VERSION ""

NS_ :

BS_:

BU_: SOBDMB_AWDC BCMC_CPDB BECMB_EPM PACM GWM _delete BCM ACCM DCDC_HEV GENERIC TSTR

BO_ 753 Vehicle_Stat_Data: 8 GWM
 SG_ EdmSailMde_B_RqDrv_UB : 34|1@0+ (1,0) [0|1] "SED" Vector__XXX
 SG_ TurnLampRrOut_B_Stat_UB : 36|1@0+ (1,0) [0|1] "SED"  BCM
 SG_ TurnLampRrOut_B_Stat : 37|1@0+ (1,0) [0|1] "SED"  BCM
 SG_ TurnLampRlOut_B_Stat_UB : 38|1@0+ (1,0) [0|1] "SED"  BCM
 SG_ TurnLampRlOut_B_Stat : 39|1@0+ (1,0) [0|1] "SED"  BCM
 SG_ CnvtTopPos_Up_Stat_UB : 24|1@0+ (1,0) [0|1] "SED"  BCM
 SG_ GlvBoxRleas_No_Actl : 31|3@0+ (1,0) [0|7] "unitless"  BCM
 SG_ GlvBoxRleas_No_Actl_UB : 28|1@0+ (1,0) [0|1] "SED"  BCM
 SG_ ValetMode_D_Stat_UB : 20|1@0+ (1,0) [0|1] "SED"  BCM
 SG_ RollCodeValet_UB : 21|1@0+ (1,0) [0|1] "SED"  BCM
 SG_ ApaMdeStat_D_RqDrv_UB : 16|1@0+ (1,0) [0|1] "SED" Vector__XXX
 SG_ EdmSailMde_B_RqDrv : 35|1@0+ (1,0) [0|1] "SED" Vector__XXX
 SG_ LpdbPtc3_B_Rq : 42|1@0+ (1,0) [0|1] "SED"  BCM
 SG_ LpdbPtc2_B_Rq : 43|1@0+ (1,0) [0|1] "SED"  BCM
 SG_ LpdbPtc1_B_Rq : 44|1@0+ (1,0) [0|1] "SED"  BCM
 SG_ Em_D_Stat_UB : 54|1@0+ (1,0) [0|1] "SED"  BCM
 SG_ LpdbHeatWiprPrk_B_Rq : 45|1@0+ (1,0) [0|1] "SED"  BCM
 SG_ LpdbDfrstRearOn_B_Rq_UB : 41|1@0+ (1,0) [0|1] "SED"  BCM
 SG_ LpdbDfrstRearOn_B_Rq : 46|1@0+ (1,0) [0|1] "SED"  BCM
 SG_ LpdbDfrstFrOn_B_Rq : 47|1@0+ (1,0) [0|1] "SED"  BCM
 SG_ LpdbDfrstFlOn_B_Rq : 32|1@0+ (1,0) [0|1] "SED"  BCM
 SG_ LpdbAuxBlwr_B_Rq : 33|1@0+ (1,0) [0|1] "SED"  BCM
 SG_ ApaMdeStat_D_RqDrv : 19|3@0+ (1,0) [0|7] "SED" Vector__XXX
 SG_ Em_D_Stat : 40|2@0+ (1,0) [0|3] "SED"  BCM
 SG_ PrkAidSwtch_No_Cnt : 52|4@0+ (1,0) [0|15] "Unitless" Vector__XXX
 SG_ PrkAidSwtch_D_RqDrv : 53|1@0+ (1,0) [0|1] "SED" Vector__XXX
 SG_ PrkAidSwtch_D_RqDrv_UB : 48|1@0+ (1,0) [0|1] "SED" Vector__XXX
 SG_ ValetMode_D_Stat : 23|2@0+ (1,0) [0|3] "SED"  BCM
 SG_ RollCodeValet : 7|16@0+ (1,0) [0|65535] "Unitless"  BCM
 SG_ CnvtTopPos_Up_Stat : 25|1@0+ (1,0) [0|1] "SED"  BCM
 SG_ CnvtTopPos_Dn_Stat_UB : 26|1@0+ (1,0) [0|1] "SED"  BCM
 SG_ CnvtTopPos_Dn_Stat : 27|1@0+ (1,0) [0|1] "SED"  BCM

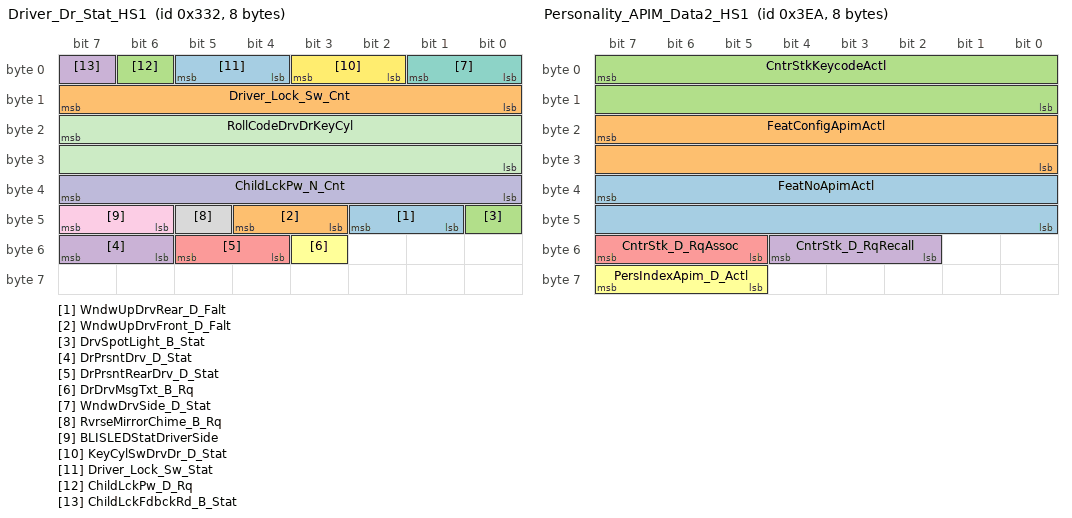
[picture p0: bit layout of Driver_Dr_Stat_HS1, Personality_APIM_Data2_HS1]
BO_ 818 Driver_Dr_Stat_HS1: 8 GWM
 SG_ WndwUpDrvRear_D_Falt : 42|2@0+ (1,0) [0|3] "SED"  GENERIC
 SG_ WndwUpDrvFront_D_Falt : 44|2@0+ (1,0) [0|3] "SED"  GENERIC
 SG_ DrvSpotLight_B_Stat : 40|1@0+ (1,0) [0|1] "SED"  GENERIC
 SG_ DrPrsntDrv_D_Stat : 55|2@0+ (1,0) [0|3] "SED" Vector__XXX
 SG_ DrPrsntRearDrv_D_Stat : 53|2@0+ (1,0) [0|3] "SED" Vector__XXX
 SG_ DrDrvMsgTxt_B_Rq : 51|1@0+ (1,0) [0|1] "SED"  GENERIC
 SG_ WndwDrvSide_D_Stat : 1|2@0+ (1,0) [0|3] "SED"  GENERIC
 SG_ RvrseMirrorChime_B_Rq : 45|1@0+ (1,0) [0|1] "SED"  GENERIC
 SG_ BLISLEDStatDriverSide : 47|2@0+ (1,0) [0|3] "SED"  GENERIC
 SG_ ChildLckPw_N_Cnt : 39|8@0+ (1,0) [0|255] "unitless"  BCM
 SG_ RollCodeDrvDrKeyCyl : 23|16@0+ (1,0) [0|65535] "Unitless"  BCM
 SG_ KeyCylSwDrvDr_D_Stat : 3|2@0+ (1,0) [0|3] "SED"  BCM
 SG_ Driver_Lock_Sw_Stat : 5|2@0+ (1,0) [0|3] "SED"  BCM
 SG_ Driver_Lock_Sw_Cnt : 15|8@0+ (1,0) [0|255] "Cnt"  BCM
 SG_ ChildLckPw_D_Rq : 6|1@0+ (1,0) [0|1] "SED"  BCM
 SG_ ChildLckFdbckRd_B_Stat : 7|1@0+ (1,0) [0|1] "SED"  BCM

BO_ 817 Locking_Systems_2: 8 BCM
 SG_ ChildLckMde_B_Stat : 56|1@0+ (1,0) [0|1] "SED"  GWM
 SG_ VehLckInd_D_Rq : 58|2@0+ (1,0) [0|3] "SED"  GWM
 SG_ DrTgateOpen_B_Rq : 59|1@0+ (1,0) [0|1] "SED"  GWM
 SG_ DrTgateExtSwMde_B_Stat : 32|1@0+ (1,0) [0|1] "SED"  GWM
 SG_ Remote_Device_Feedback : 50|3@0+ (1,0) [0|7] "SED"  GWM
 SG_ Veh_Lock_Requestor : 55|5@0+ (1,0) [0|31] "SED"  GWM
 SG_ R_Pwr_Sliding_Dr_Rqst : 36|1@0+ (1,0) [0|1] "SED"  GWM
 SG_ Power_Liftgate_Rqst : 0|1@0+ (1,0) [0|1] "SED"  GWM
 SG_ Veh_Lock_EvNum : 47|8@0+ (1,0) [0|255] "unitless"  GWM
 SG_ Power_Decklid_Rqst : 1|1@0+ (1,0) [0|1] "SED"  GWM
 SG_ L_Pwr_Sliding_Dr_Rqst : 3|1@0+ (1,0) [0|1] "SED"  GWM
 SG_ Keyfob_Pad_Msg_Count : 15|8@0+ (1,0) [0|255] "Counts"  GWM
 SG_ Veh_Lock_Sub_Id : 63|4@0+ (1,0) [0|15] "SED"  GWM
 SG_ Veh_Lock_Status : 34|2@0+ (1,0) [0|3] "SED"  GWM
 SG_ ChildLck_D_Dsply : 7|2@0+ (1,0) [0|3] "SED"  GWM
 SG_ WindowLockout_B_Stat : 35|1@0+ (1,0) [0|1] "SED"  GWM
 SG_ RollCodeUnlock : 23|16@0+ (1,0) [0|65535] "Unitless"  GWM
 SG_ Lockmsgtxt_D_Rq : 39|3@0+ (1,0) [0|7] "SED"  GWM
 SG_ FobComm_D_Stat : 5|2@0+ (1,0) [0|3] "SED"  GWM
 SG_ LockInhibit : 2|1@0+ (1,0) [0|1] "SED"  GWM

BO_ 1002 Personality_APIM_Data2_HS1: 8 GWM
 SG_ FeatNoApimActl : 39|16@0+ (1,0) [0|65535] "Number"  GENERIC
 SG_ FeatConfigApimActl : 23|16@0+ (1,0) [0|65535] "Number"  GENERIC
 SG_ CntrStkKeycodeActl : 7|16@0+ (1,0) [0|65535] "Undefined"  BCM
 SG_ CntrStk_D_RqRecall : 52|3@0+ (1,0) [0|7] "SED"  BCM
 SG_ CntrStk_D_RqAssoc : 55|3@0+ (1,0) [0|7] "SED"  BCM
 SG_ PersIndexApim_D_Actl : 63|3@0+ (1,0) [0|7] "SED"  GENERIC

BO_ 1046 BrakeSysFeatures_2_HS1: 8 GWM
 SG_ BpedDiffLckTq_No_Cs : 23|8@0+ (1,0) [0|255] "Unitless" Vector__XXX
 SG_ PrkBrkDynmc_D_Allw : 39|2@0+ (1,0) [0|3] "SED"  GENERIC
 SG_ BrkPrkBrkDynmc_B_Actl : 24|1@0+ (1,0) [0|1] "SED"  GENERIC
 SG_ TRLR_SWAY_EVNT_IN_PROG : 25|1@0+ (1,0) [0|1] "SED"  GENERIC
 SG_ TRLR_SWAY_CONFIG_STAT : 26|1@0+ (1,0) [0|1] "SED"  GENERIC
 SG_ ReserveTracCtlPtActv : 28|1@0+ (1,0) [0|1] "SED"  GENERIC
 SG_ HsaMde_D_Mem : 33|2@0+ (1,0) [0|3] "SED"  GENERIC
 SG_ BrkBstrVac_B_Rq : 27|1@0+ (1,0) [0|1] "Discrete" Vector__XXX
 SG_ DrvSlipCtlMde_D_Ind : 44|2@0+ (1,0) [0|3] "SED" Vector__XXX
 SG_ DrvAntiLckLamp_D_Rq : 55|2@0+ (1,0) [0|3] "SED" Vector__XXX
 SG_ StabCtlBrk_B_Avail : 4|1@0+ (1,0) [0|1] "SED" Vector__XXX
 SG_ DrvHdcWarnInfo_D_Rq : 35|2@0+ (1,0) [0|3] "SED" Vector__XXX
 SG_ DrvHdcMsg_D_Rq : 10|3@0+ (1,0) [0|7] "SED" Vector__XXX
 SG_ DrvHdcLampInfo_D_Rq : 12|2@0+ (1,0) [0|3] "SED" Vector__XXX
 SG_ ChimeBrk_B_Rq : 14|1@0+ (1,0) [0|1] "SED" Vector__XXX
 SG_ BrkLamp_B_Rq : 13|1@0+ (1,0) [0|1] "SED" Vector__XXX
 SG_ HILL_DESC_MC : 47|3@0+ (1,0) [0|7] "SED" Vector__XXX
 SG_ RearDiffLck_Tq2_RqMx : 51|12@0+ (4,0) [0|16376] "Nm" Vector__XXX
 SG_ HdcMde_D_Actl : 31|3@0+ (1,0) [0|7] "SED" Vector__XXX
 SG_ TCMode : 15|1@0+ (1,0) [0|1] "SED" Vector__XXX
 SG_ DrvSlipCtlLamp_D_Rq : 42|2@0+ (1,0) [0|3] "SED" Vector__XXX
 SG_ Abs_B_Falt : 5|1@0+ (1,0) [0|1] "SED" Vector__XXX
 SG_ RearDiffElckrOpen_B_Rq : 40|1@0+ (1,0) [0|1] "SED"  GENERIC
 SG_ BpedMove_No_Cnt : 3|4@0+ (1,0) [0|15] "Unitless" Vector__XXX
 SG_ BpedMove_D_Actl : 7|2@0+ (1,0) [0|3] "SED" Vector__XXX

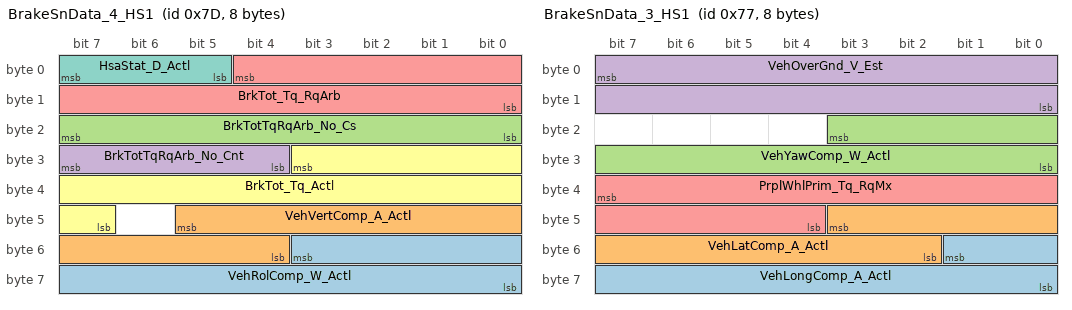
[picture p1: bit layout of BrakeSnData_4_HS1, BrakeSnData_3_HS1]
BO_ 125 BrakeSnData_4_HS1: 8 GWM
 SG_ VehRolComp_W_Actl : 51|12@0+ (0.03663,-75) [-75|74.92659] "degrees/sec" Vector__XXX
 SG_ VehVertComp_A_Actl : 45|10@0+ (0.035,-17.9) [-17.9|17.835] "m/s^2" Vector__XXX
 SG_ BrkTotTqRqArb_No_Cs : 23|8@0+ (1,0) [0|255] "Unitless" Vector__XXX
 SG_ BrkTotTqRqArb_No_Cnt : 31|4@0+ (1,0) [0|15] "Unitless" Vector__XXX
 SG_ BrkTot_Tq_RqArb : 4|13@0+ (4,0) [0|32756] "Nm" Vector__XXX
 SG_ BrkTot_Tq_Actl : 27|13@0+ (4,0) [0|32756] "Nm"  GENERIC
 SG_ HsaStat_D_Actl : 7|3@0+ (1,0) [0|7] "SED"  GENERIC

BO_ 119 BrakeSnData_3_HS1: 8 GWM
 SG_ VehLongComp_A_Actl : 49|10@0+ (0.035,-17.9) [-17.9|17.835] "m/s^2" Vector__XXX
 SG_ VehLatComp_A_Actl : 43|10@0+ (0.035,-17.9) [-17.9|17.835] "m/s^2" Vector__XXX
 SG_ VehYawComp_W_Actl : 19|12@0+ (0.03663,-75) [-75|74.92659] "deg/s" Vector__XXX
 SG_ VehOverGnd_V_Est : 7|16@0+ (0.01,0) [0|655.33] "kph" Vector__XXX
 SG_ PrplWhlPrim_Tq_RqMx : 39|12@0+ (8,0) [0|32760] "Nm"  GENERIC

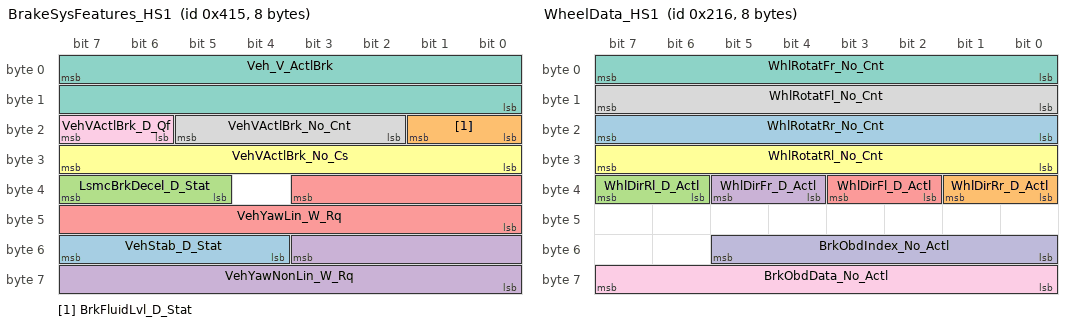
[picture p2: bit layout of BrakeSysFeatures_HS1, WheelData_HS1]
BO_ 1045 BrakeSysFeatures_HS1: 8 GWM
 SG_ VehStab_D_Stat : 55|4@0+ (1,0) [0|15] "SED" Vector__XXX
 SG_ BrkFluidLvl_D_Stat : 17|2@0+ (1,0) [0|3] "SED"  BCM
 SG_ LsmcBrkDecel_D_Stat : 39|3@0+ (1,0) [0|7] "SED"  GENERIC
 SG_ VehYawNonLin_W_Rq : 51|12@0+ (0.03663,-75) [-75|74.92659] "deg/s" Vector__XXX
 SG_ VehYawLin_W_Rq : 35|12@0+ (0.03663,-75) [-75|74.92659] "deg/s" Vector__XXX
 SG_ VehVActlBrk_No_Cs : 31|8@0+ (1,0) [0|255] "Unitless"  SOBDMB_AWDC,BCM
 SG_ Veh_V_ActlBrk : 7|16@0+ (0.01,0) [0|655.35] "kph"  SOBDMB_AWDC,BCM
 SG_ VehVActlBrk_No_Cnt : 21|4@0+ (1,0) [0|15] "Unitless"  SOBDMB_AWDC,BCM
 SG_ VehVActlBrk_D_Qf : 23|2@0+ (1,0) [0|3] "SED"  SOBDMB_AWDC,BCM

BO_ 534 WheelData_HS1: 8 GWM
 SG_ WhlRotatRr_No_Cnt : 23|8@0+ (1,0) [0|255] "Unitless"  BCM
 SG_ WhlDirRr_D_Actl : 33|2@0+ (1,0) [0|3] "SED" Vector__XXX
 SG_ WhlDirRl_D_Actl : 39|2@0+ (1,0) [0|3] "SED" Vector__XXX
 SG_ WhlDirFr_D_Actl : 37|2@0+ (1,0) [0|3] "SED" Vector__XXX
 SG_ WhlDirFl_D_Actl : 35|2@0+ (1,0) [0|3] "SED" Vector__XXX
 SG_ WhlRotatRl_No_Cnt : 31|8@0+ (1,0) [0|255] "Unitless"  BCM
 SG_ WhlRotatFr_No_Cnt : 7|8@0+ (1,0) [0|255] "Unitless"  BCM
 SG_ WhlRotatFl_No_Cnt : 15|8@0+ (1,0) [0|255] "Unitless"  BCM
 SG_ BrkObdData_No_Actl : 63|8@0+ (1,0) [0|255] "unitless" Vector__XXX
 SG_ BrkObdIndex_No_Actl : 53|6@0+ (1,0) [0|63] "unitless" Vector__XXX

BO_ 531 DesiredTorqBrk_HS1: 8 GWM
 SG_ VehStop_D_Stat : 28|2@0+ (1,0) [0|3] "SED"  GENERIC
 SG_ TracCtlPtActv_B_Actl : 31|1@0+ (1,0) [0|1] "SED"  GENERIC
 SG_ LscmbbMntr_B_Err : 17|1@0+ (1,0) [0|1] "SED"  GENERIC
 SG_ LscmbbBrkDis_B_Actl : 19|1@0+ (1,0) [0|1] "SED"  GENERIC
 SG_ StabCtlBrkActv_B_Actl : 23|1@0+ (1,0) [0|1] "SED"  GENERIC
 SG_ CmbbBrkPrchg_B_Actl : 59|1@0+ (1,0) [0|1] "SED"  GENERIC
 SG_ CmbbBrkDecel_B_Actl : 58|1@0+ (1,0) [0|1] "SED"  GENERIC
 SG_ CmbbBaSensInc_B_Actl : 57|1@0+ (1,0) [0|1] "SED"  GENERIC
 SG_ AccBrkWarm_B_Actl : 63|1@0+ (1,0) [0|1] "SED"  GENERIC
 SG_ AccBrkTotTqMn_B_Actl : 62|1@0+ (1,0) [0|1] "SED"  GENERIC
 SG_ AccBrkPrchgActv_B_Actl : 61|1@0+ (1,0) [0|1] "SED"  GENERIC
 SG_ AccBrkDis_B_Actl : 44|1@0+ (1,0) [0|1] "SED"  GENERIC
 SG_ AccBrkDeny_B_Actl : 42|1@0+ (1,0) [0|1] "SED"  GENERIC
 SG_ AccBrkActv_B_Actl : 43|1@0+ (1,0) [0|1] "SED"  GENERIC
 SG_ PrplDrgCtlActv_B_Actl : 46|1@0+ (1,0) [0|1] "SED"  GENERIC
 SG_ PrplWhlTot_Tq_RqMx : 7|16@0+ (4,-131072) [-131072|131068] "Nm"  GENERIC
 SG_ AbsActv_B_Actl : 45|1@0+ (1,0) [0|1] "SED"  SOBDMB_AWDC,GENERIC
 SG_ CmbbBrkDis_B_Actl : 56|1@0+ (1,0) [0|1] "SED"  GENERIC
 SG_ CmbbDeny_B_ActlBrk : 60|1@0+ (1,0) [0|1] "SED"  GENERIC
 SG_ CcDis_B_Cmd : 47|1@0+ (1,0) [0|1] "SED"  GENERIC
 SG_ VehLongOvrGnd_A_Est : 41|10@0+ (0.035,-17.9) [-17.9|17.835] "m/s^2"  GENERIC
 SG_ AccStopActv_B_ActlBrk : 22|1@0+ (1,0) [0|1] "SED"  GENERIC
 SG_ AccDis_B_ActlEpb : 32|1@0+ (1,0) [0|1] "SED"  GENERIC
 SG_ PrkBrkYwLamp_D_Rq : 38|2@0+ (1,0) [0|3] "SED"  GENERIC
 SG_ PrkBrkRedLamp_D_Rq : 30|2@0+ (1,0) [0|3] "SED"  GENERIC
 SG_ PrkBrkMsgTxt_D_Rq : 36|4@0+ (1,0) [0|15] "SED"  GENERIC
 SG_ PrkBrkStatus : 26|3@0+ (1,0) [0|7] "SED"  GENERIC,BCM
 SG_ VehicleStationary : 39|1@0+ (1,0) [0|1] "SED"  GENERIC
 SG_ LscmbbDeny_B_ActlBrk : 18|1@0+ (1,0) [0|1] "SED"  GENERIC
 SG_ LscmbbBrkDecel_B_Actl : 20|1@0+ (1,0) [0|1] "SED"  GENERIC
 SG_ LscmbbBaSensInc_B_Actl : 21|1@0+ (1,0) [0|1] "SED"  GENERIC
 SG_ LscmbBrkPrchg_B_Actl : 16|1@0+ (1,0) [0|1] "SED"  GENERIC

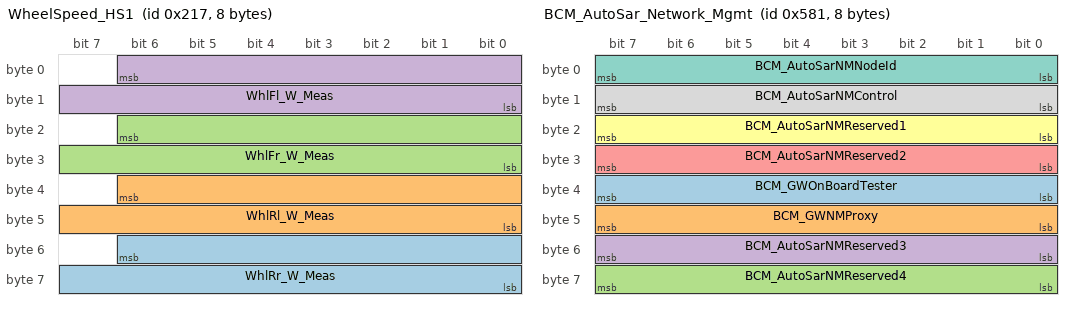
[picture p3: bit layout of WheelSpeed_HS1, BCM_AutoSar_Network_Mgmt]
BO_ 535 WheelSpeed_HS1: 8 GWM
 SG_ WhlRr_W_Meas : 54|15@0+ (0.01,0) [0|327.65] "rad/s"  SOBDMB_AWDC
 SG_ WhlRl_W_Meas : 38|15@0+ (0.01,0) [0|327.65] "rad/s"  SOBDMB_AWDC
 SG_ WhlFr_W_Meas : 22|15@0+ (0.01,0) [0|327.65] "rad/s"  SOBDMB_AWDC
 SG_ WhlFl_W_Meas : 6|15@0+ (0.01,0) [0|327.65] "rad/s"  SOBDMB_AWDC

BO_ 611 Driveline_Data_1_HS1: 8 GWM
 SG_ AwdTerrMdeChng_D_Rdy : 58|3@0+ (1,0) [0|7] "SED"  GENERIC
 SG_ AwdTerrMde_D_Actl : 50|3@0+ (1,0) [0|7] "SED"  GENERIC
 SG_ AwdSys_D_Stat : 27|2@0+ (1,0) [0|3] "SED"  GENERIC
 SG_ SelDrvMdeAwd_D_Stat : 33|2@0+ (1,0) [0|3] "SED"  GENERIC
 SG_ AwdStat_D_RqDsply : 63|5@0+ (1,0) [0|31] "SED"  GENERIC
 SG_ AwdLck_D_Stat : 31|4@0+ (1,0) [0|15] "SED"  GENERIC
 SG_ AwdSrvcRqd_B_Rq : 0|1@0+ (1,0) [0|1] "SED"  GENERIC
 SG_ AwdDrvMde_D_Stat : 38|3@0+ (1,0) [0|7] "SED"  GENERIC
 SG_ NtrlTowAvail_B_Stat : 4|1@0+ (1,0) [0|1] "SED"  GENERIC
 SG_ AwdLck_Tq_Rq : 15|12@0+ (1,0) [0|4093] "Nm" Vector__XXX
 SG_ TrnAout_Tq_RqMx : 47|13@0+ (1,-1250) [-1250|6941] "Nm"  GENERIC
 SG_ AwdOffRoadMode_D_Stats : 25|2@0+ (1,0) [0|3] "SED"  GENERIC
 SG_ AwdLoLamp_D_RqDsply : 35|2@0+ (1,0) [0|3] "SED"  GENERIC
 SG_ AwdHiLamp_D_RqDsply : 19|2@0+ (1,0) [0|3] "SED"  GENERIC
 SG_ AwdAutoLamp_D_RqDsply : 17|2@0+ (1,0) [0|3] "SED"  GENERIC
 SG_ Awd2wdLamp_D_RqDsply : 2|2@0+ (1,0) [0|3] "SED"  GENERIC
 SG_ AwdRnge_D_Actl : 7|3@0+ (1,0) [0|7] "SED" Vector__XXX

BO_ 1409 BCM_AutoSar_Network_Mgmt: 8 BCM
 SG_ BCM_GWOnBoardTester : 39|8@0+ (1,0) [0|255] "unitless"  BECMB_EPM,GWM
 SG_ BCM_GWNMProxy : 47|8@0+ (1,0) [0|255] "unitless"  BECMB_EPM,GWM
 SG_ BCM_AutoSarNMReserved4 : 63|8@0+ (1,0) [0|255] "unitless"  BECMB_EPM,GWM
 SG_ BCM_AutoSarNMReserved3 : 55|8@0+ (1,0) [0|255] "unitless"  BECMB_EPM,GWM
 SG_ BCM_AutoSarNMReserved2 : 31|8@0+ (1,0) [0|255] "unitless"  BECMB_EPM,GWM
 SG_ BCM_AutoSarNMReserved1 : 23|8@0+ (1,0) [0|255] "unitless"  BECMB_EPM,GWM
 SG_ BCM_AutoSarNMNodeId : 7|8@0+ (1,0) [0|255] "unitless"  BECMB_EPM,GWM
 SG_ BCM_AutoSarNMControl : 15|8@0+ (1,0) [0|255] "unitless"  BECMB_EPM,GWM

BO_ 90 Gear_Shift_by_Wire_HS1: 8 GWM
 SG_ TrnGsmNtmState_D_Actl : 55|2@0+ (1,0) [0|3] "SED"  GENERIC
 SG_ DrQltyDrv_D_StatGsm : 42|3@0+ (1,0) [0|7] "SED"  GENERIC
 SG_ TrnBtsiOvrrd_B_Stat : 43|1@0+ (1,0) [0|1] "SED"  GENERIC
 SG_ GsmGearMsgTxt_D_Rq : 63|2@0+ (1,0) [0|3] "SED"  GENERIC
 SG_ TrnRng_D_RqGsm : 51|4@0+ (1,0) [0|15] "SED"  GENERIC
 SG_ PrkBrkActv_D_RqGsmGear : 53|2@0+ (1,0) [0|3] "SED"  GENERIC
 SG_ TrnValidGearRq_D_Stat : 25|2@0+ (1,0) [0|3] "SED"  GENERIC
 SG_ TrnGearRqCnt_B_Actl : 26|1@0+ (1,0) [0|1] "unitless"  GENERIC
 SG_ TrnGearButtn_U_Actl : 23|8@0+ (0.05,0) [0|12.7] "VOLT"  GENERIC
 SG_ TrnGearButtn_B_ActlR2 : 8|1@0+ (1,0) [0|1] "SED"  GENERIC
 SG_ TrnGearButtn_B_ActlR1 : 9|1@0+ (1,0) [0|1] "SED"  GENERIC
 SG_ TrnGearButtn_B_ActlR0 : 10|1@0+ (1,0) [0|1] "SED"  GENERIC
 SG_ TrnGearButtn_B_ActlP2 : 11|1@0+ (1,0) [0|1] "SED"  GENERIC
 SG_ TrnGearButtn_B_ActlP1 : 12|1@0+ (1,0) [0|1] "SED"  GENERIC
 SG_ TrnGearButtn_B_ActlP0 : 13|1@0+ (1,0) [0|1] "SED"  GENERIC
 SG_ TrnGearButtn_B_ActlN2 : 14|1@0+ (1,0) [0|1] "SED"  GENERIC
 SG_ TrnGearButtn_B_ActlN1 : 15|1@0+ (1,0) [0|1] "SED"  GENERIC
 SG_ TrnGearButtn_B_ActlN0 : 0|1@0+ (1,0) [0|1] "SED"  GENERIC
 SG_ TrnGearButtn_B_ActlM2 : 1|1@0+ (1,0) [0|1] "SED"  GENERIC
 SG_ TrnGearButtn_B_ActlM1 : 2|1@0+ (1,0) [0|1] "SED"  GENERIC
 SG_ TrnGearButtn_B_ActlM0 : 3|1@0+ (1,0) [0|1] "SED"  GENERIC
 SG_ TrnGearButtn_B_ActlD2 : 4|1@0+ (1,0) [0|1] "SED"  GENERIC
 SG_ TrnGearButtn_B_ActlD1 : 5|1@0+ (1,0) [0|1] "SED"  GENERIC
 SG_ TrnGearButtn_B_ActlD0 : 6|1@0+ (1,0) [0|1] "SED"  GENERIC
 SG_ TrnGear_No_Cs : 39|8@0+ (1,0) [0|255] "Unitless"  GENERIC
 SG_ TrnGear_No_Cnt : 47|4@0+ (1,0) [0|15] "Unitless"  GENERIC
 SG_ TrnGear_D_RqDrv : 31|5@0+ (1,0) [0|31] "SED"  GENERIC,BCM
 SG_ BrkSwtchPos_B_ActlGsm : 7|1@0+ (1,0) [0|1] "SED"  GENERIC

BO_ 1109 eCall_Info_HS1: 8 GWM
 SG_ eCallConfirmation : 7|3@0+ (1,0) [0|7] "SED"  BCM

BO_ 92 Gear_Shift_by_Wire_3_HS1: 8 GWM
 SG_ TrnGearMsgTxt2_D_Rq : 53|5@0+ (1,0) [0|31] "SED"  GENERIC
 SG_ RaceTrakMde_D_Stat : 55|2@0+ (1,0) [0|3] "SED"  SOBDMB_AWDC
 SG_ TrnLvrV_D_Rq : 43|2@0+ (1,0) [0|3] "SED"  GENERIC
 SG_ TrnSbwSysHlth_D_Actl : 1|2@0+ (1,0) [0|3] "SED"  GENERIC
 SG_ TrnGearNtmAllow_B_Stat : 47|1@0+ (1,0) [0|1] "SED"  GENERIC
 SG_ TrnDtpCmd_D_Actl : 46|3@0+ (1,0) [0|7] "SED"  GENERIC
 SG_ GearSelLck_D_Rq : 41|2@0+ (1,0) [0|3] "SED"  GENERIC
 SG_ TrnGearCmd_No_Cs : 31|8@0+ (1,0) [0|255] "Unitless"  GENERIC
 SG_ TrnValidGear_D_Cnfm : 11|2@0+ (1,0) [0|3] "SED"  GENERIC
 SG_ TrnNtrlTowCmd_D_Actl : 6|2@0+ (1,0) [0|3] "SED"  GENERIC
 SG_ TrnGearCmd_Pc_ActlPt : 9|10@0+ (0.1,0) [0|102.2] "percent duty cycle"  GENERIC
 SG_ TrnGear_D_RqPt : 4|3@0+ (1,0) [0|7] "SED"  SOBDMB_AWDC
 SG_ TrnCmdState_B_Actl : 39|1@0+ (1,0) [0|1] "SED"  GENERIC
 SG_ TrnCmdCnt_B_Actl : 7|1@0+ (1,0) [0|1] "unitless"  GENERIC
 SG_ PrkBrkActv_D_RqTrnGear : 38|2@0+ (1,0) [0|3] "SED"  GENERIC
 SG_ TrnGearMsgTxt_D_Rq : 36|5@0+ (1,0) [0|31] "SED"  GENERIC
 SG_ TrnGearCmd_No_Cnt : 15|4@0+ (1,0) [0|15] "Unitless"  GENERIC

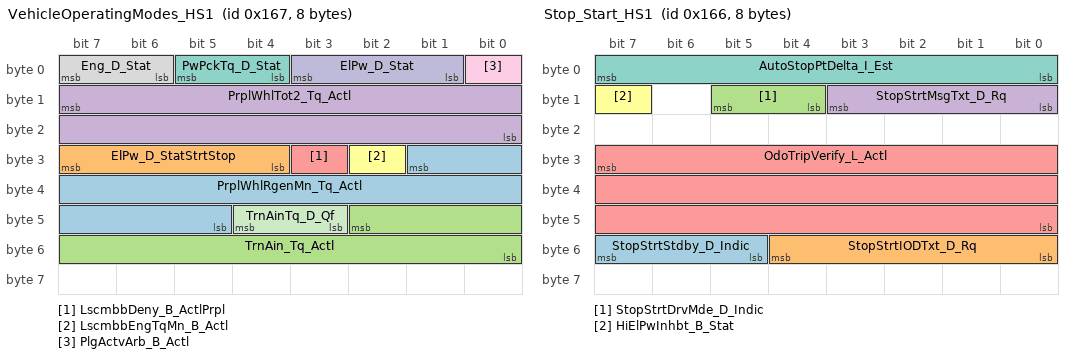
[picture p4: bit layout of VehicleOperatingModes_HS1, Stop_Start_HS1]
BO_ 359 VehicleOperatingModes_HS1: 8 GWM
 SG_ PrplWhlRgenMn_Tq_Actl : 25|13@0+ (4,-16380) [-16380|16380] "Nm" Vector__XXX
 SG_ ElPw_D_StatStrtStop : 31|4@0+ (1,0) [0|15] "SED" Vector__XXX
 SG_ TrnAin_Tq_Actl : 42|11@0+ (1,-500) [-500|1547] "Nm" Vector__XXX
 SG_ PrplWhlTot2_Tq_Actl : 15|16@0+ (4,-131072) [-131072|131060] "Nm" Vector__XXX
 SG_ LscmbbDeny_B_ActlPrpl : 27|1@0+ (1,0) [0|1] "SED" Vector__XXX
 SG_ LscmbbEngTqMn_B_Actl : 26|1@0+ (1,0) [0|1] "SED" Vector__XXX
 SG_ PwPckTq_D_Stat : 5|2@0+ (1,0) [0|3] "SED"  SOBDMB_AWDC,BCMC_CPDB,PACM,ACCM,DCDC_HEV,BCM
 SG_ Eng_D_Stat : 7|2@0+ (1,0) [0|3] "SED"  BCM
 SG_ PlgActvArb_B_Actl : 0|1@0+ (1,0) [0|1] "SED"  BCM
 SG_ ElPw_D_Stat : 3|3@0+ (1,0) [0|7] "SED"  BCMC_CPDB,BCM
 SG_ TrnAinTq_D_Qf : 44|2@0+ (1,0) [0|3] "SED" Vector__XXX

BO_ 358 Stop_Start_HS1: 8 GWM
 SG_ StopStrtStdby_D_Indic : 55|3@0+ (1,0) [0|7] "SED"  GENERIC
 SG_ StopStrtIODTxt_D_Rq : 52|5@0+ (1,0) [0|31] "SED"  GENERIC
 SG_ StopStrtDrvMde_D_Indic : 13|2@0+ (1,0) [0|3] "SED"  BCM
 SG_ StopStrtMsgTxt_D_Rq : 11|4@0+ (1,0) [0|15] "SED"  GENERIC
 SG_ OdoTripVerify_L_Actl : 31|24@0+ (0.1,0) [0|1677721.4] "km"  GENERIC
 SG_ HiElPwInhbt_B_Stat : 15|1@0+ (1,0) [0|1] "SED"  GENERIC
 SG_ AutoStopPtDelta_I_Est : 7|8@0+ (1,-127) [-127|127] "Amps"  BCM

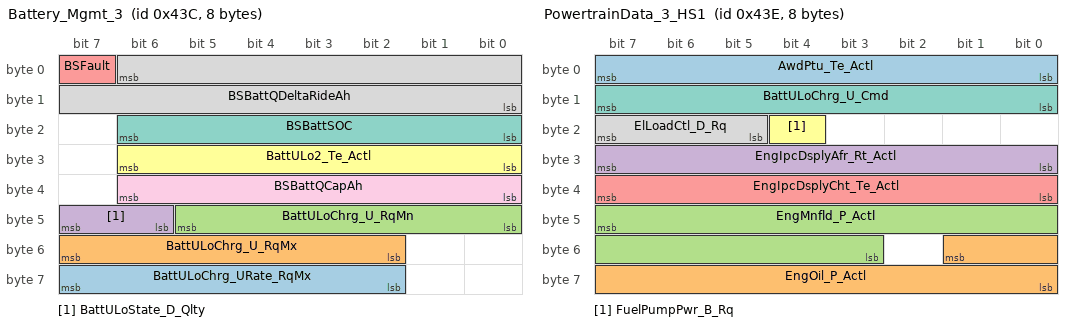
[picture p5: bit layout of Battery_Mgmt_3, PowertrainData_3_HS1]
BO_ 1084 Battery_Mgmt_3: 8 BCM
 SG_ BattULoChrg_URate_RqMx : 63|6@0+ (0.1,0) [0|6.3] "volts/second"  GWM
 SG_ BattULoChrg_U_RqMx : 55|6@0+ (0.1,10.6) [10.6|16.9] "volt"  GWM
 SG_ BattULoChrg_U_RqMn : 45|6@0+ (0.1,10.6) [10.6|16.9] "volt"  GWM
 SG_ BattULoState_D_Qlty : 47|2@0+ (1,0) [0|3] "SED"  GWM
 SG_ BSFault : 7|1@0+ (1,0) [0|1] "SED"  GWM
 SG_ BattULo2_Te_Actl : 30|7@0+ (1,-40) [-40|86] "degC"  GWM
 SG_ BSBattSOC : 22|7@0+ (1,0) [0|127] "%"  GWM
 SG_ BSBattQDeltaRideAh : 6|15@0+ (0.0078125,-100) [-100|155.9921875] "ampere*hour"  GWM
 SG_ BSBattQCapAh : 38|7@0+ (1,0) [0|127] "ampere*hour"  GWM

BO_ 1086 PowertrainData_3_HS1: 8 GWM
 SG_ AwdPtu_Te_Actl : 7|8@0+ (1,-50) [-50|204] "degC"  GENERIC
 SG_ EngOil_P_Actl : 49|10@0+ (1,0) [0|1023] "kilopascal" Vector__XXX
 SG_ EngMnfld_P_Actl : 47|13@0+ (0.1,-206.8) [-206.8|612.3] "kilopascal"  GENERIC
 SG_ EngIpcDsplyAfr_Rt_Actl : 31|8@0+ (0.1,0) [0|25.5] "unitless"  GENERIC
 SG_ EngIpcDsplyCht_Te_Actl : 39|8@0+ (1,-60) [-60|195] "degC"  GENERIC
 SG_ FuelPumpPwr_B_Rq : 20|1@0+ (1,0) [0|1] "SED"  BCM
 SG_ BattULoChrg_U_Cmd : 15|8@0+ (0.025,10.6) [10.6|16.975] "volt"  BCM,DCDC_HEV
 SG_ ElLoadCtl_D_Rq : 23|3@0+ (1,0) [0|7] "SED"  BCM

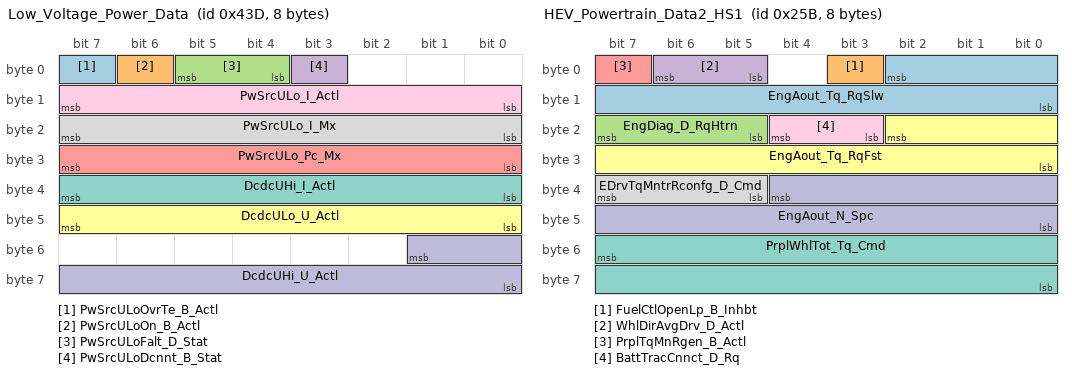
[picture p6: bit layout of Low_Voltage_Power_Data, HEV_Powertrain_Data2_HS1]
BO_ 1085 Low_Voltage_Power_Data: 8 DCDC_HEV
 SG_ PwSrcULoOvrTe_B_Actl : 7|1@0+ (1,0) [0|1] "SED"  GWM,BCM
 SG_ PwSrcULoOn_B_Actl : 6|1@0+ (1,0) [0|1] "SED"  GWM
 SG_ PwSrcULoFalt_D_Stat : 5|2@0+ (1,0) [0|3] "SED"  GWM,BCM
 SG_ PwSrcULoDcnnt_B_Stat : 3|1@0+ (1,0) [0|1] "SED"  GWM,BCM
 SG_ PwSrcULo_Pc_Mx : 31|8@0+ (0.4,0) [0|101.6] "%"  GWM,BCM
 SG_ DcdcULo_U_Actl : 47|8@0+ (0.1,0) [0|25.4] "Volts"  GWM
 SG_ DcdcUHi_I_Actl : 39|8@0+ (0.1,0) [0|25.4] "Amps"  BCM,GWM
 SG_ PwSrcULo_I_Mx : 23|8@0+ (1,0) [0|254] "ampere"  GWM,BCM
 SG_ PwSrcULo_I_Actl : 15|8@0+ (1,0) [0|254] "ampere"  GWM,BCM
 SG_ DcdcUHi_U_Actl : 49|10@0+ (0.5,0) [0|510.5] "V"  BCM,GWM

BO_ 891 Chassis_Data: 8 GWM
 SG_ CabnSndAmb2_Db_Actl_UB : 10|1@0+ (1,0) [0|1] "SED" Vector__XXX
 SG_ CabnSndAmb2_Db_Actl : 7|8@0+ (1,10) [10|264] "decibel" Vector__XXX

BO_ 603 HEV_Powertrain_Data2_HS1: 8 GWM
 SG_ EngAout_Tq_RqSlw : 2|11@0+ (1,-500) [-500|1547] "Nm"  GENERIC
 SG_ FuelCtlOpenLp_B_Inhbt : 3|1@0+ (1,0) [0|1] "SED"  GENERIC
 SG_ EngDiag_D_RqHtrn : 23|3@0+ (1,0) [0|7] "SED" Vector__XXX
 SG_ WhlDirAvgDrv_D_Actl : 6|2@0+ (1,0) [0|3] "SED" Vector__XXX
 SG_ PrplTqMnRgen_B_Actl : 7|1@0+ (1,0) [0|1] "SED" Vector__XXX
 SG_ EngAout_Tq_RqFst : 18|11@0+ (1,-500) [-500|1547] "Nm"  GENERIC
 SG_ PrplWhlTot_Tq_Cmd : 55|16@0+ (4,-131072) [-131072|131068] "Nm"  SOBDMB_AWDC,GENERIC
 SG_ EDrvTqMntrRconfg_D_Cmd : 39|3@0+ (1,0) [0|7] "SED"  GENERIC
 SG_ BattTracCnnct_D_Rq : 20|2@0+ (1,0) [0|3] "SED"  SOBDMB_AWDC
 SG_ EngAout_N_Spc : 36|13@0+ (2,0) [0|16382] "rpm"  GENERIC

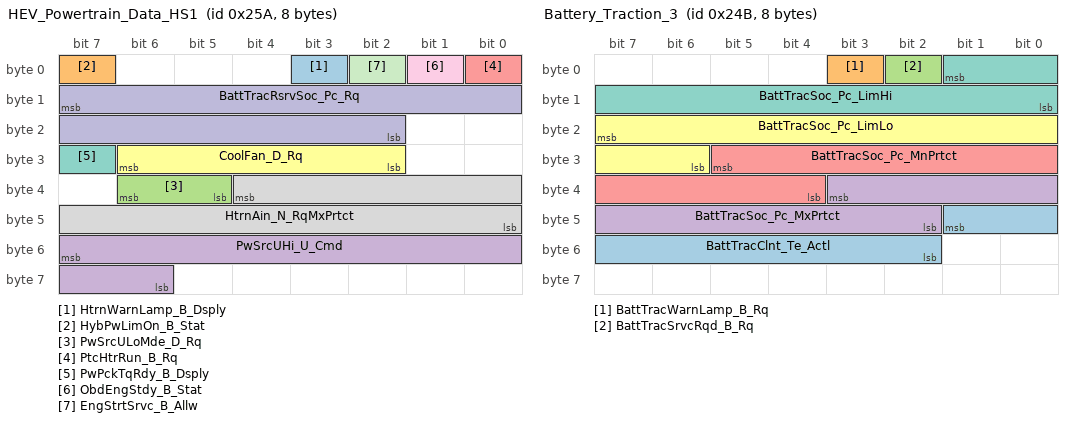
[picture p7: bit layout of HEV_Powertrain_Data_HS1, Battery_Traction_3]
BO_ 602 HEV_Powertrain_Data_HS1: 8 GWM
 SG_ HtrnWarnLamp_B_Dsply : 3|1@0+ (1,0) [0|1] "SED" Vector__XXX
 SG_ HybPwLimOn_B_Stat : 7|1@0+ (1,0) [0|1] "SED" Vector__XXX
 SG_ PwSrcULoMde_D_Rq : 38|2@0+ (1,0) [0|3] "SED" Vector__XXX
 SG_ PwSrcUHi_U_Cmd : 55|10@0+ (0.5,0) [0|511.5] "volt" Vector__XXX
 SG_ PtcHtrRun_B_Rq : 0|1@0+ (1,0) [0|1] "SED"  GENERIC
 SG_ CoolFan_D_Rq : 30|5@0+ (1,0) [0|31] "unitless"  GENERIC
 SG_ PwPckTqRdy_B_Dsply : 31|1@0+ (1,0) [0|1] "SED" Vector__XXX
 SG_ HtrnAin_N_RqMxPrtct : 36|13@0+ (2,0) [0|16382] "RPM"  GENERIC
 SG_ ObdEngStdy_B_Stat : 1|1@0+ (1,0) [0|1] "SED"  GENERIC
 SG_ BattTracRsrvSoc_Pc_Rq : 15|14@0+ (0.01,0) [0|163.81] "percent" Vector__XXX
 SG_ EngStrtSrvc_B_Allw : 2|1@0+ (1,0) [0|1] "SED"  GENERIC

BO_ 587 Battery_Traction_3: 8 GWM
 SG_ BattTracClnt_Te_Actl : 41|8@0+ (0.5,-60) [-60|66.5] "degC" Vector__XXX
 SG_ BattTracWarnLamp_B_Rq : 3|1@0+ (1,0) [0|1] "SED" Vector__XXX
 SG_ BattTracSrvcRqd_B_Rq : 2|1@0+ (1,0) [0|1] "SED" Vector__XXX
 SG_ BattTracSoc_Pc_MxPrtct : 35|10@0+ (0.1,0) [0|100] "%" Vector__XXX
 SG_ BattTracSoc_Pc_MnPrtct : 29|10@0+ (0.1,0) [0|100] "%" Vector__XXX
 SG_ BattTracSoc_Pc_LimLo : 23|10@0+ (0.1,0) [0|100] "%" Vector__XXX
 SG_ BattTracSoc_Pc_LimHi : 1|10@0+ (0.1,0) [0|100] "%" Vector__XXX

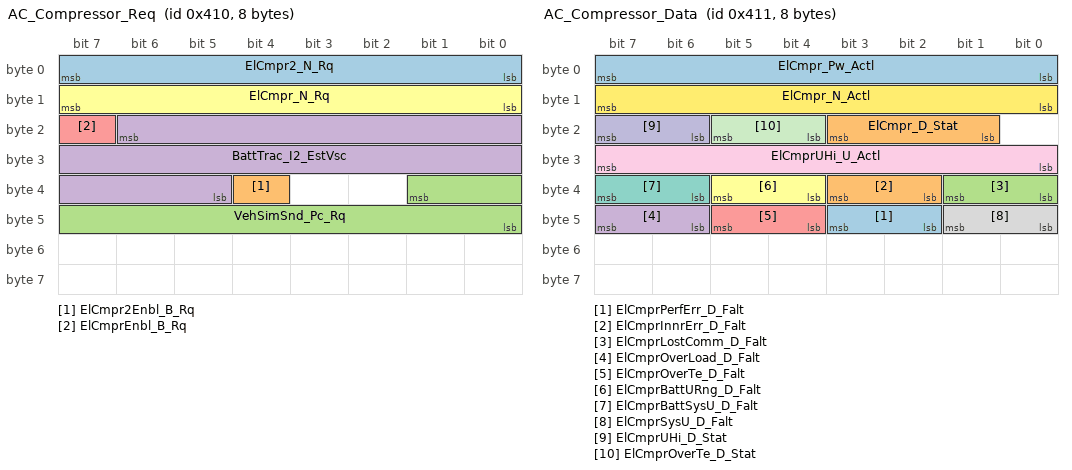
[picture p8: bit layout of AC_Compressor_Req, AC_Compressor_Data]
BO_ 1040 AC_Compressor_Req: 8 GWM
 SG_ ElCmpr2_N_Rq : 7|8@0+ (50,0) [0|12750] "RPM" Vector__XXX
 SG_ ElCmpr2Enbl_B_Rq : 36|1@0+ (1,0) [0|1] "SED" Vector__XXX
 SG_ VehSimSnd_Pc_Rq : 33|10@0+ (0.2,-102.2) [-102.2|102.4] "percent"  GENERIC
 SG_ BattTrac_I2_EstVsc : 22|18@0+ (0.05,-6553.52) [-6553.52|6553.53] "ampere" Vector__XXX
 SG_ ElCmprEnbl_B_Rq : 23|1@0+ (1,0) [0|1] "SED"  ACCM
 SG_ ElCmpr_N_Rq : 15|8@0+ (50,0) [0|12750] "RPM"  ACCM

BO_ 1041 AC_Compressor_Data: 8 ACCM
 SG_ ElCmprPerfErr_D_Falt : 43|2@0+ (1,0) [0|3] "SED"  GWM
 SG_ ElCmprInnrErr_D_Falt : 35|2@0+ (1,0) [0|3] "SED"  GWM
 SG_ ElCmprLostComm_D_Falt : 33|2@0+ (1,0) [0|3] "SED"  GWM
 SG_ ElCmprOverLoad_D_Falt : 47|2@0+ (1,0) [0|3] "SED"  GWM
 SG_ ElCmprOverTe_D_Falt : 45|2@0+ (1,0) [0|3] "SED"  GWM
 SG_ ElCmprBattURng_D_Falt : 37|2@0+ (1,0) [0|3] "SED"  GWM
 SG_ ElCmprBattSysU_D_Falt : 39|2@0+ (1,0) [0|3] "SED"  GWM
 SG_ ElCmprSysU_D_Falt : 41|2@0+ (1,0) [0|3] "SED"  GWM
 SG_ ElCmprUHi_U_Actl : 31|8@0+ (2,0) [0|510] "volt"  GWM
 SG_ ElCmprUHi_D_Stat : 23|2@0+ (1,0) [0|3] "SED"  GWM
 SG_ ElCmprOverTe_D_Stat : 21|2@0+ (1,0) [0|3] "SED"  GWM
 SG_ ElCmpr_N_Actl : 15|8@0+ (50,0) [0|12700] "RPM"  GWM
 SG_ ElCmpr_Pw_Actl : 7|8@0+ (40,0) [0|10160] "watts"  GWM
 SG_ ElCmpr_D_Stat : 19|3@0+ (1,0) [0|7] "SED"  GWM

BO_ 1999 TesterPhysicalResACCM: 8 ACCM
 SG_ TesterPhysicalResACCM : 7|64@0+ (1,0) [0|1.84467E+019] "unitless"  TSTR

BO_ 1991 TesterPhysicalReqACCM: 8 TSTR
 SG_ TesterPhysicalReqACCM : 7|64@0+ (1,0) [0|1.84467E+019] "unitless"  ACCM

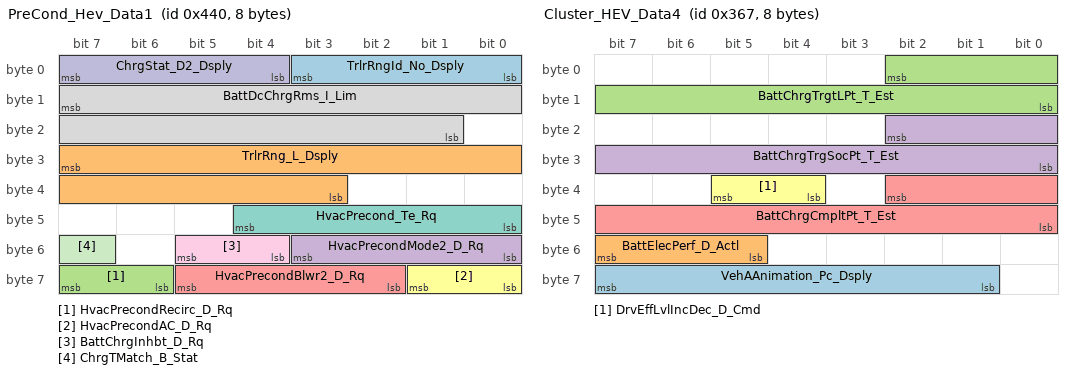
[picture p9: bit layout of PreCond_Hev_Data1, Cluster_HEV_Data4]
BO_ 1088 PreCond_Hev_Data1: 8 GWM
 SG_ TrlrRngId_No_Dsply : 3|4@0+ (1,0) [0|15] "unitless"  GENERIC
 SG_ TrlrRng_L_Dsply : 31|13@0+ (0.1,0) [0|818.9] "kilometer"  GENERIC
 SG_ HvacPrecondRecirc_D_Rq : 63|2@0+ (1,0) [0|3] "SED" Vector__XXX
 SG_ HvacPrecondMode2_D_Rq : 51|4@0+ (1,0) [0|15] "SED" Vector__XXX
 SG_ HvacPrecondBlwr2_D_Rq : 61|4@0+ (1,0) [0|15] "SED" Vector__XXX
 SG_ HvacPrecondAC_D_Rq : 57|2@0+ (1,0) [0|3] "SED" Vector__XXX
 SG_ HvacPrecond_Te_Rq : 44|5@0+ (0.5,14.5) [14.5|30] "deg C" Vector__XXX
 SG_ BattDcChrgRms_I_Lim : 15|15@0+ (0.05,0) [0|1638.25] "ampere" Vector__XXX
 SG_ BattChrgInhbt_D_Rq : 53|2@0+ (1,0) [0|3] "SED" Vector__XXX
 SG_ ChrgStat_D2_Dsply : 7|4@0+ (1,0) [0|15] "SED" Vector__XXX
 SG_ ChrgTMatch_B_Stat : 55|1@0+ (1,0) [0|1] "SED" Vector__XXX

BO_ 871 Cluster_HEV_Data4: 8 GWM
 SG_ VehAAnimation_Pc_Dsply : 63|7@0+ (1,0) [0|127] "percent"  GENERIC
 SG_ BattElecPerf_D_Actl : 55|3@0+ (1,0) [0|7] "SED"  GENERIC
 SG_ BattChrgTrgtLPt_T_Est : 2|11@0+ (1,0) [0|2045] "minute"  GENERIC
 SG_ BattChrgTrgSocPt_T_Est : 18|11@0+ (1,0) [0|2045] "minute"  GENERIC
 SG_ BattChrgCmpltPt_T_Est : 34|11@0+ (1,0) [0|2045] "minute" Vector__XXX
 SG_ DrvEffLvlIncDec_D_Cmd : 37|2@0+ (1,0) [0|3] "SED"  GENERIC

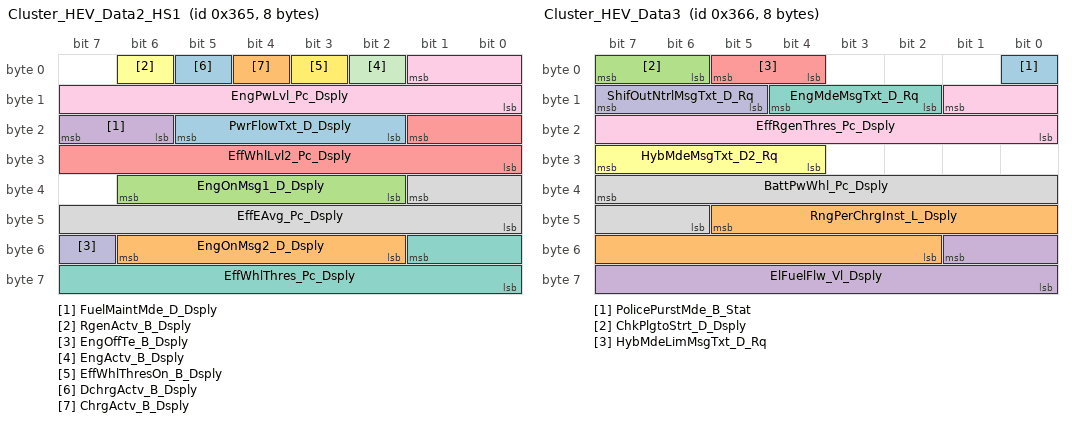
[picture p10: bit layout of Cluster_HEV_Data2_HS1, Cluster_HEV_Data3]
BO_ 869 Cluster_HEV_Data2_HS1: 8 GWM
 SG_ PwrFlowTxt_D_Dsply : 21|4@0+ (1,0) [0|15] "SED"  GENERIC
 SG_ EngOnMsg2_D_Dsply : 54|5@0+ (1,0) [0|31] "SED"  GENERIC
 SG_ EngOnMsg1_D_Dsply : 38|5@0+ (1,0) [0|31] "SED"  GENERIC
 SG_ FuelMaintMde_D_Dsply : 23|2@0+ (1,0) [0|3] "SED"  GENERIC
 SG_ EffWhlLvl2_Pc_Dsply : 17|10@0+ (0.2,-102.2) [-102.2|102.4] "percent"  GENERIC
 SG_ RgenActv_B_Dsply : 6|1@0+ (1,0) [0|1] "SED" Vector__XXX
 SG_ EffWhlThres_Pc_Dsply : 49|10@0+ (0.1,0) [0|102.3] "percent"  GENERIC
 SG_ EffEAvg_Pc_Dsply : 33|10@0+ (0.1,0) [0|102.3] "percent"  GENERIC
 SG_ EngPwLvl_Pc_Dsply : 1|10@0+ (0.1,0) [0|102.3] "percent"  GENERIC
 SG_ EngOffTe_B_Dsply : 55|1@0+ (1,0) [0|1] "SED"  GENERIC
 SG_ EngActv_B_Dsply : 2|1@0+ (1,0) [0|1] "SED"  GENERIC
 SG_ EffWhlThresOn_B_Dsply : 3|1@0+ (1,0) [0|1] "SED"  GENERIC
 SG_ DchrgActv_B_Dsply : 5|1@0+ (1,0) [0|1] "SED"  GENERIC
 SG_ ChrgActv_B_Dsply : 4|1@0+ (1,0) [0|1] "SED"  GENERIC

BO_ 870 Cluster_HEV_Data3: 8 GWM
 SG_ PolicePurstMde_B_Stat : 0|1@0+ (1,0) [0|1] "SED"  GENERIC
 SG_ RngPerChrgInst_L_Dsply : 45|12@0+ (0.1,0) [0|409.3] "km"  GENERIC
 SG_ ChkPlgtoStrt_D_Dsply : 7|2@0+ (1,0) [0|3] "SED"  GENERIC
 SG_ ElFuelFlw_Vl_Dsply : 49|10@0+ (25,0) [0|25575] "micro-litre" Vector__XXX
 SG_ HybMdeLimMsgTxt_D_Rq : 5|2@0+ (1,0) [0|3] "SED"  GENERIC
 SG_ HybMdeMsgTxt_D2_Rq : 31|4@0+ (1,0) [0|15] "SED"  GENERIC
 SG_ EngMdeMsgTxt_D_Rq : 12|3@0+ (1,0) [0|7] "SED"  GENERIC
 SG_ BattPwWhl_Pc_Dsply : 39|10@0+ (0.1,0) [0|102.3] "percent"  GENERIC
 SG_ EffRgenThres_Pc_Dsply : 9|10@0+ (0.1,-102.3) [-102.3|0] "percent"  GENERIC
 SG_ ShifOutNtrlMsgTxt_D_Rq : 15|3@0+ (1,0) [0|7] "SED"  GENERIC

BO_ 130 EPAS_INFO_HS1: 8 GWM
 SG_ TrlrHitchLamp_D_Rqst : 24|1@0+ (1,0) [0|1] "SED"  BCM
 SG_ SteEffort_D_Stat : 52|3@0+ (1,0) [0|7] "SED"  GENERIC
 SG_ SteMdule_D_Stat : 55|3@0+ (1,0) [0|7] "SED"  GENERIC
 SG_ Veh_V_RqMxTrlrAid : 63|8@0+ (0.1,0) [0|25.5] "km/h"  GENERIC
 SG_ DrvSteActv_B_Stat : 10|1@0+ (1,0) [0|1] "SED"  GENERIC
 SG_ DrvSte_Tq_Actl : 47|8@0+ (0.0625,-8) [-8|7.8125] "Nm"  GENERIC
 SG_ VehVTrlrAid_B_Rq : 25|1@0+ (1,0) [0|1] "SED"  GENERIC
 SG_ SteMdule_U_Meas : 39|8@0+ (0.05,6) [6|18.7] "Volts"  GENERIC,BCM
 SG_ SteMdule_I_Est : 21|12@0+ (0.05,-64) [-64|140.7] "Amps"  BCM
 SG_ EPAS_Failure : 9|2@0+ (1,0) [0|3] "SED"  GENERIC
 SG_ SteeringColumnTorque : 7|8@0+ (0.0625,-8) [-8|7.8125] "Nm"  GENERIC
 SG_ SAPPAngleControlStat6 : 15|1@0+ (1,0) [0|1] "SED"  GENERIC
 SG_ SAPPAngleControlStat5 : 14|1@0+ (1,0) [0|1] "SED"  GENERIC
 SG_ SAPPAngleControlStat4 : 13|1@0+ (1,0) [0|1] "SED"  GENERIC
 SG_ SAPPAngleControlStat3 : 12|1@0+ (1,0) [0|1] "SED"  GENERIC
 SG_ SAPPAngleControlStat2 : 11|1@0+ (1,0) [0|1] "SED"  GENERIC
 SG_ SAPPAngleControlStat1 : 23|2@0+ (1,0) [0|3] "SED"  GENERIC

BO_ 1076 Cluster_Info3_HS1: 8 GWM
 SG_ CenterStackRing_D_Actl : 60|2@0+ (1,0) [0|3] "SED" Vector__XXX
 SG_ CenterStackRing_D_Actl_UB : 58|1@0+ (1,0) [0|1] "SED" Vector__XXX
 SG_ EngIdlShutDown_B_RqDrv_UB : 61|1@0+ (1,0) [0|1] "SED"  GENERIC
 SG_ EngIdlShutDown_B_RqDrv : 62|1@0+ (1,0) [0|1] "SED" Vector__XXX
 SG_ OdoTripRx_B_Actl : 63|1@0+ (1,0) [0|1] "SED" Vector__XXX
 SG_ LscmbbEngTqMn_B_Rq_UB : 38|1@0+ (1,0) [0|1] "SED" Vector__XXX
 SG_ LscmbbEngTqMn_B_Rq : 39|1@0+ (1,0) [0|1] "SED" Vector__XXX
 SG_ TirePReset_B_Rq_UB : 18|1@0+ (1,0) [0|1] "SED"  BCM
 SG_ DrTGate_D_Rq : 51|2@0+ (1,0) [0|3] "SED"  BCM
 SG_ DrTGate_D_Rq_UB : 36|1@0+ (1,0) [0|1] "SED"  BCM
 SG_ Veh_V_CompLimMx : 35|12@0+ (0.1,0) [0|409.5] "km/h" Vector__XXX
 SG_ FuelLvlPssvSide_No_Raw : 17|10@0+ (1,0) [0|1023] "Unitless" Vector__XXX
 SG_ FUEL_SENSOR_NUM : 2|1@0+ (1,0) [0|1] "SED" Vector__XXX
 SG_ FuelLvlActvSide_No_Raw : 1|10@0+ (1,0) [0|1023] "Unitless" Vector__XXX
 SG_ DISPLAY_SPEED_SCALING : 23|4@0+ (0.5,100) [100|107.5] "%" Vector__XXX
 SG_ DISPLAY_SPEED_OFFSET : 6|3@0+ (0.5,0) [0|3.5] "kph" Vector__XXX
 SG_ TirePReset_B_Rq : 19|1@0+ (1,0) [0|1] "SED"  BCM

BO_ 1072 Cluster_Info1_HS1: 8 GWM
 SG_ ePRNDL_MODE_UB : 63|1@0+ (1,0) [0|1] "SED"  BCM
 SG_ NtrlTowMdeEnbl_B_RqDrv : 6|1@0+ (1,0) [0|1] "SED" Vector__XXX
 SG_ NtrlTowMdeEnbl_B_RqDrv_UB : 48|1@0+ (1,0) [0|1] "SED"  GENERIC
 SG_ Remote_Start_QuietMode_UB : 50|1@0+ (1,0) [0|1] "SED"  BCM
 SG_ Remote_Start_QuietMode : 51|1@0+ (1,0) [0|1] "SED"  BCM
 SG_ ParkDetect_Stat_UB : 52|1@0+ (1,0) [0|1] "SED"  BCM
 SG_ ParkDetect_Stat : 53|1@0+ (1,0) [0|1] "SED"  BCM
 SG_ TrlrLampCnnct_B_Actl_UB : 42|1@0+ (1,0) [0|1] "SED"  BCM
 SG_ StopLamp_B_RqTrlrBrk_UB : 46|1@0+ (1,0) [0|1] "SED"  BCM
 SG_ StopLamp_B_RqTrlrBrk : 47|1@0+ (1,0) [0|1] "SED"  BCM
 SG_ OdometerMasterValue_UB : 1|1@0+ (1,0) [0|1] "SED"  DCDC_HEV,ACCM,BCM
 SG_ OdometerMasterValue : 15|24@0+ (1,0) [0|16777214] "km"  DCDC_HEV,ACCM,BCM
 SG_ FrostWarn_D_Stat : 5|2@0+ (1,0) [0|3] "SED" Vector__XXX
 SG_ ReducedGuard_D_Rq_UB : 49|1@0+ (1,0) [0|1] "SED"  BCM
 SG_ ReducedGuard_D_Rq : 41|2@0+ (1,0) [0|3] "SED"  BCM
 SG_ ePRNDL_MODE : 0|1@0+ (1,0) [0|1] "SED"  BCM
 SG_ EngOilLife_B_RqReset : 43|1@0+ (1,0) [0|1] "SED" Vector__XXX
 SG_ Outside_Air_Temp_Stat_UB : 2|1@0+ (1,0) [0|1] "SED" Vector__XXX
 SG_ Outside_Air_Temp_Stat : 39|8@0+ (0.5,-40) [-40|86.5] "Degrees C" Vector__XXX
 SG_ KeyTypeChngMykey_D_Rq_UB : 60|1@0+ (1,0) [0|1] "SED"  BCM
 SG_ KeyTypeChngMykey_D_Rq : 62|2@0+ (1,0) [0|3] "SED"  BCM
 SG_ TrlrLampCnnct_B_Actl : 3|1@0+ (1,0) [0|1] "SED"  BCM

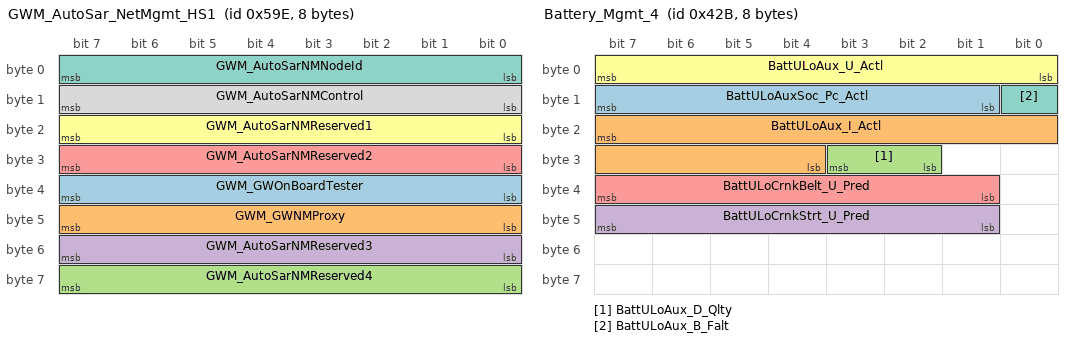
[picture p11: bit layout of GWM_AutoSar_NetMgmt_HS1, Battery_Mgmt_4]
BO_ 1438 GWM_AutoSar_NetMgmt_HS1: 8 GWM
 SG_ GWM_GWOnBoardTester : 39|8@0+ (1,0) [0|255] "unitless"  SOBDMB_AWDC,BCMC_CPDB,BECMB_EPM,BCM
 SG_ GWM_GWNMProxy : 47|8@0+ (1,0) [0|255] "unitless"  SOBDMB_AWDC,BCMC_CPDB,BECMB_EPM,BCM
 SG_ GWM_AutoSarNMReserved4 : 63|8@0+ (1,0) [0|255] "unitless"  SOBDMB_AWDC,BCMC_CPDB,BECMB_EPM,BCM
 SG_ GWM_AutoSarNMReserved3 : 55|8@0+ (1,0) [0|255] "unitless"  SOBDMB_AWDC,BCMC_CPDB,BECMB_EPM,BCM
 SG_ GWM_AutoSarNMReserved2 : 31|8@0+ (1,0) [0|255] "unitless"  SOBDMB_AWDC,BCMC_CPDB,BECMB_EPM,BCM
 SG_ GWM_AutoSarNMReserved1 : 23|8@0+ (1,0) [0|255] "unitless"  SOBDMB_AWDC,BCMC_CPDB,BECMB_EPM,BCM
 SG_ GWM_AutoSarNMNodeId : 7|8@0+ (1,0) [0|255] "unitless"  SOBDMB_AWDC,BCMC_CPDB,BECMB_EPM,BCM
 SG_ GWM_AutoSarNMControl : 15|8@0+ (1,0) [0|255] "unitless"  SOBDMB_AWDC,BCMC_CPDB,BECMB_EPM,BCM

BO_ 1067 Battery_Mgmt_4: 8 BCM
 SG_ BattULoAuxSoc_Pc_Actl : 15|7@0+ (1,0) [0|127] "percent"  GWM
 SG_ BattULoAux_I_Actl : 23|12@0+ (0.0625,-128) [-128|127.875] "ampere"  GWM
 SG_ BattULoAux_D_Qlty : 27|2@0+ (1,0) [0|3] "SED"  GWM
 SG_ BattULoCrnkStrt_U_Pred : 47|7@0+ (0.1,0) [0|12.7] "volt"  GWM
 SG_ BattULoCrnkBelt_U_Pred : 39|7@0+ (0.1,0) [0|12.7] "volt"  GWM
 SG_ BattULoAux_U_Actl : 7|8@0+ (0.0625,0) [0|15.875] "volt"  GWM
 SG_ BattULoAux_B_Falt : 8|1@0+ (1,0) [0|1] "SED"  GWM

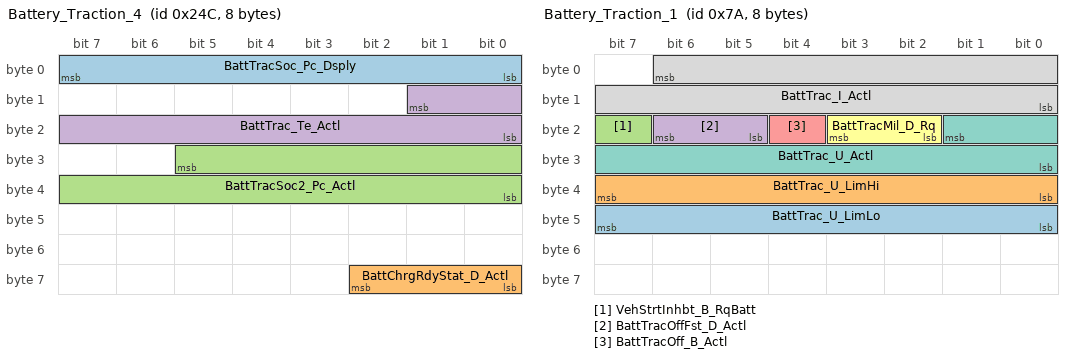
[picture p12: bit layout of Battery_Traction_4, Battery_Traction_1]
BO_ 588 Battery_Traction_4: 8 GWM
 SG_ BattTracSoc_Pc_Dsply : 7|8@0+ (0.5,0) [0|126.5] "Percent" Vector__XXX
 SG_ BattChrgRdyStat_D_Actl : 58|3@0+ (1,0) [0|7] "SED" Vector__XXX
 SG_ BattTracSoc2_Pc_Actl : 29|14@0+ (0.01,0) [0|163.81] "%" Vector__XXX
 SG_ BattTrac_Te_Actl : 9|10@0+ (0.5,-50) [-50|460.5] "degC" Vector__XXX

BO_ 122 Battery_Traction_1: 8 GWM
 SG_ BattTrac_U_LimLo : 47|8@0+ (2,0) [0|510] "volt"  SOBDMB_AWDC
 SG_ BattTrac_U_LimHi : 39|8@0+ (2,0) [0|510] "volt"  SOBDMB_AWDC
 SG_ VehStrtInhbt_B_RqBatt : 23|1@0+ (1,0) [0|1] "SED" Vector__XXX
 SG_ BattTracOffFst_D_Actl : 22|2@0+ (1,0) [0|3] "SED"  SOBDMB_AWDC,ACCM
 SG_ BattTracOff_B_Actl : 20|1@0+ (1,0) [0|1] "SED"  SOBDMB_AWDC
 SG_ BattTracMil_D_Rq : 19|2@0+ (1,0) [0|3] "SED" Vector__XXX
 SG_ BattTrac_U_Actl : 17|10@0+ (0.5,0) [0|510.5] "Volts"  DCDC_HEV
 SG_ BattTrac_I_Actl : 6|15@0+ (0.05,-750) [-750|888.25] "Amps" Vector__XXX

BO_ 1814 TesterPhysicalReqGWM_H1: 8 TSTR
 SG_ TesterPhysicalReqGWM_H1 : 7|64@0+ (1,0) [0|1.84467E+019] "unitless"  GWM

BO_ 1822 TesterPhysicalResGWM_HS1: 8 GWM
 SG_ TesterPhysicalResGWM_H1 : 7|64@0+ (1,0) [0|1.84467E+019] "unitless"  TSTR

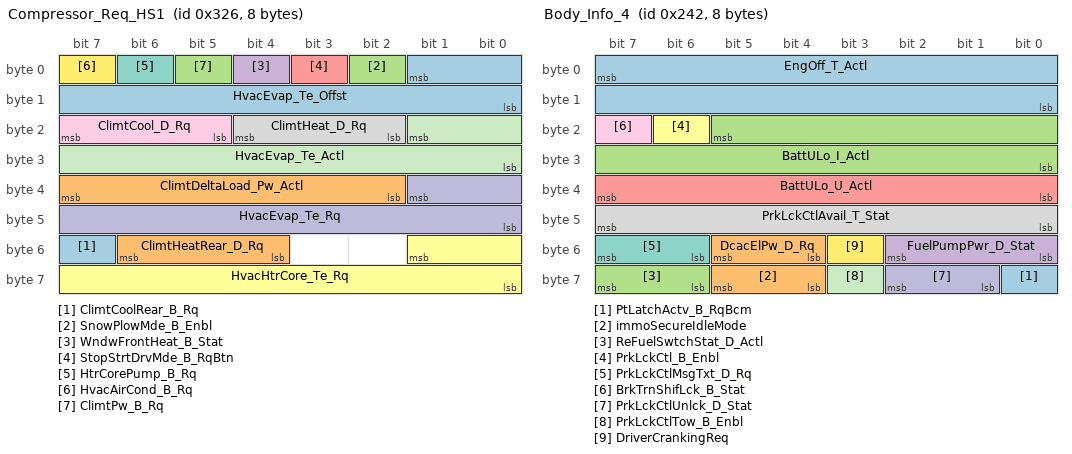
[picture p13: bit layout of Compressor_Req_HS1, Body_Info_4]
BO_ 806 Compressor_Req_HS1: 8 GWM
 SG_ ClimtCoolRear_B_Rq : 55|1@0+ (1,0) [0|1] "SED" Vector__XXX
 SG_ ClimtHeatRear_D_Rq : 54|3@0+ (1,0) [0|7] "SED" Vector__XXX
 SG_ SnowPlowMde_B_Enbl : 2|1@0+ (1,0) [0|1] "SED"  BCM
 SG_ WndwFrontHeat_B_Stat : 4|1@0+ (1,0) [0|1] "SED"  GENERIC
 SG_ StopStrtDrvMde_B_RqBtn : 3|1@0+ (1,0) [0|1] "SED" Vector__XXX
 SG_ HvacHtrCore_Te_Rq : 49|10@0+ (0.25,-50) [-50|205.75] "degC" Vector__XXX
 SG_ HtrCorePump_B_Rq : 6|1@0+ (1,0) [0|1] "SED" Vector__XXX
 SG_ ClimtHeat_D_Rq : 20|3@0+ (1,0) [0|7] "SED" Vector__XXX
 SG_ ClimtCool_D_Rq : 23|3@0+ (1,0) [0|7] "SED" Vector__XXX
 SG_ HvacEvap_Te_Rq : 33|10@0+ (0.125,-50) [-50|77.875] "Degrees C" Vector__XXX
 SG_ HvacEvap_Te_Actl : 17|10@0+ (0.125,-50) [-50|77.75] "Degrees C" Vector__XXX
 SG_ HvacAirCond_B_Rq : 7|1@0+ (1,0) [0|1] "SED" Vector__XXX
 SG_ HvacEvap_Te_Offst : 1|10@0+ (0.125,-50) [-50|77.875] "Degrees C" Vector__XXX
 SG_ ClimtDeltaLoad_Pw_Actl : 39|6@0+ (50,-1600) [-1600|1450] "watts" Vector__XXX
 SG_ ClimtPw_B_Rq : 5|1@0+ (1,0) [0|1] "SED" Vector__XXX

BO_ 578 Body_Info_4: 8 BCM
 SG_ PtLatchActv_B_RqBcm : 56|1@0+ (1,0) [0|1] "SED"  GWM
 SG_ immoSecureIdleMode : 61|2@0+ (1,0) [0|3] "SED"  SOBDMB_AWDC,GWM
 SG_ ReFuelSwtchStat_D_Actl : 63|2@0+ (1,0) [0|3] "SED"  GWM
 SG_ FuelPumpPwr_D_Stat : 50|3@0+ (1,0) [0|7] "SED"  GWM
 SG_ BattULo_U_Actl : 39|8@0+ (0.0625,0) [0|15.875] "volt"  ACCM,DCDC_HEV,GWM
 SG_ PrkLckCtl_B_Enbl : 22|1@0+ (1,0) [0|1] "SED"  GWM
 SG_ PrkLckCtlMsgTxt_D_Rq : 55|2@0+ (1,0) [0|3] "SED"  GWM
 SG_ PrkLckCtlAvail_T_Stat : 47|8@0+ (1,0) [0|255] "second"  GWM
 SG_ BrkTrnShifLck_B_Stat : 23|1@0+ (1,0) [0|1] "SED"  GWM
 SG_ PrkLckCtlUnlck_D_Stat : 58|2@0+ (1,0) [0|3] "SED"  GWM
 SG_ PrkLckCtlTow_B_Enbl : 59|1@0+ (1,0) [0|1] "SED"  GWM
 SG_ DriverCrankingReq : 51|1@0+ (1,0) [0|1] "SED"  GWM
 SG_ EngOff_T_Actl : 7|16@0+ (1,0) [0|65534] "second^0.5"  GWM
 SG_ DcacElPw_D_Rq : 53|2@0+ (1,0) [0|3] "SED"  GWM
 SG_ BattULo_I_Actl : 21|14@0+ (0.0625,-512) [-512|511.875] "ampere"  GWM

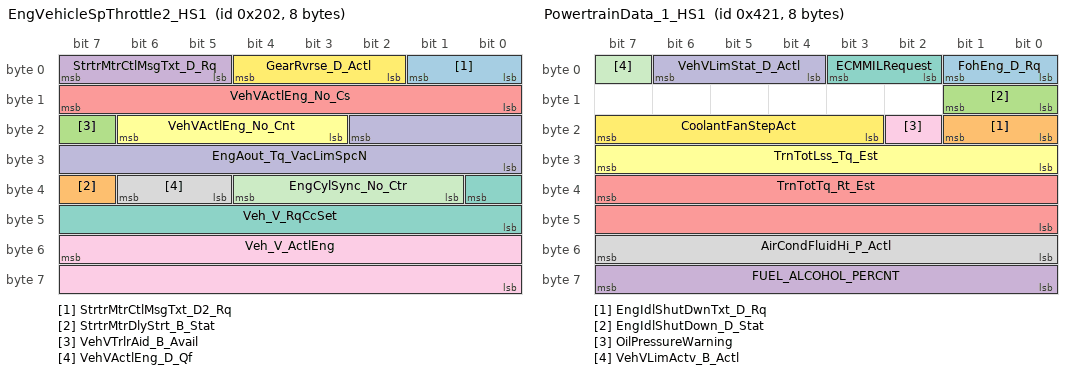
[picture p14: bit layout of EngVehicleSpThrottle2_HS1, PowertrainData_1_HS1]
BO_ 514 EngVehicleSpThrottle2_HS1: 8 GWM
 SG_ StrtrMtrCtlMsgTxt_D2_Rq : 1|2@0+ (1,0) [0|3] "SED"  BCM
 SG_ StrtrMtrDlyStrt_B_Stat : 39|1@0+ (1,0) [0|1] "SED"  BCM
 SG_ VehVTrlrAid_B_Avail : 23|1@0+ (1,0) [0|1] "SED"  GENERIC
 SG_ StrtrMtrCtlMsgTxt_D_Rq : 7|3@0+ (1,0) [0|7] "SED"  GENERIC
 SG_ VehVActlEng_No_Cs : 15|8@0+ (1,0) [0|255] "Unitless"  GENERIC
 SG_ VehVActlEng_No_Cnt : 22|4@0+ (1,0) [0|15] "Unitless"  GENERIC
 SG_ Veh_V_RqCcSet : 32|9@0+ (0.5,0) [0|255.5] "kph"  GENERIC
 SG_ VehVActlEng_D_Qf : 38|2@0+ (1,0) [0|3] "SED"  PACM,BCMC_CPDB,BCM
 SG_ Veh_V_ActlEng : 55|16@0+ (0.01,0) [0|655.35] "kph"  BCMC_CPDB,BECMB_EPM,PACM,BCM
 SG_ EngAout_Tq_VacLimSpcN : 18|11@0+ (1,-500) [-500|1547] "Nm"  GENERIC
 SG_ EngCylSync_No_Ctr : 36|4@0+ (1,0) [0|15] "unitless"  GENERIC
 SG_ GearRvrse_D_Actl : 4|3@0+ (1,0) [0|7] "SED"  PACM,BCM

BO_ 1057 PowertrainData_1_HS1: 8 GWM
 SG_ FohEng_D_Rq : 1|2@0+ (1,0) [0|3] "SED" Vector__XXX
 SG_ EngIdlShutDwnTxt_D_Rq : 17|2@0+ (1,0) [0|3] "SED" Vector__XXX
 SG_ EngIdlShutDown_D_Stat : 9|2@0+ (1,0) [0|3] "SED"  BCM
 SG_ FUEL_ALCOHOL_PERCNT : 63|8@0+ (0.393700787,0) [0|99.999899898] "Percent" Vector__XXX
 SG_ TrnTotTq_Rt_Est : 39|16@0+ (0.001,0) [0|65.533] "Unitless" Vector__XXX
 SG_ TrnTotLss_Tq_Est : 31|8@0+ (0.5,0) [0|126.5] "Nm" Vector__XXX
 SG_ ECMMILRequest : 3|2@0+ (1,0) [0|3] "SED" Vector__XXX
 SG_ AirCondFluidHi_P_Actl : 55|8@0+ (0.125,0) [0|31.625] "bar" Vector__XXX
 SG_ OilPressureWarning : 18|1@0+ (1,0) [0|1] "SED" Vector__XXX
 SG_ VehVLimStat_D_Actl : 6|3@0+ (1,0) [0|7] "SED" Vector__XXX
 SG_ VehVLimActv_B_Actl : 7|1@0+ (1,0) [0|1] "SED" Vector__XXX
 SG_ CoolantFanStepAct : 23|5@0+ (1,0) [0|31] "Steps"  BCM

BO_TX_BU_ 1085 : GWM,DCDC_HEV;
CM_ SG_ 753 TurnLampRrOut_B_Stat "Signal not transmitted on vehicles without a BCMB module.";
CM_ SG_ 753 TurnLampRlOut_B_Stat "Signal not transmitted on vehicles without a BCMB module.";
CM_ SG_ 753 CnvtTopPos_Up_Stat "Signal not transmitted on vehicles without convertible tops.";
CM_ SG_ 753 CnvtTopPos_Dn_Stat "Signal not transmitted on vehicles without convertible tops.";
CM_ SG_ 1046 DrvAntiLckLamp_D_Rq "update value table v8.34, not align w/GSDB, need etracker.  ABS & IPC implemented as updated.";
CM_ SG_ 1046 TCMode "Signal data set to 0x0 for ABS only vehicle option content";
CM_ BO_ 534 "DCR 1833 to update Tx from GWM to EP100ms. Wheel Count signals are used by complex algorithm to determine Tire Pressure by Location & can't change from 20msec. (jweinfur)";
CM_ SG_ 534 WhlRotatRr_No_Cnt "DCR 1833 to update Tx from GWM to EP100ms. Wheel Count signals are used by complex algorithm to determine Tire Pressure by Location & can't change from 20msec. (jweinfur)";
CM_ SG_ 534 WhlRotatRl_No_Cnt "DCR 1833 to update Tx from GWM to EP100ms. Wheel Count signals are used by complex algorithm to determine Tire Pressure by Location & can't change from 20msec. (jweinfur)";
CM_ SG_ 534 WhlRotatFr_No_Cnt "DCR 1833 to update Tx from GWM to EP100ms. Wheel Count signals are used by complex algorithm to determine Tire Pressure by Location & can't change from 20msec. (jweinfur)";
CM_ SG_ 534 WhlRotatFl_No_Cnt "DCR 1833 to update Tx from GWM to EP100ms. Wheel Count signals are used by complex algorithm to determine Tire Pressure by Location & can't change from 20msec. (jweinfur)";
CM_ SG_ 534 BrkObdData_No_Actl "Signal not transmitted on gas, diesel and HEV.  Only supported on PHEV.";
CM_ SG_ 534 BrkObdIndex_No_Actl "Signal not transmitted on gas, diesel and HEV.  Only supported on PHEV.";
CM_ BO_ 531 "IC is NOT to use data in this message for displays, Used data from 415 instead.";
CM_ BO_ 611 "Used on Applications with 4x4 supplied by Motorola.";
CM_ SG_ 611 AwdStat_D_RqDsply "Signal not transmitted on programs that do not have AWD.";
CM_ SG_ 611 AwdSrvcRqd_B_Rq "Signal not transmitted on programs that do not have AWD.";
CM_ SG_ 611 AwdLck_Tq_Rq "Signal not transmitted on programs that do not have AWD.";
CM_ SG_ 90 TrnGsmNtmState_D_Actl "Signal not transmitted on vehicles that do not have shift by wire.";
CM_ SG_ 90 DrQltyDrv_D_StatGsm "Signal not transmitted on vehicles that do not have shift by wire.";
CM_ SG_ 90 TrnBtsiOvrrd_B_Stat "Signal not transmitted on vehicles that do not have shift by wire.";
CM_ SG_ 90 TrnValidGearRq_D_Stat "Signal not transmitted on vehicles that do not have shift by wire.";
CM_ SG_ 90 TrnGearRqCnt_B_Actl "Signal not transmitted on vehicles that do not have shift by wire.";
CM_ SG_ 90 TrnGearButtn_U_Actl "Signal not transmitted on vehicles that do not have shift by wire.";
CM_ SG_ 90 TrnGearButtn_B_ActlR2 "Signal not transmitted on vehicles that do not have shift by wire.";
CM_ SG_ 90 TrnGearButtn_B_ActlR1 "Signal not transmitted on vehicles that do not have shift by wire.";
CM_ SG_ 90 TrnGearButtn_B_ActlR0 "Signal not transmitted on vehicles that do not have shift by wire.";
CM_ SG_ 90 TrnGearButtn_B_ActlP2 "Signal not transmitted on vehicles that do not have shift by wire.";
CM_ SG_ 90 TrnGearButtn_B_ActlP1 "Signal not transmitted on vehicles that do not have shift by wire.";
CM_ SG_ 90 TrnGearButtn_B_ActlP0 "Signal not transmitted on vehicles that do not have shift by wire.";
CM_ SG_ 90 TrnGearButtn_B_ActlN2 "Signal not transmitted on vehicles that do not have shift by wire.";
CM_ SG_ 90 TrnGearButtn_B_ActlN1 "Signal not transmitted on vehicles that do not have shift by wire.";
CM_ SG_ 90 TrnGearButtn_B_ActlN0 "Signal not transmitted on vehicles that do not have shift by wire.";
CM_ SG_ 90 TrnGearButtn_B_ActlM2 "Signal not transmitted on vehicles that do not have shift by wire.";
CM_ SG_ 90 TrnGearButtn_B_ActlM1 "Signal not transmitted on vehicles that do not have shift by wire.";
CM_ SG_ 90 TrnGearButtn_B_ActlM0 "Signal not transmitted on vehicles that do not have shift by wire.";
CM_ SG_ 90 TrnGearButtn_B_ActlD2 "Signal not transmitted on vehicles that do not have shift by wire.";
CM_ SG_ 90 TrnGearButtn_B_ActlD1 "Signal not transmitted on vehicles that do not have shift by wire.";
CM_ SG_ 90 TrnGearButtn_B_ActlD0 "Signal not transmitted on vehicles that do not have shift by wire.";
CM_ SG_ 90 TrnGear_No_Cs "Signal not transmitted on vehicles that do not have shift by wire.";
CM_ SG_ 90 TrnGear_No_Cnt "Signal not transmitted on vehicles that do not have shift by wire.";
CM_ SG_ 90 TrnGear_D_RqDrv "Signal not transmitted on vehicles that do not have shift by wire.";
CM_ SG_ 90 BrkSwtchPos_B_ActlGsm "Signal not transmitted on vehicles that do not have shift by wire.";
CM_ SG_ 92 TrnGearMsgTxt2_D_Rq "Signal not transmitted on vehicles that do not have shift by wire.";
CM_ SG_ 92 TrnSbwSysHlth_D_Actl "Signal not transmitted on vehicles that do not have shift by wire.";
CM_ SG_ 92 TrnGearNtmAllow_B_Stat "Signal not transmitted on vehicles that do not have shift by wire.";
CM_ SG_ 92 TrnDtpCmd_D_Actl "Signal not transmitted on vehicles that do not have shift by wire.";
CM_ SG_ 92 TrnGearCmd_No_Cs "Signal not transmitted on vehicles that do not have shift by wire.";
CM_ SG_ 92 TrnValidGear_D_Cnfm "Signal not transmitted on vehicles that do not have shift by wire.";
CM_ SG_ 92 TrnNtrlTowCmd_D_Actl "Signal not transmitted on vehicles that do not have shift by wire.";
CM_ SG_ 92 TrnGearCmd_Pc_ActlPt "Signal not transmitted on vehicles that do not have shift by wire.";
CM_ SG_ 92 TrnGear_D_RqPt "Signal not transmitted on vehicles that do not have shift by wire.";
CM_ SG_ 92 TrnCmdState_B_Actl "Signal not transmitted on vehicles that do not have shift by wire.";
CM_ SG_ 92 TrnCmdCnt_B_Actl "Signal not transmitted on vehicles that do not have shift by wire.";
CM_ SG_ 92 PrkBrkActv_D_RqTrnGear "Signal not transmitted on vehicles that do not have shift by wire.";
CM_ SG_ 92 TrnGearMsgTxt_D_Rq "Signal not transmitted on vehicles that do not have shift by wire.";
CM_ SG_ 92 TrnGearCmd_No_Cnt "Signal not transmitted on vehicles that do not have shift by wire.";
CM_ SG_ 359 TrnAin_Tq_Actl "Signal not transmitted on HEV variances.";
CM_ SG_ 359 PlgActvArb_B_Actl "Only supported on PHEV programs.  PlgActvArb_B_Actl HPCM will Tx on Powersplit PHEV’s,  On MHT PHEVs the PCM_HEV will Tx and HPCM will Rx. 
";
CM_ SG_ 359 TrnAinTq_D_Qf "Signal not transmitted on HEV variances.";
CM_ SG_ 358 HiElPwInhbt_B_Stat "Signal not transmitted on HEV programs";
CM_ SG_ 358 AutoStopPtDelta_I_Est "Signal not transmitted on vehicles that do not have autostop/stop-start feature.";
CM_ SG_ 1086 ElLoadCtl_D_Rq "Signal not transmitted on HEV variants.";
CM_ BO_ 1085 "HS1 0x43D Tx by HS1 BECM, DCDC_HEV, DCDC_LISB
Or FrameGateway from FD1
Set to FixedPeriodic 50ms at all nodes so the transmit method and rate export from mdc to dbc
Program specific msg lists update attributes as needed.";
CM_ SG_ 1085 DcdcULo_U_Actl "Signal not transmitted on gas and diesel variants.";
CM_ SG_ 1085 DcdcUHi_I_Actl "Signal not transmitted on gas and diesel variants.";
CM_ SG_ 1085 DcdcUHi_U_Actl "Signal not transmitted on gas and diesel variants.";
CM_ BO_ 603 "48V mHEV: ECM_HEVDSL is Tx
MHT HEV: PCM_HEV is Tx
Powersplit HEV: SOBDMC_HPCM is Tx
";
CM_ SG_ 603 WhlDirAvgDrv_D_Actl "48V mHEV: ECM_HEVDSL is Tx,  MHT HEV: PCM_HEV is Tx,  Powersplit HEV: SOBDMC_HPCM is Tx";
CM_ SG_ 603 PrplTqMnRgen_B_Actl "48V mHEV: ECM_HEVDSL is Tx,  MHT HEV: PCM_HEV is Tx,  Powersplit HEV: SOBDMC_HPCM is Tx";
CM_ SG_ 603 BattTracCnnct_D_Rq "48V mHEV: ECM_HEVDSL is Tx,  MHT HEV: PCM_HEV is Tx,  Powersplit HEV: SOBDMC_HPCM is Tx";
CM_ SG_ 1088 HvacPrecondMode2_D_Rq "Signal not transmitted on vehicles that do not have the Fuel operated heater feature.";
CM_ SG_ 1088 HvacPrecondBlwr2_D_Rq "Signal not transmitted on vehicles that do not have the Fuel operated heater feature.";
CM_ SG_ 870 PolicePurstMde_B_Stat "Normal SED EP 1000. Using 100FP can result  in100ms w/c latency.  Latency accepted for feature/function by SME since existing FGW msg.";
CM_ BO_ 130 "DCR 1745  to update Tx from GWM to EP100ms. SteMdule_I_Est & SteMdule_U_Meas are used by BMS system & filtered. The filter uses standard periodic rate & changing to EP would adversely affect the filter.(jweinfur)";
CM_ SG_ 130 VehVTrlrAid_B_Rq "VR session start- req. limit blower speed no more than X volts.  CC restriction on time msg. will be honored.Double Event msg1st event to request limit, 2nd event to release limit, No msg. CC Grammar v7.xls";
CM_ SG_ 130 SteMdule_U_Meas "DCR 1745  to update Tx from GWM to EP100ms. SteMdule_I_Est & SteMdule_U_Meas are used by BMS system & filtered. The filter uses standard periodic rate & changing to EP would adversely affect the filter.(jweinfur)";
CM_ SG_ 130 SteMdule_I_Est "DCR 1745  to update Tx from GWM to EP100ms. SteMdule_I_Est & SteMdule_U_Meas are used by BMS system & filtered. The filter uses standard periodic rate & changing to EP would adversely affect the filter.(jweinfur)";
CM_ SG_ 1076 CenterStackRing_D_Actl "The Center Stack sends the CPLR a signal to turn On or Off the light Ring, This is a customer selectable preference switch";
CM_ SG_ 1072 StopLamp_B_RqTrlrBrk "Signal not transmitted on all variants.";
CM_ SG_ 1072 Outside_Air_Temp_Stat "Filtered value, i.e. same as disply for customer";
CM_ SG_ 514 EngAout_Tq_VacLimSpcN "Signal not transmitted on gas and diesel variances.";
CM_ SG_ 514 EngCylSync_No_Ctr "Signal not transmitted on gas and diesel variances.";
CM_ SG_ 514 GearRvrse_D_Actl "Do not implement GearRvrse_D_Actl  until eTracker 8804151 is approved, 11/24/09";
CM_ SG_ 1057 FohEng_D_Rq "Signal not transmitted on vehicles that do not have the fuel operated heater feature.";
CM_ SG_ 1057 EngIdlShutDown_D_Stat "Signal not transmitted on diesel variants.";
CM_ SG_ 1057 FUEL_ALCOHOL_PERCNT "signal not transmitted on diesel and HEV variants.";
CM_ SG_ 1057 TrnTotTq_Rt_Est "Signal not transmitted on gas and HEV variants.";
CM_ SG_ 1057 TrnTotLss_Tq_Est "Signal not transmitted on gas and HEV variants.";
CM_ SG_ 1057 VehVLimStat_D_Actl "Signal not transmitted on gas and HEV variants.";
CM_ SG_ 1057 VehVLimActv_B_Actl "Signal not transmitted on gas and HEV variants.";
BA_DEF_ BO_  "FrameRouting" STRING ;
BA_DEF_ BO_  "FrameGatewayNetwork" STRING ;
BA_DEF_ BO_  "NetworkInitialization" ENUM  "No","Yes";
BA_DEF_ BO_  "FrameGatewayId" HEX 0 1407;
BA_DEF_ BO_  "EventRateOfChange" INT 10 10000;
BA_DEF_ BO_  "GenMsgStartDelayTime" INT 0 10000;
BA_DEF_ BO_  "GenMsgNrOfRepetition" INT 0 100;
BA_DEF_ BO_  "GenMsgDelayTime" INT 0 1000;
BA_DEF_ BO_  "GenMsgCycleTime" INT 0 100000;
BA_DEF_ BO_  "GenMsgSendType" ENUM  "FixedPeriodic","Event","EnabledPeriodic","NotUsed","NotUsed","EventPeriodic","NotUsed","NotUsed","NoMsgSendType";
BA_DEF_ SG_  "U_CD764_MY2022_Tx" ENUM  "No","Yes";
BA_DEF_ SG_  "U_U55X_MY2022_Tx" ENUM  "No","Yes";
BA_DEF_ SG_  "U_CD542_MY2021_Tx" ENUM  "No","Yes";
BA_DEF_ SG_  "ECGUsedTxSignal" ENUM  "No","Yes";
BA_DEF_ SG_  "U_T6_MCA_MY2020_Tx" ENUM  "No","Yes";
BA_DEF_ SG_  "U_P702_MY2021_Tx" ENUM  "No","Yes";
BA_DEF_ SG_  "U_CX727_MY2021_Tx" ENUM  "No","Yes";
BA_DEF_ SG_  "U_CD764_MY2022_Rx" ENUM  "No","Yes";
BA_DEF_ SG_  "U_U55X_MY2022_Rx" ENUM  "No","Yes";
BA_DEF_ SG_  "U_CD542_MY2021_Rx" ENUM  "No","Yes";
BA_DEF_ SG_  "ECGUsedRxSignal" ENUM  "No","Yes";
BA_DEF_ SG_  "U_T6_MCA_MY2020_Rx" ENUM  "No","Yes";
BA_DEF_ SG_  "U_P702_MY2021_Rx" ENUM  "No","Yes";
BA_DEF_ SG_  "U_CX727_MY2021_Rx" ENUM  "No","Yes";
BA_DEF_ SG_  "GenSigStartValue" HEX 0 268435455;
BA_DEF_ SG_  "MetaData" ENUM  "No","Yes";
BA_DEF_ SG_  "ContentDependant" ENUM  "No","Yes";
BA_DEF_ SG_  "GenSigStartValueInteger" INT 0 1000000000;
BA_DEF_ SG_  "UsedOnPgmDBC" ENUM  "No","Yes";
BA_DEF_ SG_  "WakeupSignal" ENUM  "No","Yes";
BA_DEF_ SG_  "GenSigInactiveValue" INT 0 100000;
BA_DEF_ SG_  "GenSigSendType" ENUM  "Cyclic","OnWrite","vector_leerstring","OnChange","vector_leerstring","IfActive","vector_leerstring","NoSigSendType";
BA_DEF_ BO_  "OvtpPushApplication" ENUM  "FALSE","TRUE";
BA_DEF_ BO_  "SCP_FreshnessValueLength" INT 0 512;
BA_DEF_ BO_  "SCP_FreshnessValueTxLength" INT 0 512;
BA_DEF_ BO_  "SCP_AuthInfoTxLength" INT 0 512;
BA_DEF_ BO_  "GenMsgRoutingTimeoutTime" INT 0 5000;
BA_DEF_ BO_  "MessageGateway" ENUM  "No","Yes";
BA_DEF_ BO_  "NmAsrMessage" ENUM  "No","Yes";
BA_DEF_ BO_  "TpApplType" STRING ;
BA_DEF_ BO_  "DiagState" ENUM  "No","Yes";
BA_DEF_ BO_  "TpTxIndex" INT 0 536870911;
BA_DEF_ BO_  "DiagRequest" ENUM  "No","Yes";
BA_DEF_ BO_  "DiagResponse" ENUM  "No","Yes";
BA_DEF_ BO_  "GenMsgILSupport" ENUM  "No","Yes";
BA_DEF_DEF_  "FrameRouting" "";
BA_DEF_DEF_  "FrameGatewayNetwork" "NONE";
BA_DEF_DEF_  "NetworkInitialization" "Yes";
BA_DEF_DEF_  "FrameGatewayId" 0;
BA_DEF_DEF_  "EventRateOfChange" 10000;
BA_DEF_DEF_  "GenMsgStartDelayTime" 0;
BA_DEF_DEF_  "GenMsgNrOfRepetition" 1;
BA_DEF_DEF_  "GenMsgDelayTime" 20;
BA_DEF_DEF_  "GenMsgCycleTime" 0;
BA_DEF_DEF_  "GenMsgSendType" "NoMsgSendType";
BA_DEF_DEF_  "U_CD764_MY2022_Tx" "No";
BA_DEF_DEF_  "U_U55X_MY2022_Tx" "No";
BA_DEF_DEF_  "U_CD542_MY2021_Tx" "No";
BA_DEF_DEF_  "ECGUsedTxSignal" "No";
BA_DEF_DEF_  "U_T6_MCA_MY2020_Tx" "No";
BA_DEF_DEF_  "U_P702_MY2021_Tx" "No";
BA_DEF_DEF_  "U_CX727_MY2021_Tx" "No";
BA_DEF_DEF_  "U_CD764_MY2022_Rx" "No";
BA_DEF_DEF_  "U_U55X_MY2022_Rx" "No";
BA_DEF_DEF_  "U_CD542_MY2021_Rx" "No";
BA_DEF_DEF_  "ECGUsedRxSignal" "No";
BA_DEF_DEF_  "U_T6_MCA_MY2020_Rx" "No";
BA_DEF_DEF_  "U_P702_MY2021_Rx" "No";
BA_DEF_DEF_  "U_CX727_MY2021_Rx" "No";
BA_DEF_DEF_  "GenSigStartValue" 0;
BA_DEF_DEF_  "MetaData" "No";
BA_DEF_DEF_  "ContentDependant" "No";
BA_DEF_DEF_  "GenSigStartValueInteger" 0;
BA_DEF_DEF_  "UsedOnPgmDBC" "Yes";
BA_DEF_DEF_  "WakeupSignal" "No";
BA_DEF_DEF_  "GenSigInactiveValue" 0;
BA_DEF_DEF_  "GenSigSendType" "NoSigSendType";
BA_DEF_DEF_  "OvtpPushApplication" "FALSE";
BA_DEF_DEF_  "SCP_FreshnessValueLength" 64;
BA_DEF_DEF_  "SCP_FreshnessValueTxLength" 11;
BA_DEF_DEF_  "SCP_AuthInfoTxLength" 53;
BA_DEF_DEF_  "GenMsgRoutingTimeoutTime" 0;
BA_DEF_DEF_  "MessageGateway" "No";
BA_DEF_DEF_  "NmAsrMessage" "No";
BA_DEF_DEF_  "TpApplType" "";
BA_DEF_DEF_  "DiagState" "No";
BA_DEF_DEF_  "TpTxIndex" 0;
BA_DEF_DEF_  "DiagRequest" "No";
BA_DEF_DEF_  "DiagResponse" "No";
BA_DEF_DEF_  "GenMsgILSupport" "Yes";
BA_ "GenMsgSendType" BO_ 753 5;
BA_ "GenMsgCycleTime" BO_ 753 1000;
BA_ "FrameGatewayId" BO_ 818 818;
BA_ "FrameGatewayNetwork" BO_ 818 "MS1_CAN";
BA_ "FrameRouting" BO_ 818 "MS1_CAN,0x332;";
BA_ "GenMsgSendType" BO_ 817 5;
BA_ "GenMsgCycleTime" BO_ 817 1000;
BA_ "GenMsgStartDelayTime" BO_ 817 250;
BA_ "FrameGatewayId" BO_ 1002 1002;
BA_ "FrameGatewayNetwork" BO_ 1002 "HS3_CAN";
BA_ "FrameRouting" BO_ 1002 "HS3_CAN,0x3EA;";
BA_ "FrameGatewayId" BO_ 1046 1046;
BA_ "FrameGatewayNetwork" BO_ 1046 "FD1_CAN";
BA_ "FrameRouting" BO_ 1046 "FD1_CAN,0x416;";
BA_ "GenMsgDelayTime" BO_ 125 10;
BA_ "FrameGatewayId" BO_ 125 125;
BA_ "FrameGatewayNetwork" BO_ 125 "FD1_CAN";
BA_ "FrameRouting" BO_ 125 "FD1_CAN,0x7D;";
BA_ "GenMsgDelayTime" BO_ 119 10;
BA_ "FrameGatewayId" BO_ 119 119;
BA_ "FrameGatewayNetwork" BO_ 119 "FD1_CAN";
BA_ "FrameRouting" BO_ 119 "FD1_CAN,0x77;";
BA_ "GenMsgDelayTime" BO_ 1045 10;
BA_ "FrameGatewayId" BO_ 1045 1045;
BA_ "FrameGatewayNetwork" BO_ 1045 "FD1_CAN";
BA_ "FrameRouting" BO_ 1045 "FD1_CAN,0x415;";
BA_ "GenMsgDelayTime" BO_ 534 10;
BA_ "FrameGatewayId" BO_ 534 534;
BA_ "FrameGatewayNetwork" BO_ 534 "FD1_CAN";
BA_ "FrameRouting" BO_ 534 "FD1_CAN,0x216";
BA_ "GenMsgDelayTime" BO_ 531 10;
BA_ "FrameGatewayId" BO_ 531 531;
BA_ "FrameGatewayNetwork" BO_ 531 "FD1_CAN";
BA_ "FrameRouting" BO_ 531 "FD1_CAN,0x213";
BA_ "GenMsgDelayTime" BO_ 535 0;
BA_ "FrameGatewayId" BO_ 535 535;
BA_ "FrameGatewayNetwork" BO_ 535 "FD1_CAN";
BA_ "FrameRouting" BO_ 535 "FD1_CAN,0x217";
BA_ "FrameGatewayId" BO_ 611 611;
BA_ "FrameGatewayNetwork" BO_ 611 "FD1_CAN";
BA_ "FrameRouting" BO_ 611 "FD1_CAN,0x263;";
BA_ "GenMsgILSupport" BO_ 1409 0;
BA_ "NmAsrMessage" BO_ 1409 1;
BA_ "GenMsgSendType" BO_ 1409 0;
BA_ "GenMsgCycleTime" BO_ 1409 1000;
BA_ "NetworkInitialization" BO_ 1409 0;
BA_ "FrameGatewayId" BO_ 90 90;
BA_ "FrameGatewayNetwork" BO_ 90 "HS2_CAN";
BA_ "FrameRouting" BO_ 90 "HS2_CAN,0x5A;";
BA_ "FrameGatewayId" BO_ 1109 1109;
BA_ "FrameGatewayNetwork" BO_ 1109 "HS3_CAN";
BA_ "FrameRouting" BO_ 1109 "HS3_CAN,0x455;";
BA_ "FrameGatewayId" BO_ 92 92;
BA_ "FrameGatewayNetwork" BO_ 92 "FD1_CAN";
BA_ "FrameRouting" BO_ 92 "FD1_CAN,0x5C;";
BA_ "FrameGatewayId" BO_ 359 359;
BA_ "FrameGatewayNetwork" BO_ 359 "FD1_CAN";
BA_ "FrameRouting" BO_ 359 "FD1_CAN,0x167;";
BA_ "FrameGatewayId" BO_ 358 358;
BA_ "FrameGatewayNetwork" BO_ 358 "FD1_CAN";
BA_ "FrameRouting" BO_ 358 "FD1_CAN,0x166;";
BA_ "GenMsgSendType" BO_ 1084 0;
BA_ "GenMsgCycleTime" BO_ 1084 1000;
BA_ "FrameGatewayId" BO_ 1086 1086;
BA_ "FrameGatewayNetwork" BO_ 1086 "FD1_CAN";
BA_ "FrameRouting" BO_ 1086 "FD1_CAN,0x43E;";
BA_ "FrameRouting" BO_ 1085 "FD1_CAN,0x43D";
BA_ "FrameGatewayNetwork" BO_ 1085 "FD1_CAN";
BA_ "FrameGatewayId" BO_ 1085 1085;
BA_ "GenMsgSendType" BO_ 1085 0;
BA_ "GenMsgCycleTime" BO_ 1085 50;
BA_ "GenMsgSendType" BO_ 891 0;
BA_ "GenMsgCycleTime" BO_ 891 100;
BA_ "FrameGatewayId" BO_ 603 603;
BA_ "FrameGatewayNetwork" BO_ 603 "FD1_CAN";
BA_ "FrameRouting" BO_ 603 "FD1_CAN,0x25B;";
BA_ "FrameGatewayId" BO_ 602 602;
BA_ "FrameGatewayNetwork" BO_ 602 "FD1_CAN";
BA_ "FrameRouting" BO_ 602 "FD1_CAN,0x25A;";
BA_ "FrameGatewayId" BO_ 587 587;
BA_ "FrameGatewayNetwork" BO_ 587 "HS5_CAN";
BA_ "FrameRouting" BO_ 587 "HS5_CAN,0x24B";
BA_ "FrameGatewayId" BO_ 1040 1040;
BA_ "FrameGatewayNetwork" BO_ 1040 "FD1_CAN";
BA_ "FrameRouting" BO_ 1040 "FD1_CAN,0x410;";
BA_ "GenMsgSendType" BO_ 1041 0;
BA_ "GenMsgCycleTime" BO_ 1041 100;
BA_ "GenMsgILSupport" BO_ 1999 0;
BA_ "DiagResponse" BO_ 1999 1;
BA_ "GenMsgSendType" BO_ 1999 1;
BA_ "GenMsgDelayTime" BO_ 1999 0;
BA_ "NetworkInitialization" BO_ 1999 0;
BA_ "GenMsgILSupport" BO_ 1991 0;
BA_ "DiagRequest" BO_ 1991 1;
BA_ "GenMsgSendType" BO_ 1991 1;
BA_ "GenMsgDelayTime" BO_ 1991 0;
BA_ "NetworkInitialization" BO_ 1991 0;
BA_ "FrameGatewayId" BO_ 1088 1088;
BA_ "FrameGatewayNetwork" BO_ 1088 "FD1_CAN";
BA_ "FrameRouting" BO_ 1088 "FD1_CAN,0x440;";
BA_ "FrameGatewayId" BO_ 871 871;
BA_ "FrameGatewayNetwork" BO_ 871 "FD1_CAN";
BA_ "FrameRouting" BO_ 871 "FD1_CAN,0x367;";
BA_ "FrameGatewayId" BO_ 869 869;
BA_ "FrameGatewayNetwork" BO_ 869 "FD1_CAN";
BA_ "FrameRouting" BO_ 869 "FD1_CAN,0x365;";
BA_ "FrameGatewayId" BO_ 870 870;
BA_ "FrameGatewayNetwork" BO_ 870 "FD1_CAN";
BA_ "FrameRouting" BO_ 870 "FD1_CAN,0x366;";
BA_ "GenMsgDelayTime" BO_ 130 10;
BA_ "FrameGatewayId" BO_ 130 130;
BA_ "FrameGatewayNetwork" BO_ 130 "FD1_CAN";
BA_ "FrameRouting" BO_ 130 "FD1_CAN,0x82;";
BA_ "GenMsgSendType" BO_ 1076 5;
BA_ "GenMsgCycleTime" BO_ 1076 100;
BA_ "GenMsgSendType" BO_ 1072 5;
BA_ "GenMsgCycleTime" BO_ 1072 100;
BA_ "GenMsgILSupport" BO_ 1438 0;
BA_ "NmAsrMessage" BO_ 1438 1;
BA_ "GenMsgSendType" BO_ 1438 0;
BA_ "GenMsgCycleTime" BO_ 1438 1000;
BA_ "NetworkInitialization" BO_ 1438 0;
BA_ "GenMsgSendType" BO_ 1067 0;
BA_ "GenMsgCycleTime" BO_ 1067 100;
BA_ "FrameGatewayId" BO_ 588 588;
BA_ "FrameRouting" BO_ 588 "HS5_CAN,0x24C";
BA_ "FrameGatewayNetwork" BO_ 588 "HS5_CAN";
BA_ "FrameGatewayId" BO_ 122 122;
BA_ "FrameGatewayNetwork" BO_ 122 "HS5_CAN";
BA_ "FrameRouting" BO_ 122 "HS5_CAN,0x7A";
BA_ "GenMsgILSupport" BO_ 1814 0;
BA_ "DiagRequest" BO_ 1814 1;
BA_ "GenMsgSendType" BO_ 1814 1;
BA_ "GenMsgDelayTime" BO_ 1814 0;
BA_ "NetworkInitialization" BO_ 1814 0;
BA_ "GenMsgILSupport" BO_ 1822 0;
BA_ "DiagResponse" BO_ 1822 1;
BA_ "GenMsgSendType" BO_ 1822 1;
BA_ "GenMsgDelayTime" BO_ 1822 0;
BA_ "NetworkInitialization" BO_ 1822 0;
BA_ "FrameGatewayId" BO_ 806 806;
BA_ "FrameGatewayNetwork" BO_ 806 "MS1_CAN";
BA_ "FrameRouting" BO_ 806 "MS1_CAN,0x326;";
BA_ "GenMsgSendType" BO_ 578 0;
BA_ "GenMsgCycleTime" BO_ 578 40;
BA_ "FrameGatewayId" BO_ 514 514;
BA_ "FrameGatewayNetwork" BO_ 514 "FD1_CAN";
BA_ "FrameRouting" BO_ 514 "FD1_CAN,0x202;";
BA_ "FrameGatewayId" BO_ 1057 1057;
BA_ "FrameGatewayNetwork" BO_ 1057 "FD1_CAN";
BA_ "FrameRouting" BO_ 1057 "FD1_CAN,0x421;";
BA_ "U_CX727_MY2021_Rx" SG_ 753 TurnLampRrOut_B_Stat_UB 1;
BA_ "U_P702_MY2021_Rx" SG_ 753 TurnLampRrOut_B_Stat_UB 1;
BA_ "U_T6_MCA_MY2020_Rx" SG_ 753 TurnLampRrOut_B_Stat_UB 1;
BA_ "U_CD542_MY2021_Rx" SG_ 753 TurnLampRrOut_B_Stat_UB 1;
BA_ "U_U55X_MY2022_Rx" SG_ 753 TurnLampRrOut_B_Stat_UB 1;
BA_ "U_CD764_MY2022_Rx" SG_ 753 TurnLampRrOut_B_Stat_UB 1;
BA_ "WakeupSignal" SG_ 753 TurnLampRrOut_B_Stat 1;
BA_ "ContentDependant" SG_ 753 TurnLampRrOut_B_Stat 1;
BA_ "GenSigSendType" SG_ 753 TurnLampRrOut_B_Stat 3;
BA_ "U_CX727_MY2021_Rx" SG_ 753 TurnLampRrOut_B_Stat 1;
BA_ "U_P702_MY2021_Rx" SG_ 753 TurnLampRrOut_B_Stat 1;
BA_ "U_T6_MCA_MY2020_Rx" SG_ 753 TurnLampRrOut_B_Stat 1;
BA_ "U_CD542_MY2021_Rx" SG_ 753 TurnLampRrOut_B_Stat 1;
BA_ "U_U55X_MY2022_Rx" SG_ 753 TurnLampRrOut_B_Stat 1;
BA_ "U_CD764_MY2022_Rx" SG_ 753 TurnLampRrOut_B_Stat 1;
BA_ "U_CX727_MY2021_Rx" SG_ 753 TurnLampRlOut_B_Stat_UB 1;
BA_ "U_P702_MY2021_Rx" SG_ 753 TurnLampRlOut_B_Stat_UB 1;
BA_ "U_T6_MCA_MY2020_Rx" SG_ 753 TurnLampRlOut_B_Stat_UB 1;
BA_ "U_CD542_MY2021_Rx" SG_ 753 TurnLampRlOut_B_Stat_UB 1;
BA_ "U_U55X_MY2022_Rx" SG_ 753 TurnLampRlOut_B_Stat_UB 1;
BA_ "U_CD764_MY2022_Rx" SG_ 753 TurnLampRlOut_B_Stat_UB 1;
BA_ "WakeupSignal" SG_ 753 TurnLampRlOut_B_Stat 1;
BA_ "ContentDependant" SG_ 753 TurnLampRlOut_B_Stat 1;
BA_ "GenSigSendType" SG_ 753 TurnLampRlOut_B_Stat 3;
BA_ "U_CX727_MY2021_Rx" SG_ 753 TurnLampRlOut_B_Stat 1;
BA_ "U_P702_MY2021_Rx" SG_ 753 TurnLampRlOut_B_Stat 1;
BA_ "U_T6_MCA_MY2020_Rx" SG_ 753 TurnLampRlOut_B_Stat 1;
BA_ "U_CD542_MY2021_Rx" SG_ 753 TurnLampRlOut_B_Stat 1;
BA_ "U_U55X_MY2022_Rx" SG_ 753 TurnLampRlOut_B_Stat 1;
BA_ "U_CD764_MY2022_Rx" SG_ 753 TurnLampRlOut_B_Stat 1;
BA_ "U_CX727_MY2021_Rx" SG_ 753 CnvtTopPos_Up_Stat_UB 1;
BA_ "U_P702_MY2021_Rx" SG_ 753 CnvtTopPos_Up_Stat_UB 1;
BA_ "U_T6_MCA_MY2020_Rx" SG_ 753 CnvtTopPos_Up_Stat_UB 1;
BA_ "U_CD542_MY2021_Rx" SG_ 753 CnvtTopPos_Up_Stat_UB 1;
BA_ "U_U55X_MY2022_Rx" SG_ 753 CnvtTopPos_Up_Stat_UB 1;
BA_ "U_CD764_MY2022_Rx" SG_ 753 CnvtTopPos_Up_Stat_UB 1;
BA_ "WakeupSignal" SG_ 753 GlvBoxRleas_No_Actl 1;
BA_ "GenSigSendType" SG_ 753 GlvBoxRleas_No_Actl 3;
BA_ "U_CX727_MY2021_Rx" SG_ 753 GlvBoxRleas_No_Actl 1;
BA_ "U_P702_MY2021_Rx" SG_ 753 GlvBoxRleas_No_Actl 1;
BA_ "U_T6_MCA_MY2020_Rx" SG_ 753 GlvBoxRleas_No_Actl 1;
BA_ "U_CD542_MY2021_Rx" SG_ 753 GlvBoxRleas_No_Actl 1;
BA_ "U_U55X_MY2022_Rx" SG_ 753 GlvBoxRleas_No_Actl 1;
BA_ "U_CD764_MY2022_Rx" SG_ 753 GlvBoxRleas_No_Actl 1;
BA_ "U_CX727_MY2021_Rx" SG_ 753 GlvBoxRleas_No_Actl_UB 1;
BA_ "U_P702_MY2021_Rx" SG_ 753 GlvBoxRleas_No_Actl_UB 1;
BA_ "U_T6_MCA_MY2020_Rx" SG_ 753 GlvBoxRleas_No_Actl_UB 1;
BA_ "U_CD542_MY2021_Rx" SG_ 753 GlvBoxRleas_No_Actl_UB 1;
BA_ "U_U55X_MY2022_Rx" SG_ 753 GlvBoxRleas_No_Actl_UB 1;
BA_ "U_CD764_MY2022_Rx" SG_ 753 GlvBoxRleas_No_Actl_UB 1;
BA_ "U_CX727_MY2021_Rx" SG_ 753 ValetMode_D_Stat_UB 1;
BA_ "U_P702_MY2021_Rx" SG_ 753 ValetMode_D_Stat_UB 1;
BA_ "U_T6_MCA_MY2020_Rx" SG_ 753 ValetMode_D_Stat_UB 1;
BA_ "U_CD542_MY2021_Rx" SG_ 753 ValetMode_D_Stat_UB 1;
BA_ "U_U55X_MY2022_Rx" SG_ 753 ValetMode_D_Stat_UB 1;
BA_ "U_CD764_MY2022_Rx" SG_ 753 ValetMode_D_Stat_UB 1;
BA_ "U_CX727_MY2021_Rx" SG_ 753 RollCodeValet_UB 1;
BA_ "U_P702_MY2021_Rx" SG_ 753 RollCodeValet_UB 1;
BA_ "U_T6_MCA_MY2020_Rx" SG_ 753 RollCodeValet_UB 1;
BA_ "U_CD542_MY2021_Rx" SG_ 753 RollCodeValet_UB 1;
BA_ "U_U55X_MY2022_Rx" SG_ 753 RollCodeValet_UB 1;
BA_ "U_CD764_MY2022_Rx" SG_ 753 RollCodeValet_UB 1;
BA_ "GenSigSendType" SG_ 753 EdmSailMde_B_RqDrv 3;
BA_ "GenSigSendType" SG_ 753 LpdbPtc3_B_Rq 3;
BA_ "U_CX727_MY2021_Rx" SG_ 753 LpdbPtc3_B_Rq 1;
BA_ "U_CD542_MY2021_Rx" SG_ 753 LpdbPtc3_B_Rq 1;
BA_ "U_CD764_MY2022_Rx" SG_ 753 LpdbPtc3_B_Rq 1;
BA_ "U_P702_MY2021_Rx" SG_ 753 LpdbPtc3_B_Rq 1;
BA_ "U_T6_MCA_MY2020_Rx" SG_ 753 LpdbPtc3_B_Rq 1;
BA_ "U_U55X_MY2022_Rx" SG_ 753 LpdbPtc3_B_Rq 1;
BA_ "GenSigSendType" SG_ 753 LpdbPtc2_B_Rq 3;
BA_ "U_CX727_MY2021_Rx" SG_ 753 LpdbPtc2_B_Rq 1;
BA_ "U_CD542_MY2021_Rx" SG_ 753 LpdbPtc2_B_Rq 1;
BA_ "U_CD764_MY2022_Rx" SG_ 753 LpdbPtc2_B_Rq 1;
BA_ "U_P702_MY2021_Rx" SG_ 753 LpdbPtc2_B_Rq 1;
BA_ "U_T6_MCA_MY2020_Rx" SG_ 753 LpdbPtc2_B_Rq 1;
BA_ "U_U55X_MY2022_Rx" SG_ 753 LpdbPtc2_B_Rq 1;
BA_ "GenSigSendType" SG_ 753 LpdbPtc1_B_Rq 3;
BA_ "U_CX727_MY2021_Rx" SG_ 753 LpdbPtc1_B_Rq 1;
BA_ "U_CD542_MY2021_Rx" SG_ 753 LpdbPtc1_B_Rq 1;
BA_ "U_CD764_MY2022_Rx" SG_ 753 LpdbPtc1_B_Rq 1;
BA_ "U_P702_MY2021_Rx" SG_ 753 LpdbPtc1_B_Rq 1;
BA_ "U_T6_MCA_MY2020_Rx" SG_ 753 LpdbPtc1_B_Rq 1;
BA_ "U_U55X_MY2022_Rx" SG_ 753 LpdbPtc1_B_Rq 1;
BA_ "U_CX727_MY2021_Rx" SG_ 753 Em_D_Stat_UB 1;
BA_ "U_P702_MY2021_Rx" SG_ 753 Em_D_Stat_UB 1;
BA_ "U_T6_MCA_MY2020_Rx" SG_ 753 Em_D_Stat_UB 1;
BA_ "U_CD542_MY2021_Rx" SG_ 753 Em_D_Stat_UB 1;
BA_ "U_U55X_MY2022_Rx" SG_ 753 Em_D_Stat_UB 1;
BA_ "U_CD764_MY2022_Rx" SG_ 753 Em_D_Stat_UB 1;
BA_ "GenSigSendType" SG_ 753 LpdbHeatWiprPrk_B_Rq 3;
BA_ "U_CX727_MY2021_Rx" SG_ 753 LpdbHeatWiprPrk_B_Rq 1;
BA_ "U_CD542_MY2021_Rx" SG_ 753 LpdbHeatWiprPrk_B_Rq 1;
BA_ "U_CD764_MY2022_Rx" SG_ 753 LpdbHeatWiprPrk_B_Rq 1;
BA_ "U_P702_MY2021_Rx" SG_ 753 LpdbHeatWiprPrk_B_Rq 1;
BA_ "U_U55X_MY2022_Rx" SG_ 753 LpdbHeatWiprPrk_B_Rq 1;
BA_ "U_CX727_MY2021_Rx" SG_ 753 LpdbDfrstRearOn_B_Rq_UB 1;
BA_ "U_CD542_MY2021_Rx" SG_ 753 LpdbDfrstRearOn_B_Rq_UB 1;
BA_ "U_CD764_MY2022_Rx" SG_ 753 LpdbDfrstRearOn_B_Rq_UB 1;
BA_ "U_P702_MY2021_Rx" SG_ 753 LpdbDfrstRearOn_B_Rq_UB 1;
BA_ "U_T6_MCA_MY2020_Rx" SG_ 753 LpdbDfrstRearOn_B_Rq_UB 1;
BA_ "U_U55X_MY2022_Rx" SG_ 753 LpdbDfrstRearOn_B_Rq_UB 1;
BA_ "GenSigSendType" SG_ 753 LpdbDfrstRearOn_B_Rq 3;
BA_ "U_CX727_MY2021_Rx" SG_ 753 LpdbDfrstRearOn_B_Rq 1;
BA_ "U_CD542_MY2021_Rx" SG_ 753 LpdbDfrstRearOn_B_Rq 1;
BA_ "U_CD764_MY2022_Rx" SG_ 753 LpdbDfrstRearOn_B_Rq 1;
BA_ "U_P702_MY2021_Rx" SG_ 753 LpdbDfrstRearOn_B_Rq 1;
BA_ "U_T6_MCA_MY2020_Rx" SG_ 753 LpdbDfrstRearOn_B_Rq 1;
BA_ "U_U55X_MY2022_Rx" SG_ 753 LpdbDfrstRearOn_B_Rq 1;
BA_ "GenSigSendType" SG_ 753 LpdbDfrstFrOn_B_Rq 3;
BA_ "U_CX727_MY2021_Rx" SG_ 753 LpdbDfrstFrOn_B_Rq 1;
BA_ "U_CD542_MY2021_Rx" SG_ 753 LpdbDfrstFrOn_B_Rq 1;
BA_ "U_CD764_MY2022_Rx" SG_ 753 LpdbDfrstFrOn_B_Rq 1;
BA_ "U_P702_MY2021_Rx" SG_ 753 LpdbDfrstFrOn_B_Rq 1;
BA_ "U_T6_MCA_MY2020_Rx" SG_ 753 LpdbDfrstFrOn_B_Rq 1;
BA_ "GenSigSendType" SG_ 753 LpdbDfrstFlOn_B_Rq 3;
BA_ "U_CX727_MY2021_Rx" SG_ 753 LpdbDfrstFlOn_B_Rq 1;
BA_ "U_CD542_MY2021_Rx" SG_ 753 LpdbDfrstFlOn_B_Rq 1;
BA_ "U_CD764_MY2022_Rx" SG_ 753 LpdbDfrstFlOn_B_Rq 1;
BA_ "U_P702_MY2021_Rx" SG_ 753 LpdbDfrstFlOn_B_Rq 1;
BA_ "U_T6_MCA_MY2020_Rx" SG_ 753 LpdbDfrstFlOn_B_Rq 1;
BA_ "GenSigSendType" SG_ 753 LpdbAuxBlwr_B_Rq 3;
BA_ "U_CX727_MY2021_Rx" SG_ 753 LpdbAuxBlwr_B_Rq 1;
BA_ "U_CD542_MY2021_Rx" SG_ 753 LpdbAuxBlwr_B_Rq 1;
BA_ "U_CD764_MY2022_Rx" SG_ 753 LpdbAuxBlwr_B_Rq 1;
BA_ "U_P702_MY2021_Rx" SG_ 753 LpdbAuxBlwr_B_Rq 1;
BA_ "U_T6_MCA_MY2020_Rx" SG_ 753 LpdbAuxBlwr_B_Rq 1;
BA_ "U_U55X_MY2022_Rx" SG_ 753 LpdbAuxBlwr_B_Rq 1;
BA_ "GenSigSendType" SG_ 753 ApaMdeStat_D_RqDrv 3;
BA_ "WakeupSignal" SG_ 753 Em_D_Stat 1;
BA_ "GenSigSendType" SG_ 753 Em_D_Stat 3;
BA_ "U_CX727_MY2021_Rx" SG_ 753 Em_D_Stat 1;
BA_ "U_P702_MY2021_Rx" SG_ 753 Em_D_Stat 1;
BA_ "U_T6_MCA_MY2020_Rx" SG_ 753 Em_D_Stat 1;
BA_ "U_CD542_MY2021_Rx" SG_ 753 Em_D_Stat 1;
BA_ "U_U55X_MY2022_Rx" SG_ 753 Em_D_Stat 1;
BA_ "U_CD764_MY2022_Rx" SG_ 753 Em_D_Stat 1;
BA_ "GenSigSendType" SG_ 753 PrkAidSwtch_No_Cnt 3;
BA_ "GenSigSendType" SG_ 753 PrkAidSwtch_D_RqDrv 3;
BA_ "GenSigSendType" SG_ 753 ValetMode_D_Stat 3;
BA_ "U_CX727_MY2021_Rx" SG_ 753 ValetMode_D_Stat 1;
BA_ "U_P702_MY2021_Rx" SG_ 753 ValetMode_D_Stat 1;
BA_ "U_T6_MCA_MY2020_Rx" SG_ 753 ValetMode_D_Stat 1;
BA_ "U_CD542_MY2021_Rx" SG_ 753 ValetMode_D_Stat 1;
BA_ "U_U55X_MY2022_Rx" SG_ 753 ValetMode_D_Stat 1;
BA_ "U_CD764_MY2022_Rx" SG_ 753 ValetMode_D_Stat 1;
BA_ "GenSigSendType" SG_ 753 RollCodeValet 3;
BA_ "U_CX727_MY2021_Rx" SG_ 753 RollCodeValet 1;
BA_ "U_P702_MY2021_Rx" SG_ 753 RollCodeValet 1;
BA_ "U_T6_MCA_MY2020_Rx" SG_ 753 RollCodeValet 1;
BA_ "U_CD542_MY2021_Rx" SG_ 753 RollCodeValet 1;
BA_ "U_U55X_MY2022_Rx" SG_ 753 RollCodeValet 1;
BA_ "U_CD764_MY2022_Rx" SG_ 753 RollCodeValet 1;
BA_ "WakeupSignal" SG_ 753 CnvtTopPos_Up_Stat 1;
BA_ "ContentDependant" SG_ 753 CnvtTopPos_Up_Stat 1;
BA_ "GenSigSendType" SG_ 753 CnvtTopPos_Up_Stat 3;
BA_ "U_CX727_MY2021_Rx" SG_ 753 CnvtTopPos_Up_Stat 1;
BA_ "U_P702_MY2021_Rx" SG_ 753 CnvtTopPos_Up_Stat 1;
BA_ "U_T6_MCA_MY2020_Rx" SG_ 753 CnvtTopPos_Up_Stat 1;
BA_ "U_CD542_MY2021_Rx" SG_ 753 CnvtTopPos_Up_Stat 1;
BA_ "U_U55X_MY2022_Rx" SG_ 753 CnvtTopPos_Up_Stat 1;
BA_ "U_CD764_MY2022_Rx" SG_ 753 CnvtTopPos_Up_Stat 1;
BA_ "U_CX727_MY2021_Rx" SG_ 753 CnvtTopPos_Dn_Stat_UB 1;
BA_ "U_P702_MY2021_Rx" SG_ 753 CnvtTopPos_Dn_Stat_UB 1;
BA_ "U_T6_MCA_MY2020_Rx" SG_ 753 CnvtTopPos_Dn_Stat_UB 1;
BA_ "U_CD542_MY2021_Rx" SG_ 753 CnvtTopPos_Dn_Stat_UB 1;
BA_ "U_U55X_MY2022_Rx" SG_ 753 CnvtTopPos_Dn_Stat_UB 1;
BA_ "U_CD764_MY2022_Rx" SG_ 753 CnvtTopPos_Dn_Stat_UB 1;
BA_ "WakeupSignal" SG_ 753 CnvtTopPos_Dn_Stat 1;
BA_ "ContentDependant" SG_ 753 CnvtTopPos_Dn_Stat 1;
BA_ "GenSigSendType" SG_ 753 CnvtTopPos_Dn_Stat 3;
BA_ "U_CX727_MY2021_Rx" SG_ 753 CnvtTopPos_Dn_Stat 1;
BA_ "U_P702_MY2021_Rx" SG_ 753 CnvtTopPos_Dn_Stat 1;
BA_ "U_T6_MCA_MY2020_Rx" SG_ 753 CnvtTopPos_Dn_Stat 1;
BA_ "U_CD542_MY2021_Rx" SG_ 753 CnvtTopPos_Dn_Stat 1;
BA_ "U_U55X_MY2022_Rx" SG_ 753 CnvtTopPos_Dn_Stat 1;
BA_ "U_CD764_MY2022_Rx" SG_ 753 CnvtTopPos_Dn_Stat 1;
BA_ "WakeupSignal" SG_ 818 DrPrsntDrv_D_Stat 1;
BA_ "U_T6_MCA_MY2020_Rx" SG_ 818 DrPrsntDrv_D_Stat 1;
BA_ "U_U55X_MY2022_Rx" SG_ 818 DrPrsntDrv_D_Stat 1;
BA_ "WakeupSignal" SG_ 818 DrPrsntRearDrv_D_Stat 1;
BA_ "U_T6_MCA_MY2020_Rx" SG_ 818 DrPrsntRearDrv_D_Stat 1;
BA_ "U_U55X_MY2022_Rx" SG_ 818 DrPrsntRearDrv_D_Stat 1;
BA_ "WakeupSignal" SG_ 818 ChildLckPw_N_Cnt 1;
BA_ "U_CX727_MY2021_Rx" SG_ 818 ChildLckPw_N_Cnt 1;
BA_ "U_P702_MY2021_Rx" SG_ 818 ChildLckPw_N_Cnt 1;
BA_ "U_T6_MCA_MY2020_Rx" SG_ 818 ChildLckPw_N_Cnt 1;
BA_ "U_CD542_MY2021_Rx" SG_ 818 ChildLckPw_N_Cnt 1;
BA_ "U_U55X_MY2022_Rx" SG_ 818 ChildLckPw_N_Cnt 1;
BA_ "U_CD764_MY2022_Rx" SG_ 818 ChildLckPw_N_Cnt 1;
BA_ "U_CX727_MY2021_Rx" SG_ 818 RollCodeDrvDrKeyCyl 1;
BA_ "U_P702_MY2021_Rx" SG_ 818 RollCodeDrvDrKeyCyl 1;
BA_ "U_T6_MCA_MY2020_Rx" SG_ 818 RollCodeDrvDrKeyCyl 1;
BA_ "U_CD542_MY2021_Rx" SG_ 818 RollCodeDrvDrKeyCyl 1;
BA_ "U_U55X_MY2022_Rx" SG_ 818 RollCodeDrvDrKeyCyl 1;
BA_ "U_CD764_MY2022_Rx" SG_ 818 RollCodeDrvDrKeyCyl 1;
BA_ "WakeupSignal" SG_ 818 KeyCylSwDrvDr_D_Stat 1;
BA_ "U_CX727_MY2021_Rx" SG_ 818 KeyCylSwDrvDr_D_Stat 1;
BA_ "U_P702_MY2021_Rx" SG_ 818 KeyCylSwDrvDr_D_Stat 1;
BA_ "U_T6_MCA_MY2020_Rx" SG_ 818 KeyCylSwDrvDr_D_Stat 1;
BA_ "U_CD542_MY2021_Rx" SG_ 818 KeyCylSwDrvDr_D_Stat 1;
BA_ "U_U55X_MY2022_Rx" SG_ 818 KeyCylSwDrvDr_D_Stat 1;
BA_ "U_CD764_MY2022_Rx" SG_ 818 KeyCylSwDrvDr_D_Stat 1;
BA_ "WakeupSignal" SG_ 818 Driver_Lock_Sw_Stat 1;
BA_ "U_CX727_MY2021_Rx" SG_ 818 Driver_Lock_Sw_Stat 1;
BA_ "U_P702_MY2021_Rx" SG_ 818 Driver_Lock_Sw_Stat 1;
BA_ "U_T6_MCA_MY2020_Rx" SG_ 818 Driver_Lock_Sw_Stat 1;
BA_ "U_CD542_MY2021_Rx" SG_ 818 Driver_Lock_Sw_Stat 1;
BA_ "U_U55X_MY2022_Rx" SG_ 818 Driver_Lock_Sw_Stat 1;
BA_ "U_CD764_MY2022_Rx" SG_ 818 Driver_Lock_Sw_Stat 1;
BA_ "WakeupSignal" SG_ 818 Driver_Lock_Sw_Cnt 1;
BA_ "MetaData" SG_ 818 Driver_Lock_Sw_Cnt 1;
BA_ "U_CX727_MY2021_Rx" SG_ 818 Driver_Lock_Sw_Cnt 1;
BA_ "U_P702_MY2021_Rx" SG_ 818 Driver_Lock_Sw_Cnt 1;
BA_ "U_T6_MCA_MY2020_Rx" SG_ 818 Driver_Lock_Sw_Cnt 1;
BA_ "U_CD542_MY2021_Rx" SG_ 818 Driver_Lock_Sw_Cnt 1;
BA_ "U_U55X_MY2022_Rx" SG_ 818 Driver_Lock_Sw_Cnt 1;
BA_ "U_CD764_MY2022_Rx" SG_ 818 Driver_Lock_Sw_Cnt 1;
BA_ "WakeupSignal" SG_ 818 ChildLckPw_D_Rq 1;
BA_ "U_CX727_MY2021_Rx" SG_ 818 ChildLckPw_D_Rq 1;
BA_ "U_P702_MY2021_Rx" SG_ 818 ChildLckPw_D_Rq 1;
BA_ "U_T6_MCA_MY2020_Rx" SG_ 818 ChildLckPw_D_Rq 1;
BA_ "U_CD542_MY2021_Rx" SG_ 818 ChildLckPw_D_Rq 1;
BA_ "U_U55X_MY2022_Rx" SG_ 818 ChildLckPw_D_Rq 1;
BA_ "U_CD764_MY2022_Rx" SG_ 818 ChildLckPw_D_Rq 1;
BA_ "WakeupSignal" SG_ 818 ChildLckFdbckRd_B_Stat 1;
BA_ "U_CX727_MY2021_Rx" SG_ 818 ChildLckFdbckRd_B_Stat 1;
BA_ "U_P702_MY2021_Rx" SG_ 818 ChildLckFdbckRd_B_Stat 1;
BA_ "U_T6_MCA_MY2020_Rx" SG_ 818 ChildLckFdbckRd_B_Stat 1;
BA_ "U_CD542_MY2021_Rx" SG_ 818 ChildLckFdbckRd_B_Stat 1;
BA_ "U_U55X_MY2022_Rx" SG_ 818 ChildLckFdbckRd_B_Stat 1;
BA_ "U_CD764_MY2022_Rx" SG_ 818 ChildLckFdbckRd_B_Stat 1;
BA_ "GenSigSendType" SG_ 817 ChildLckMde_B_Stat 3;
BA_ "U_CX727_MY2021_Tx" SG_ 817 ChildLckMde_B_Stat 1;
BA_ "U_P702_MY2021_Tx" SG_ 817 ChildLckMde_B_Stat 1;
BA_ "U_T6_MCA_MY2020_Tx" SG_ 817 ChildLckMde_B_Stat 1;
BA_ "U_CD542_MY2021_Tx" SG_ 817 ChildLckMde_B_Stat 1;
BA_ "U_U55X_MY2022_Tx" SG_ 817 ChildLckMde_B_Stat 1;
BA_ "U_CD764_MY2022_Tx" SG_ 817 ChildLckMde_B_Stat 1;
BA_ "GenSigSendType" SG_ 817 VehLckInd_D_Rq 3;
BA_ "U_CX727_MY2021_Tx" SG_ 817 VehLckInd_D_Rq 1;
BA_ "U_P702_MY2021_Tx" SG_ 817 VehLckInd_D_Rq 1;
BA_ "U_T6_MCA_MY2020_Tx" SG_ 817 VehLckInd_D_Rq 1;
BA_ "U_CD542_MY2021_Tx" SG_ 817 VehLckInd_D_Rq 1;
BA_ "U_U55X_MY2022_Tx" SG_ 817 VehLckInd_D_Rq 1;
BA_ "U_CD764_MY2022_Tx" SG_ 817 VehLckInd_D_Rq 1;
BA_ "WakeupSignal" SG_ 817 DrTgateOpen_B_Rq 1;
BA_ "GenSigSendType" SG_ 817 DrTgateOpen_B_Rq 3;
BA_ "U_CX727_MY2021_Tx" SG_ 817 DrTgateOpen_B_Rq 1;
BA_ "U_P702_MY2021_Tx" SG_ 817 DrTgateOpen_B_Rq 1;
BA_ "U_T6_MCA_MY2020_Tx" SG_ 817 DrTgateOpen_B_Rq 1;
BA_ "U_CD542_MY2021_Tx" SG_ 817 DrTgateOpen_B_Rq 1;
BA_ "U_U55X_MY2022_Tx" SG_ 817 DrTgateOpen_B_Rq 1;
BA_ "U_CD764_MY2022_Tx" SG_ 817 DrTgateOpen_B_Rq 1;
BA_ "WakeupSignal" SG_ 817 DrTgateExtSwMde_B_Stat 1;
BA_ "GenSigSendType" SG_ 817 DrTgateExtSwMde_B_Stat 3;
BA_ "U_CX727_MY2021_Tx" SG_ 817 DrTgateExtSwMde_B_Stat 1;
BA_ "U_P702_MY2021_Tx" SG_ 817 DrTgateExtSwMde_B_Stat 1;
BA_ "U_T6_MCA_MY2020_Tx" SG_ 817 DrTgateExtSwMde_B_Stat 1;
BA_ "U_CD542_MY2021_Tx" SG_ 817 DrTgateExtSwMde_B_Stat 1;
BA_ "U_U55X_MY2022_Tx" SG_ 817 DrTgateExtSwMde_B_Stat 1;
BA_ "U_CD764_MY2022_Tx" SG_ 817 DrTgateExtSwMde_B_Stat 1;
BA_ "WakeupSignal" SG_ 817 Remote_Device_Feedback 1;
BA_ "GenSigSendType" SG_ 817 Remote_Device_Feedback 3;
BA_ "U_T6_MCA_MY2020_Rx" SG_ 817 Remote_Device_Feedback 1;
BA_ "ECGUsedRxSignal" SG_ 817 Remote_Device_Feedback 1;
BA_ "U_CD542_MY2021_Rx" SG_ 817 Remote_Device_Feedback 1;
BA_ "U_U55X_MY2022_Rx" SG_ 817 Remote_Device_Feedback 1;
BA_ "U_CD764_MY2022_Rx" SG_ 817 Remote_Device_Feedback 1;
BA_ "U_CX727_MY2021_Tx" SG_ 817 Remote_Device_Feedback 1;
BA_ "U_P702_MY2021_Tx" SG_ 817 Remote_Device_Feedback 1;
BA_ "U_T6_MCA_MY2020_Tx" SG_ 817 Remote_Device_Feedback 1;
BA_ "U_CD542_MY2021_Tx" SG_ 817 Remote_Device_Feedback 1;
BA_ "U_U55X_MY2022_Tx" SG_ 817 Remote_Device_Feedback 1;
BA_ "U_CD764_MY2022_Tx" SG_ 817 Remote_Device_Feedback 1;
BA_ "WakeupSignal" SG_ 817 Veh_Lock_Requestor 1;
BA_ "GenSigSendType" SG_ 817 Veh_Lock_Requestor 3;
BA_ "U_CX727_MY2021_Tx" SG_ 817 Veh_Lock_Requestor 1;
BA_ "U_P702_MY2021_Tx" SG_ 817 Veh_Lock_Requestor 1;
BA_ "U_T6_MCA_MY2020_Tx" SG_ 817 Veh_Lock_Requestor 1;
BA_ "U_CD542_MY2021_Tx" SG_ 817 Veh_Lock_Requestor 1;
BA_ "U_U55X_MY2022_Tx" SG_ 817 Veh_Lock_Requestor 1;
BA_ "U_CD764_MY2022_Tx" SG_ 817 Veh_Lock_Requestor 1;
BA_ "WakeupSignal" SG_ 817 R_Pwr_Sliding_Dr_Rqst 1;
BA_ "GenSigSendType" SG_ 817 R_Pwr_Sliding_Dr_Rqst 3;
BA_ "U_CX727_MY2021_Tx" SG_ 817 R_Pwr_Sliding_Dr_Rqst 1;
BA_ "U_P702_MY2021_Tx" SG_ 817 R_Pwr_Sliding_Dr_Rqst 1;
BA_ "U_T6_MCA_MY2020_Tx" SG_ 817 R_Pwr_Sliding_Dr_Rqst 1;
BA_ "U_CD542_MY2021_Tx" SG_ 817 R_Pwr_Sliding_Dr_Rqst 1;
BA_ "U_U55X_MY2022_Tx" SG_ 817 R_Pwr_Sliding_Dr_Rqst 1;
BA_ "U_CD764_MY2022_Tx" SG_ 817 R_Pwr_Sliding_Dr_Rqst 1;
BA_ "WakeupSignal" SG_ 817 Power_Liftgate_Rqst 1;
BA_ "GenSigSendType" SG_ 817 Power_Liftgate_Rqst 3;
BA_ "U_CX727_MY2021_Tx" SG_ 817 Power_Liftgate_Rqst 1;
BA_ "U_P702_MY2021_Tx" SG_ 817 Power_Liftgate_Rqst 1;
BA_ "U_T6_MCA_MY2020_Tx" SG_ 817 Power_Liftgate_Rqst 1;
BA_ "U_CD542_MY2021_Tx" SG_ 817 Power_Liftgate_Rqst 1;
BA_ "U_U55X_MY2022_Tx" SG_ 817 Power_Liftgate_Rqst 1;
BA_ "U_CD764_MY2022_Tx" SG_ 817 Power_Liftgate_Rqst 1;
BA_ "WakeupSignal" SG_ 817 Veh_Lock_EvNum 1;
BA_ "GenSigSendType" SG_ 817 Veh_Lock_EvNum 3;
BA_ "U_CX727_MY2021_Tx" SG_ 817 Veh_Lock_EvNum 1;
BA_ "U_P702_MY2021_Tx" SG_ 817 Veh_Lock_EvNum 1;
BA_ "U_T6_MCA_MY2020_Tx" SG_ 817 Veh_Lock_EvNum 1;
BA_ "U_CD542_MY2021_Tx" SG_ 817 Veh_Lock_EvNum 1;
BA_ "U_U55X_MY2022_Tx" SG_ 817 Veh_Lock_EvNum 1;
BA_ "U_CD764_MY2022_Tx" SG_ 817 Veh_Lock_EvNum 1;
BA_ "WakeupSignal" SG_ 817 Power_Decklid_Rqst 1;
BA_ "GenSigSendType" SG_ 817 Power_Decklid_Rqst 3;
BA_ "U_CX727_MY2021_Tx" SG_ 817 Power_Decklid_Rqst 1;
BA_ "U_P702_MY2021_Tx" SG_ 817 Power_Decklid_Rqst 1;
BA_ "U_T6_MCA_MY2020_Tx" SG_ 817 Power_Decklid_Rqst 1;
BA_ "U_CD542_MY2021_Tx" SG_ 817 Power_Decklid_Rqst 1;
BA_ "U_U55X_MY2022_Tx" SG_ 817 Power_Decklid_Rqst 1;
BA_ "U_CD764_MY2022_Tx" SG_ 817 Power_Decklid_Rqst 1;
BA_ "WakeupSignal" SG_ 817 L_Pwr_Sliding_Dr_Rqst 1;
BA_ "GenSigSendType" SG_ 817 L_Pwr_Sliding_Dr_Rqst 3;
BA_ "U_CX727_MY2021_Tx" SG_ 817 L_Pwr_Sliding_Dr_Rqst 1;
BA_ "U_P702_MY2021_Tx" SG_ 817 L_Pwr_Sliding_Dr_Rqst 1;
BA_ "U_T6_MCA_MY2020_Tx" SG_ 817 L_Pwr_Sliding_Dr_Rqst 1;
BA_ "U_CD542_MY2021_Tx" SG_ 817 L_Pwr_Sliding_Dr_Rqst 1;
BA_ "U_U55X_MY2022_Tx" SG_ 817 L_Pwr_Sliding_Dr_Rqst 1;
BA_ "U_CD764_MY2022_Tx" SG_ 817 L_Pwr_Sliding_Dr_Rqst 1;
BA_ "WakeupSignal" SG_ 817 Keyfob_Pad_Msg_Count 1;
BA_ "GenSigSendType" SG_ 817 Keyfob_Pad_Msg_Count 3;
BA_ "U_CX727_MY2021_Tx" SG_ 817 Keyfob_Pad_Msg_Count 1;
BA_ "U_P702_MY2021_Tx" SG_ 817 Keyfob_Pad_Msg_Count 1;
BA_ "U_T6_MCA_MY2020_Tx" SG_ 817 Keyfob_Pad_Msg_Count 1;
BA_ "U_CD542_MY2021_Tx" SG_ 817 Keyfob_Pad_Msg_Count 1;
BA_ "U_U55X_MY2022_Tx" SG_ 817 Keyfob_Pad_Msg_Count 1;
BA_ "U_CD764_MY2022_Tx" SG_ 817 Keyfob_Pad_Msg_Count 1;
BA_ "GenSigSendType" SG_ 817 Veh_Lock_Sub_Id 3;
BA_ "U_CX727_MY2021_Tx" SG_ 817 Veh_Lock_Sub_Id 1;
BA_ "U_P702_MY2021_Tx" SG_ 817 Veh_Lock_Sub_Id 1;
BA_ "U_T6_MCA_MY2020_Tx" SG_ 817 Veh_Lock_Sub_Id 1;
BA_ "U_CD542_MY2021_Tx" SG_ 817 Veh_Lock_Sub_Id 1;
BA_ "U_U55X_MY2022_Tx" SG_ 817 Veh_Lock_Sub_Id 1;
BA_ "U_CD764_MY2022_Tx" SG_ 817 Veh_Lock_Sub_Id 1;
BA_ "WakeupSignal" SG_ 817 Veh_Lock_Status 1;
BA_ "GenSigStartValueInteger" SG_ 817 Veh_Lock_Status 1;
BA_ "GenSigStartValue" SG_ 817 Veh_Lock_Status 1;
BA_ "GenSigSendType" SG_ 817 Veh_Lock_Status 3;
BA_ "U_T6_MCA_MY2020_Rx" SG_ 817 Veh_Lock_Status 1;
BA_ "ECGUsedRxSignal" SG_ 817 Veh_Lock_Status 1;
BA_ "U_CD542_MY2021_Rx" SG_ 817 Veh_Lock_Status 1;
BA_ "U_U55X_MY2022_Rx" SG_ 817 Veh_Lock_Status 1;
BA_ "U_CD764_MY2022_Rx" SG_ 817 Veh_Lock_Status 1;
BA_ "U_CX727_MY2021_Tx" SG_ 817 Veh_Lock_Status 1;
BA_ "U_P702_MY2021_Tx" SG_ 817 Veh_Lock_Status 1;
BA_ "U_T6_MCA_MY2020_Tx" SG_ 817 Veh_Lock_Status 1;
BA_ "U_CD542_MY2021_Tx" SG_ 817 Veh_Lock_Status 1;
BA_ "U_U55X_MY2022_Tx" SG_ 817 Veh_Lock_Status 1;
BA_ "U_CD764_MY2022_Tx" SG_ 817 Veh_Lock_Status 1;
BA_ "WakeupSignal" SG_ 817 ChildLck_D_Dsply 1;
BA_ "GenSigStartValueInteger" SG_ 817 ChildLck_D_Dsply 1;
BA_ "GenSigStartValue" SG_ 817 ChildLck_D_Dsply 1;
BA_ "GenSigSendType" SG_ 817 ChildLck_D_Dsply 3;
BA_ "U_CX727_MY2021_Tx" SG_ 817 ChildLck_D_Dsply 1;
BA_ "U_P702_MY2021_Tx" SG_ 817 ChildLck_D_Dsply 1;
BA_ "U_T6_MCA_MY2020_Tx" SG_ 817 ChildLck_D_Dsply 1;
BA_ "U_CD542_MY2021_Tx" SG_ 817 ChildLck_D_Dsply 1;
BA_ "U_U55X_MY2022_Tx" SG_ 817 ChildLck_D_Dsply 1;
BA_ "U_CD764_MY2022_Tx" SG_ 817 ChildLck_D_Dsply 1;
BA_ "GenSigSendType" SG_ 817 WindowLockout_B_Stat 3;
BA_ "U_CX727_MY2021_Tx" SG_ 817 WindowLockout_B_Stat 1;
BA_ "U_P702_MY2021_Tx" SG_ 817 WindowLockout_B_Stat 1;
BA_ "U_T6_MCA_MY2020_Tx" SG_ 817 WindowLockout_B_Stat 1;
BA_ "U_CD542_MY2021_Tx" SG_ 817 WindowLockout_B_Stat 1;
BA_ "U_U55X_MY2022_Tx" SG_ 817 WindowLockout_B_Stat 1;
BA_ "U_CD764_MY2022_Tx" SG_ 817 WindowLockout_B_Stat 1;
BA_ "GenSigSendType" SG_ 817 RollCodeUnlock 3;
BA_ "U_T6_MCA_MY2020_Rx" SG_ 817 RollCodeUnlock 1;
BA_ "ECGUsedRxSignal" SG_ 817 RollCodeUnlock 1;
BA_ "U_CD542_MY2021_Rx" SG_ 817 RollCodeUnlock 1;
BA_ "U_U55X_MY2022_Rx" SG_ 817 RollCodeUnlock 1;
BA_ "U_CD764_MY2022_Rx" SG_ 817 RollCodeUnlock 1;
BA_ "U_CX727_MY2021_Tx" SG_ 817 RollCodeUnlock 1;
BA_ "U_P702_MY2021_Tx" SG_ 817 RollCodeUnlock 1;
BA_ "U_T6_MCA_MY2020_Tx" SG_ 817 RollCodeUnlock 1;
BA_ "U_CD542_MY2021_Tx" SG_ 817 RollCodeUnlock 1;
BA_ "U_U55X_MY2022_Tx" SG_ 817 RollCodeUnlock 1;
BA_ "U_CD764_MY2022_Tx" SG_ 817 RollCodeUnlock 1;
BA_ "WakeupSignal" SG_ 817 Lockmsgtxt_D_Rq 1;
BA_ "GenSigSendType" SG_ 817 Lockmsgtxt_D_Rq 3;
BA_ "U_CX727_MY2021_Tx" SG_ 817 Lockmsgtxt_D_Rq 1;
BA_ "U_P702_MY2021_Tx" SG_ 817 Lockmsgtxt_D_Rq 1;
BA_ "U_T6_MCA_MY2020_Tx" SG_ 817 Lockmsgtxt_D_Rq 1;
BA_ "U_CD542_MY2021_Tx" SG_ 817 Lockmsgtxt_D_Rq 1;
BA_ "U_U55X_MY2022_Tx" SG_ 817 Lockmsgtxt_D_Rq 1;
BA_ "U_CD764_MY2022_Tx" SG_ 817 Lockmsgtxt_D_Rq 1;
BA_ "GenSigSendType" SG_ 817 FobComm_D_Stat 3;
BA_ "U_CX727_MY2021_Tx" SG_ 817 FobComm_D_Stat 1;
BA_ "U_P702_MY2021_Tx" SG_ 817 FobComm_D_Stat 1;
BA_ "U_T6_MCA_MY2020_Tx" SG_ 817 FobComm_D_Stat 1;
BA_ "U_CD542_MY2021_Tx" SG_ 817 FobComm_D_Stat 1;
BA_ "U_U55X_MY2022_Tx" SG_ 817 FobComm_D_Stat 1;
BA_ "U_CD764_MY2022_Tx" SG_ 817 FobComm_D_Stat 1;
BA_ "WakeupSignal" SG_ 817 LockInhibit 1;
BA_ "GenSigSendType" SG_ 817 LockInhibit 3;
BA_ "U_CX727_MY2021_Tx" SG_ 817 LockInhibit 1;
BA_ "U_P702_MY2021_Tx" SG_ 817 LockInhibit 1;
BA_ "U_T6_MCA_MY2020_Tx" SG_ 817 LockInhibit 1;
BA_ "U_CD542_MY2021_Tx" SG_ 817 LockInhibit 1;
BA_ "U_U55X_MY2022_Tx" SG_ 817 LockInhibit 1;
BA_ "U_CD764_MY2022_Tx" SG_ 817 LockInhibit 1;
BA_ "GenSigSendType" SG_ 1002 FeatNoApimActl 3;
BA_ "GenSigSendType" SG_ 1002 FeatConfigApimActl 3;
BA_ "GenSigSendType" SG_ 1002 CntrStkKeycodeActl 3;
BA_ "U_CX727_MY2021_Rx" SG_ 1002 CntrStkKeycodeActl 1;
BA_ "U_P702_MY2021_Rx" SG_ 1002 CntrStkKeycodeActl 1;
BA_ "U_T6_MCA_MY2020_Rx" SG_ 1002 CntrStkKeycodeActl 1;
BA_ "U_CD542_MY2021_Rx" SG_ 1002 CntrStkKeycodeActl 1;
BA_ "U_U55X_MY2022_Rx" SG_ 1002 CntrStkKeycodeActl 1;
BA_ "U_CD764_MY2022_Rx" SG_ 1002 CntrStkKeycodeActl 1;
BA_ "WakeupSignal" SG_ 1002 CntrStk_D_RqRecall 1;
BA_ "GenSigSendType" SG_ 1002 CntrStk_D_RqRecall 3;
BA_ "U_CX727_MY2021_Rx" SG_ 1002 CntrStk_D_RqRecall 1;
BA_ "U_P702_MY2021_Rx" SG_ 1002 CntrStk_D_RqRecall 1;
BA_ "U_T6_MCA_MY2020_Rx" SG_ 1002 CntrStk_D_RqRecall 1;
BA_ "U_CD542_MY2021_Rx" SG_ 1002 CntrStk_D_RqRecall 1;
BA_ "U_U55X_MY2022_Rx" SG_ 1002 CntrStk_D_RqRecall 1;
BA_ "U_CD764_MY2022_Rx" SG_ 1002 CntrStk_D_RqRecall 1;
BA_ "GenSigStartValueInteger" SG_ 1002 CntrStk_D_RqAssoc 3;
BA_ "GenSigStartValue" SG_ 1002 CntrStk_D_RqAssoc 3;
BA_ "GenSigSendType" SG_ 1002 CntrStk_D_RqAssoc 3;
BA_ "U_CX727_MY2021_Rx" SG_ 1002 CntrStk_D_RqAssoc 1;
BA_ "U_P702_MY2021_Rx" SG_ 1002 CntrStk_D_RqAssoc 1;
BA_ "U_T6_MCA_MY2020_Rx" SG_ 1002 CntrStk_D_RqAssoc 1;
BA_ "U_CD542_MY2021_Rx" SG_ 1002 CntrStk_D_RqAssoc 1;
BA_ "U_U55X_MY2022_Rx" SG_ 1002 CntrStk_D_RqAssoc 1;
BA_ "U_CD764_MY2022_Rx" SG_ 1002 CntrStk_D_RqAssoc 1;
BA_ "GenSigStartValueInteger" SG_ 1002 PersIndexApim_D_Actl 4;
BA_ "GenSigStartValue" SG_ 1002 PersIndexApim_D_Actl 4;
BA_ "GenSigSendType" SG_ 1002 PersIndexApim_D_Actl 3;
BA_ "MetaData" SG_ 1046 BpedDiffLckTq_No_Cs 1;
BA_ "U_U55X_MY2022_Rx" SG_ 1046 BpedDiffLckTq_No_Cs 1;
BA_ "GenSigStartValueInteger" SG_ 1046 HsaMde_D_Mem 1;
BA_ "GenSigStartValue" SG_ 1046 HsaMde_D_Mem 1;
BA_ "GenSigStartValueInteger" SG_ 1046 StabCtlBrk_B_Avail 1;
BA_ "GenSigStartValue" SG_ 1046 StabCtlBrk_B_Avail 1;
BA_ "GenSigStartValueInteger" SG_ 1046 RearDiffLck_Tq2_RqMx 4094;
BA_ "GenSigStartValue" SG_ 1046 RearDiffLck_Tq2_RqMx 4094;
BA_ "U_U55X_MY2022_Rx" SG_ 1046 RearDiffLck_Tq2_RqMx 1;
BA_ "ContentDependant" SG_ 1046 TCMode 1;
BA_ "MetaData" SG_ 1046 BpedMove_No_Cnt 1;
BA_ "U_U55X_MY2022_Rx" SG_ 1046 BpedMove_No_Cnt 1;
BA_ "GenSigStartValueInteger" SG_ 1046 BpedMove_D_Actl 3;
BA_ "GenSigStartValue" SG_ 1046 BpedMove_D_Actl 3;
BA_ "U_U55X_MY2022_Rx" SG_ 1046 BpedMove_D_Actl 1;
BA_ "GenSigStartValueInteger" SG_ 125 VehRolComp_W_Actl 4094;
BA_ "GenSigStartValue" SG_ 125 VehRolComp_W_Actl 4094;
BA_ "GenSigStartValueInteger" SG_ 125 VehVertComp_A_Actl 1022;
BA_ "GenSigStartValue" SG_ 125 VehVertComp_A_Actl 1022;
BA_ "MetaData" SG_ 125 BrkTotTqRqArb_No_Cs 1;
BA_ "MetaData" SG_ 125 BrkTotTqRqArb_No_Cnt 1;
BA_ "GenSigStartValueInteger" SG_ 119 VehLongComp_A_Actl 1022;
BA_ "GenSigStartValue" SG_ 119 VehLongComp_A_Actl 1022;
BA_ "GenSigStartValueInteger" SG_ 119 VehLatComp_A_Actl 1022;
BA_ "GenSigStartValue" SG_ 119 VehLatComp_A_Actl 1022;
BA_ "GenSigStartValueInteger" SG_ 119 VehYawComp_W_Actl 4094;
BA_ "GenSigStartValue" SG_ 119 VehYawComp_W_Actl 4094;
BA_ "U_U55X_MY2022_Rx" SG_ 119 VehOverGnd_V_Est 1;
BA_ "GenSigStartValueInteger" SG_ 1045 VehStab_D_Stat 14;
BA_ "GenSigStartValue" SG_ 1045 VehStab_D_Stat 14;
BA_ "U_CX727_MY2021_Rx" SG_ 1045 BrkFluidLvl_D_Stat 1;
BA_ "U_P702_MY2021_Rx" SG_ 1045 BrkFluidLvl_D_Stat 1;
BA_ "U_T6_MCA_MY2020_Rx" SG_ 1045 BrkFluidLvl_D_Stat 1;
BA_ "U_CD542_MY2021_Rx" SG_ 1045 BrkFluidLvl_D_Stat 1;
BA_ "U_U55X_MY2022_Rx" SG_ 1045 BrkFluidLvl_D_Stat 1;
BA_ "U_CD764_MY2022_Rx" SG_ 1045 BrkFluidLvl_D_Stat 1;
BA_ "GenSigStartValueInteger" SG_ 1045 VehYawNonLin_W_Rq 4094;
BA_ "GenSigStartValue" SG_ 1045 VehYawNonLin_W_Rq 4094;
BA_ "GenSigStartValueInteger" SG_ 1045 VehYawLin_W_Rq 4094;
BA_ "GenSigStartValue" SG_ 1045 VehYawLin_W_Rq 4094;
BA_ "MetaData" SG_ 1045 VehVActlBrk_No_Cs 1;
BA_ "U_CX727_MY2021_Rx" SG_ 1045 VehVActlBrk_No_Cs 1;
BA_ "U_P702_MY2021_Rx" SG_ 1045 VehVActlBrk_No_Cs 1;
BA_ "U_T6_MCA_MY2020_Rx" SG_ 1045 VehVActlBrk_No_Cs 1;
BA_ "U_CD542_MY2021_Rx" SG_ 1045 VehVActlBrk_No_Cs 1;
BA_ "U_U55X_MY2022_Rx" SG_ 1045 VehVActlBrk_No_Cs 1;
BA_ "U_CD764_MY2022_Rx" SG_ 1045 VehVActlBrk_No_Cs 1;
BA_ "U_CX727_MY2021_Rx" SG_ 1045 Veh_V_ActlBrk 1;
BA_ "U_P702_MY2021_Rx" SG_ 1045 Veh_V_ActlBrk 1;
BA_ "U_T6_MCA_MY2020_Rx" SG_ 1045 Veh_V_ActlBrk 1;
BA_ "U_CD542_MY2021_Rx" SG_ 1045 Veh_V_ActlBrk 1;
BA_ "U_U55X_MY2022_Rx" SG_ 1045 Veh_V_ActlBrk 1;
BA_ "U_CD764_MY2022_Rx" SG_ 1045 Veh_V_ActlBrk 1;
BA_ "MetaData" SG_ 1045 VehVActlBrk_No_Cnt 1;
BA_ "U_CX727_MY2021_Rx" SG_ 1045 VehVActlBrk_No_Cnt 1;
BA_ "U_P702_MY2021_Rx" SG_ 1045 VehVActlBrk_No_Cnt 1;
BA_ "U_T6_MCA_MY2020_Rx" SG_ 1045 VehVActlBrk_No_Cnt 1;
BA_ "U_CD542_MY2021_Rx" SG_ 1045 VehVActlBrk_No_Cnt 1;
BA_ "U_U55X_MY2022_Rx" SG_ 1045 VehVActlBrk_No_Cnt 1;
BA_ "U_CD764_MY2022_Rx" SG_ 1045 VehVActlBrk_No_Cnt 1;
BA_ "MetaData" SG_ 1045 VehVActlBrk_D_Qf 1;
BA_ "U_CX727_MY2021_Rx" SG_ 1045 VehVActlBrk_D_Qf 1;
BA_ "U_P702_MY2021_Rx" SG_ 1045 VehVActlBrk_D_Qf 1;
BA_ "U_T6_MCA_MY2020_Rx" SG_ 1045 VehVActlBrk_D_Qf 1;
BA_ "U_CD542_MY2021_Rx" SG_ 1045 VehVActlBrk_D_Qf 1;
BA_ "U_U55X_MY2022_Rx" SG_ 1045 VehVActlBrk_D_Qf 1;
BA_ "U_CD764_MY2022_Rx" SG_ 1045 VehVActlBrk_D_Qf 1;
BA_ "U_CX727_MY2021_Rx" SG_ 534 WhlRotatRr_No_Cnt 1;
BA_ "U_P702_MY2021_Rx" SG_ 534 WhlRotatRr_No_Cnt 1;
BA_ "U_T6_MCA_MY2020_Rx" SG_ 534 WhlRotatRr_No_Cnt 1;
BA_ "U_CD542_MY2021_Rx" SG_ 534 WhlRotatRr_No_Cnt 1;
BA_ "U_U55X_MY2022_Rx" SG_ 534 WhlRotatRr_No_Cnt 1;
BA_ "U_CD764_MY2022_Rx" SG_ 534 WhlRotatRr_No_Cnt 1;
BA_ "U_CX727_MY2021_Rx" SG_ 534 WhlRotatRl_No_Cnt 1;
BA_ "U_P702_MY2021_Rx" SG_ 534 WhlRotatRl_No_Cnt 1;
BA_ "U_T6_MCA_MY2020_Rx" SG_ 534 WhlRotatRl_No_Cnt 1;
BA_ "U_CD542_MY2021_Rx" SG_ 534 WhlRotatRl_No_Cnt 1;
BA_ "U_U55X_MY2022_Rx" SG_ 534 WhlRotatRl_No_Cnt 1;
BA_ "U_CD764_MY2022_Rx" SG_ 534 WhlRotatRl_No_Cnt 1;
BA_ "U_CX727_MY2021_Rx" SG_ 534 WhlRotatFr_No_Cnt 1;
BA_ "U_P702_MY2021_Rx" SG_ 534 WhlRotatFr_No_Cnt 1;
BA_ "U_T6_MCA_MY2020_Rx" SG_ 534 WhlRotatFr_No_Cnt 1;
BA_ "U_CD542_MY2021_Rx" SG_ 534 WhlRotatFr_No_Cnt 1;
BA_ "U_U55X_MY2022_Rx" SG_ 534 WhlRotatFr_No_Cnt 1;
BA_ "U_CD764_MY2022_Rx" SG_ 534 WhlRotatFr_No_Cnt 1;
BA_ "U_CX727_MY2021_Rx" SG_ 534 WhlRotatFl_No_Cnt 1;
BA_ "U_P702_MY2021_Rx" SG_ 534 WhlRotatFl_No_Cnt 1;
BA_ "U_T6_MCA_MY2020_Rx" SG_ 534 WhlRotatFl_No_Cnt 1;
BA_ "U_CD542_MY2021_Rx" SG_ 534 WhlRotatFl_No_Cnt 1;
BA_ "U_U55X_MY2022_Rx" SG_ 534 WhlRotatFl_No_Cnt 1;
BA_ "U_CD764_MY2022_Rx" SG_ 534 WhlRotatFl_No_Cnt 1;
BA_ "ContentDependant" SG_ 534 BrkObdData_No_Actl 1;
BA_ "ContentDependant" SG_ 534 BrkObdIndex_No_Actl 1;
BA_ "GenSigStartValueInteger" SG_ 531 VehStop_D_Stat 2;
BA_ "GenSigStartValue" SG_ 531 VehStop_D_Stat 2;
BA_ "GenSigStartValueInteger" SG_ 531 VehLongOvrGnd_A_Est 511;
BA_ "WakeupSignal" SG_ 531 PrkBrkYwLamp_D_Rq 1;
BA_ "WakeupSignal" SG_ 531 PrkBrkRedLamp_D_Rq 1;
BA_ "WakeupSignal" SG_ 531 PrkBrkMsgTxt_D_Rq 1;
BA_ "GenSigStartValueInteger" SG_ 531 PrkBrkStatus 7;
BA_ "GenSigStartValue" SG_ 531 PrkBrkStatus 7;
BA_ "U_CX727_MY2021_Rx" SG_ 531 PrkBrkStatus 1;
BA_ "U_P702_MY2021_Rx" SG_ 531 PrkBrkStatus 1;
BA_ "U_T6_MCA_MY2020_Rx" SG_ 531 PrkBrkStatus 1;
BA_ "U_CD542_MY2021_Rx" SG_ 531 PrkBrkStatus 1;
BA_ "U_U55X_MY2022_Rx" SG_ 531 PrkBrkStatus 1;
BA_ "U_CD764_MY2022_Rx" SG_ 531 PrkBrkStatus 1;
BA_ "U_U55X_MY2022_Rx" SG_ 535 WhlRr_W_Meas 1;
BA_ "U_CX727_MY2021_Rx" SG_ 535 WhlRr_W_Meas 1;
BA_ "U_U55X_MY2022_Rx" SG_ 535 WhlRl_W_Meas 1;
BA_ "U_CX727_MY2021_Rx" SG_ 535 WhlRl_W_Meas 1;
BA_ "U_U55X_MY2022_Rx" SG_ 535 WhlFr_W_Meas 1;
BA_ "U_CX727_MY2021_Rx" SG_ 535 WhlFr_W_Meas 1;
BA_ "U_U55X_MY2022_Rx" SG_ 535 WhlFl_W_Meas 1;
BA_ "U_CX727_MY2021_Rx" SG_ 535 WhlFl_W_Meas 1;
BA_ "ContentDependant" SG_ 611 AwdStat_D_RqDsply 1;
BA_ "ContentDependant" SG_ 611 AwdSrvcRqd_B_Rq 1;
BA_ "ContentDependant" SG_ 611 AwdLck_Tq_Rq 1;
BA_ "U_U55X_MY2022_Rx" SG_ 611 AwdLck_Tq_Rq 1;
BA_ "GenSigStartValueInteger" SG_ 611 TrnAout_Tq_RqMx 8191;
BA_ "GenSigStartValue" SG_ 611 TrnAout_Tq_RqMx 8191;
BA_ "GenSigStartValueInteger" SG_ 611 AwdRnge_D_Actl 7;
BA_ "GenSigStartValue" SG_ 611 AwdRnge_D_Actl 7;
BA_ "U_U55X_MY2022_Rx" SG_ 611 AwdRnge_D_Actl 1;
BA_ "GenSigStartValueInteger" SG_ 1409 BCM_GWOnBoardTester 255;
BA_ "ContentDependant" SG_ 1409 BCM_GWOnBoardTester 1;
BA_ "GenSigStartValue" SG_ 1409 BCM_GWOnBoardTester 255;
BA_ "U_CX727_MY2021_Rx" SG_ 1409 BCM_GWOnBoardTester 1;
BA_ "U_CX727_MY2021_Tx" SG_ 1409 BCM_GWOnBoardTester 1;
BA_ "U_P702_MY2021_Tx" SG_ 1409 BCM_GWOnBoardTester 1;
BA_ "U_T6_MCA_MY2020_Tx" SG_ 1409 BCM_GWOnBoardTester 1;
BA_ "U_CD542_MY2021_Tx" SG_ 1409 BCM_GWOnBoardTester 1;
BA_ "U_U55X_MY2022_Tx" SG_ 1409 BCM_GWOnBoardTester 1;
BA_ "U_CD764_MY2022_Tx" SG_ 1409 BCM_GWOnBoardTester 1;
BA_ "GenSigStartValueInteger" SG_ 1409 BCM_GWNMProxy 255;
BA_ "ContentDependant" SG_ 1409 BCM_GWNMProxy 1;
BA_ "GenSigStartValue" SG_ 1409 BCM_GWNMProxy 255;
BA_ "U_CX727_MY2021_Rx" SG_ 1409 BCM_GWNMProxy 1;
BA_ "U_CX727_MY2021_Tx" SG_ 1409 BCM_GWNMProxy 1;
BA_ "U_P702_MY2021_Tx" SG_ 1409 BCM_GWNMProxy 1;
BA_ "U_T6_MCA_MY2020_Tx" SG_ 1409 BCM_GWNMProxy 1;
BA_ "U_CD542_MY2021_Tx" SG_ 1409 BCM_GWNMProxy 1;
BA_ "U_U55X_MY2022_Tx" SG_ 1409 BCM_GWNMProxy 1;
BA_ "U_CD764_MY2022_Tx" SG_ 1409 BCM_GWNMProxy 1;
BA_ "GenSigStartValueInteger" SG_ 1409 BCM_AutoSarNMReserved4 255;
BA_ "ContentDependant" SG_ 1409 BCM_AutoSarNMReserved4 1;
BA_ "GenSigStartValue" SG_ 1409 BCM_AutoSarNMReserved4 255;
BA_ "U_CX727_MY2021_Rx" SG_ 1409 BCM_AutoSarNMReserved4 1;
BA_ "U_CX727_MY2021_Tx" SG_ 1409 BCM_AutoSarNMReserved4 1;
BA_ "U_P702_MY2021_Tx" SG_ 1409 BCM_AutoSarNMReserved4 1;
BA_ "U_T6_MCA_MY2020_Tx" SG_ 1409 BCM_AutoSarNMReserved4 1;
BA_ "U_CD542_MY2021_Tx" SG_ 1409 BCM_AutoSarNMReserved4 1;
BA_ "U_U55X_MY2022_Tx" SG_ 1409 BCM_AutoSarNMReserved4 1;
BA_ "U_CD764_MY2022_Tx" SG_ 1409 BCM_AutoSarNMReserved4 1;
BA_ "GenSigStartValueInteger" SG_ 1409 BCM_AutoSarNMReserved3 255;
BA_ "ContentDependant" SG_ 1409 BCM_AutoSarNMReserved3 1;
BA_ "GenSigStartValue" SG_ 1409 BCM_AutoSarNMReserved3 255;
BA_ "U_CX727_MY2021_Rx" SG_ 1409 BCM_AutoSarNMReserved3 1;
BA_ "U_CX727_MY2021_Tx" SG_ 1409 BCM_AutoSarNMReserved3 1;
BA_ "U_P702_MY2021_Tx" SG_ 1409 BCM_AutoSarNMReserved3 1;
BA_ "U_T6_MCA_MY2020_Tx" SG_ 1409 BCM_AutoSarNMReserved3 1;
BA_ "U_CD542_MY2021_Tx" SG_ 1409 BCM_AutoSarNMReserved3 1;
BA_ "U_U55X_MY2022_Tx" SG_ 1409 BCM_AutoSarNMReserved3 1;
BA_ "U_CD764_MY2022_Tx" SG_ 1409 BCM_AutoSarNMReserved3 1;
BA_ "GenSigStartValueInteger" SG_ 1409 BCM_AutoSarNMReserved2 255;
BA_ "ContentDependant" SG_ 1409 BCM_AutoSarNMReserved2 1;
BA_ "GenSigStartValue" SG_ 1409 BCM_AutoSarNMReserved2 255;
BA_ "U_CX727_MY2021_Rx" SG_ 1409 BCM_AutoSarNMReserved2 1;
BA_ "U_CX727_MY2021_Tx" SG_ 1409 BCM_AutoSarNMReserved2 1;
BA_ "U_P702_MY2021_Tx" SG_ 1409 BCM_AutoSarNMReserved2 1;
BA_ "U_T6_MCA_MY2020_Tx" SG_ 1409 BCM_AutoSarNMReserved2 1;
BA_ "U_CD542_MY2021_Tx" SG_ 1409 BCM_AutoSarNMReserved2 1;
BA_ "U_U55X_MY2022_Tx" SG_ 1409 BCM_AutoSarNMReserved2 1;
BA_ "U_CD764_MY2022_Tx" SG_ 1409 BCM_AutoSarNMReserved2 1;
BA_ "GenSigStartValueInteger" SG_ 1409 BCM_AutoSarNMReserved1 255;
BA_ "ContentDependant" SG_ 1409 BCM_AutoSarNMReserved1 1;
BA_ "GenSigStartValue" SG_ 1409 BCM_AutoSarNMReserved1 255;
BA_ "U_CX727_MY2021_Rx" SG_ 1409 BCM_AutoSarNMReserved1 1;
BA_ "U_CX727_MY2021_Tx" SG_ 1409 BCM_AutoSarNMReserved1 1;
BA_ "U_P702_MY2021_Tx" SG_ 1409 BCM_AutoSarNMReserved1 1;
BA_ "U_T6_MCA_MY2020_Tx" SG_ 1409 BCM_AutoSarNMReserved1 1;
BA_ "U_CD542_MY2021_Tx" SG_ 1409 BCM_AutoSarNMReserved1 1;
BA_ "U_U55X_MY2022_Tx" SG_ 1409 BCM_AutoSarNMReserved1 1;
BA_ "U_CD764_MY2022_Tx" SG_ 1409 BCM_AutoSarNMReserved1 1;
BA_ "GenSigStartValueInteger" SG_ 1409 BCM_AutoSarNMNodeId 81;
BA_ "ContentDependant" SG_ 1409 BCM_AutoSarNMNodeId 1;
BA_ "GenSigStartValue" SG_ 1409 BCM_AutoSarNMNodeId 129;
BA_ "U_CX727_MY2021_Rx" SG_ 1409 BCM_AutoSarNMNodeId 1;
BA_ "U_CX727_MY2021_Tx" SG_ 1409 BCM_AutoSarNMNodeId 1;
BA_ "U_P702_MY2021_Tx" SG_ 1409 BCM_AutoSarNMNodeId 1;
BA_ "U_T6_MCA_MY2020_Tx" SG_ 1409 BCM_AutoSarNMNodeId 1;
BA_ "U_CD542_MY2021_Tx" SG_ 1409 BCM_AutoSarNMNodeId 1;
BA_ "U_U55X_MY2022_Tx" SG_ 1409 BCM_AutoSarNMNodeId 1;
BA_ "U_CD764_MY2022_Tx" SG_ 1409 BCM_AutoSarNMNodeId 1;
BA_ "ContentDependant" SG_ 1409 BCM_AutoSarNMControl 1;
BA_ "U_CX727_MY2021_Rx" SG_ 1409 BCM_AutoSarNMControl 1;
BA_ "U_CX727_MY2021_Tx" SG_ 1409 BCM_AutoSarNMControl 1;
BA_ "U_P702_MY2021_Tx" SG_ 1409 BCM_AutoSarNMControl 1;
BA_ "U_T6_MCA_MY2020_Tx" SG_ 1409 BCM_AutoSarNMControl 1;
BA_ "U_CD542_MY2021_Tx" SG_ 1409 BCM_AutoSarNMControl 1;
BA_ "U_U55X_MY2022_Tx" SG_ 1409 BCM_AutoSarNMControl 1;
BA_ "U_CD764_MY2022_Tx" SG_ 1409 BCM_AutoSarNMControl 1;
BA_ "ContentDependant" SG_ 90 TrnGsmNtmState_D_Actl 1;
BA_ "GenSigStartValueInteger" SG_ 90 DrQltyDrv_D_StatGsm 6;
BA_ "ContentDependant" SG_ 90 DrQltyDrv_D_StatGsm 1;
BA_ "GenSigStartValue" SG_ 90 DrQltyDrv_D_StatGsm 6;
BA_ "ContentDependant" SG_ 90 TrnBtsiOvrrd_B_Stat 1;
BA_ "GenSigStartValueInteger" SG_ 90 TrnRng_D_RqGsm 14;
BA_ "GenSigStartValue" SG_ 90 TrnRng_D_RqGsm 14;
BA_ "ContentDependant" SG_ 90 TrnValidGearRq_D_Stat 1;
BA_ "ContentDependant" SG_ 90 TrnGearRqCnt_B_Actl 1;
BA_ "WakeupSignal" SG_ 90 TrnGearButtn_U_Actl 1;
BA_ "ContentDependant" SG_ 90 TrnGearButtn_U_Actl 1;
BA_ "WakeupSignal" SG_ 90 TrnGearButtn_B_ActlR2 1;
BA_ "ContentDependant" SG_ 90 TrnGearButtn_B_ActlR2 1;
BA_ "WakeupSignal" SG_ 90 TrnGearButtn_B_ActlR1 1;
BA_ "ContentDependant" SG_ 90 TrnGearButtn_B_ActlR1 1;
BA_ "WakeupSignal" SG_ 90 TrnGearButtn_B_ActlR0 1;
BA_ "ContentDependant" SG_ 90 TrnGearButtn_B_ActlR0 1;
BA_ "WakeupSignal" SG_ 90 TrnGearButtn_B_ActlP2 1;
BA_ "ContentDependant" SG_ 90 TrnGearButtn_B_ActlP2 1;
BA_ "WakeupSignal" SG_ 90 TrnGearButtn_B_ActlP1 1;
BA_ "ContentDependant" SG_ 90 TrnGearButtn_B_ActlP1 1;
BA_ "WakeupSignal" SG_ 90 TrnGearButtn_B_ActlP0 1;
BA_ "ContentDependant" SG_ 90 TrnGearButtn_B_ActlP0 1;
BA_ "WakeupSignal" SG_ 90 TrnGearButtn_B_ActlN2 1;
BA_ "ContentDependant" SG_ 90 TrnGearButtn_B_ActlN2 1;
BA_ "WakeupSignal" SG_ 90 TrnGearButtn_B_ActlN1 1;
BA_ "ContentDependant" SG_ 90 TrnGearButtn_B_ActlN1 1;
BA_ "WakeupSignal" SG_ 90 TrnGearButtn_B_ActlN0 1;
BA_ "ContentDependant" SG_ 90 TrnGearButtn_B_ActlN0 1;
BA_ "WakeupSignal" SG_ 90 TrnGearButtn_B_ActlM2 1;
BA_ "ContentDependant" SG_ 90 TrnGearButtn_B_ActlM2 1;
BA_ "WakeupSignal" SG_ 90 TrnGearButtn_B_ActlM1 1;
BA_ "ContentDependant" SG_ 90 TrnGearButtn_B_ActlM1 1;
BA_ "WakeupSignal" SG_ 90 TrnGearButtn_B_ActlM0 1;
BA_ "ContentDependant" SG_ 90 TrnGearButtn_B_ActlM0 1;
BA_ "WakeupSignal" SG_ 90 TrnGearButtn_B_ActlD2 1;
BA_ "ContentDependant" SG_ 90 TrnGearButtn_B_ActlD2 1;
BA_ "WakeupSignal" SG_ 90 TrnGearButtn_B_ActlD1 1;
BA_ "ContentDependant" SG_ 90 TrnGearButtn_B_ActlD1 1;
BA_ "WakeupSignal" SG_ 90 TrnGearButtn_B_ActlD0 1;
BA_ "ContentDependant" SG_ 90 TrnGearButtn_B_ActlD0 1;
BA_ "ContentDependant" SG_ 90 TrnGear_No_Cs 1;
BA_ "MetaData" SG_ 90 TrnGear_No_Cs 1;
BA_ "ContentDependant" SG_ 90 TrnGear_No_Cnt 1;
BA_ "MetaData" SG_ 90 TrnGear_No_Cnt 1;
BA_ "WakeupSignal" SG_ 90 TrnGear_D_RqDrv 1;
BA_ "ContentDependant" SG_ 90 TrnGear_D_RqDrv 1;
BA_ "U_CX727_MY2021_Rx" SG_ 90 TrnGear_D_RqDrv 1;
BA_ "U_P702_MY2021_Rx" SG_ 90 TrnGear_D_RqDrv 1;
BA_ "U_T6_MCA_MY2020_Rx" SG_ 90 TrnGear_D_RqDrv 1;
BA_ "U_CD542_MY2021_Rx" SG_ 90 TrnGear_D_RqDrv 1;
BA_ "U_U55X_MY2022_Rx" SG_ 90 TrnGear_D_RqDrv 1;
BA_ "U_CD764_MY2022_Rx" SG_ 90 TrnGear_D_RqDrv 1;
BA_ "ContentDependant" SG_ 90 BrkSwtchPos_B_ActlGsm 1;
BA_ "U_CX727_MY2021_Rx" SG_ 1109 eCallConfirmation 1;
BA_ "U_P702_MY2021_Rx" SG_ 1109 eCallConfirmation 1;
BA_ "U_T6_MCA_MY2020_Rx" SG_ 1109 eCallConfirmation 1;
BA_ "U_CD542_MY2021_Rx" SG_ 1109 eCallConfirmation 1;
BA_ "U_U55X_MY2022_Rx" SG_ 1109 eCallConfirmation 1;
BA_ "U_CD764_MY2022_Rx" SG_ 1109 eCallConfirmation 1;
BA_ "ContentDependant" SG_ 92 TrnGearMsgTxt2_D_Rq 1;
BA_ "GenSigStartValueInteger" SG_ 92 TrnLvrV_D_Rq 1;
BA_ "GenSigStartValue" SG_ 92 TrnLvrV_D_Rq 1;
BA_ "GenSigSendType" SG_ 92 TrnLvrV_D_Rq 3;
BA_ "GenSigStartValueInteger" SG_ 92 TrnSbwSysHlth_D_Actl 1;
BA_ "ContentDependant" SG_ 92 TrnSbwSysHlth_D_Actl 1;
BA_ "GenSigStartValue" SG_ 92 TrnSbwSysHlth_D_Actl 1;
BA_ "GenSigSendType" SG_ 92 TrnSbwSysHlth_D_Actl 3;
BA_ "ContentDependant" SG_ 92 TrnGearNtmAllow_B_Stat 1;
BA_ "GenSigSendType" SG_ 92 TrnGearNtmAllow_B_Stat 3;
BA_ "WakeupSignal" SG_ 92 TrnDtpCmd_D_Actl 1;
BA_ "GenSigStartValueInteger" SG_ 92 TrnDtpCmd_D_Actl 1;
BA_ "ContentDependant" SG_ 92 TrnDtpCmd_D_Actl 1;
BA_ "GenSigStartValue" SG_ 92 TrnDtpCmd_D_Actl 1;
BA_ "GenSigSendType" SG_ 92 GearSelLck_D_Rq 3;
BA_ "ContentDependant" SG_ 92 TrnGearCmd_No_Cs 1;
BA_ "MetaData" SG_ 92 TrnGearCmd_No_Cs 1;
BA_ "ContentDependant" SG_ 92 TrnValidGear_D_Cnfm 1;
BA_ "GenSigSendType" SG_ 92 TrnValidGear_D_Cnfm 3;
BA_ "ContentDependant" SG_ 92 TrnNtrlTowCmd_D_Actl 1;
BA_ "GenSigSendType" SG_ 92 TrnNtrlTowCmd_D_Actl 3;
BA_ "ContentDependant" SG_ 92 TrnGearCmd_Pc_ActlPt 1;
BA_ "ContentDependant" SG_ 92 TrnGear_D_RqPt 1;
BA_ "GenSigSendType" SG_ 92 TrnGear_D_RqPt 3;
BA_ "U_CX727_MY2021_Rx" SG_ 92 TrnGear_D_RqPt 1;
BA_ "ContentDependant" SG_ 92 TrnCmdState_B_Actl 1;
BA_ "GenSigSendType" SG_ 92 TrnCmdState_B_Actl 3;
BA_ "ContentDependant" SG_ 92 TrnCmdCnt_B_Actl 1;
BA_ "GenSigSendType" SG_ 92 TrnCmdCnt_B_Actl 3;
BA_ "GenSigStartValueInteger" SG_ 92 PrkBrkActv_D_RqTrnGear 1;
BA_ "ContentDependant" SG_ 92 PrkBrkActv_D_RqTrnGear 1;
BA_ "GenSigStartValue" SG_ 92 PrkBrkActv_D_RqTrnGear 1;
BA_ "GenSigSendType" SG_ 92 PrkBrkActv_D_RqTrnGear 3;
BA_ "ContentDependant" SG_ 92 TrnGearMsgTxt_D_Rq 1;
BA_ "GenSigSendType" SG_ 92 TrnGearMsgTxt_D_Rq 3;
BA_ "ContentDependant" SG_ 92 TrnGearCmd_No_Cnt 1;
BA_ "MetaData" SG_ 92 TrnGearCmd_No_Cnt 1;
BA_ "GenSigStartValueInteger" SG_ 359 PrplWhlRgenMn_Tq_Actl 4095;
BA_ "ContentDependant" SG_ 359 TrnAin_Tq_Actl 1;
BA_ "U_U55X_MY2022_Rx" SG_ 359 PrplWhlTot2_Tq_Actl 1;
BA_ "U_CX727_MY2021_Rx" SG_ 359 PwPckTq_D_Stat 1;
BA_ "U_P702_MY2021_Rx" SG_ 359 PwPckTq_D_Stat 1;
BA_ "U_CD542_MY2021_Rx" SG_ 359 PwPckTq_D_Stat 1;
BA_ "U_T6_MCA_MY2020_Rx" SG_ 359 PwPckTq_D_Stat 1;
BA_ "U_U55X_MY2022_Rx" SG_ 359 PwPckTq_D_Stat 1;
BA_ "U_CD764_MY2022_Rx" SG_ 359 PwPckTq_D_Stat 1;
BA_ "U_CX727_MY2021_Rx" SG_ 359 Eng_D_Stat 1;
BA_ "U_P702_MY2021_Rx" SG_ 359 Eng_D_Stat 1;
BA_ "U_T6_MCA_MY2020_Rx" SG_ 359 Eng_D_Stat 1;
BA_ "U_CD542_MY2021_Rx" SG_ 359 Eng_D_Stat 1;
BA_ "U_U55X_MY2022_Rx" SG_ 359 Eng_D_Stat 1;
BA_ "U_CD764_MY2022_Rx" SG_ 359 Eng_D_Stat 1;
BA_ "GenSigStartValueInteger" SG_ 359 PlgActvArb_B_Actl 1;
BA_ "ContentDependant" SG_ 359 PlgActvArb_B_Actl 1;
BA_ "GenSigStartValue" SG_ 359 PlgActvArb_B_Actl 1;
BA_ "U_CX727_MY2021_Rx" SG_ 359 PlgActvArb_B_Actl 1;
BA_ "U_P702_MY2021_Rx" SG_ 359 PlgActvArb_B_Actl 1;
BA_ "U_T6_MCA_MY2020_Rx" SG_ 359 PlgActvArb_B_Actl 1;
BA_ "U_CD542_MY2021_Rx" SG_ 359 PlgActvArb_B_Actl 1;
BA_ "U_U55X_MY2022_Rx" SG_ 359 PlgActvArb_B_Actl 1;
BA_ "U_CD764_MY2022_Rx" SG_ 359 PlgActvArb_B_Actl 1;
BA_ "U_CX727_MY2021_Rx" SG_ 359 ElPw_D_Stat 1;
BA_ "U_P702_MY2021_Rx" SG_ 359 ElPw_D_Stat 1;
BA_ "U_T6_MCA_MY2020_Rx" SG_ 359 ElPw_D_Stat 1;
BA_ "U_CD542_MY2021_Rx" SG_ 359 ElPw_D_Stat 1;
BA_ "U_U55X_MY2022_Rx" SG_ 359 ElPw_D_Stat 1;
BA_ "U_CD764_MY2022_Rx" SG_ 359 ElPw_D_Stat 1;
BA_ "ContentDependant" SG_ 359 TrnAinTq_D_Qf 1;
BA_ "MetaData" SG_ 359 TrnAinTq_D_Qf 1;
BA_ "U_CX727_MY2021_Rx" SG_ 358 StopStrtDrvMde_D_Indic 1;
BA_ "U_P702_MY2021_Rx" SG_ 358 StopStrtDrvMde_D_Indic 1;
BA_ "U_T6_MCA_MY2020_Rx" SG_ 358 StopStrtDrvMde_D_Indic 1;
BA_ "U_CD542_MY2021_Rx" SG_ 358 StopStrtDrvMde_D_Indic 1;
BA_ "U_U55X_MY2022_Rx" SG_ 358 StopStrtDrvMde_D_Indic 1;
BA_ "U_CD764_MY2022_Rx" SG_ 358 StopStrtDrvMde_D_Indic 1;
BA_ "ContentDependant" SG_ 358 HiElPwInhbt_B_Stat 1;
BA_ "GenSigStartValueInteger" SG_ 358 AutoStopPtDelta_I_Est 127;
BA_ "ContentDependant" SG_ 358 AutoStopPtDelta_I_Est 1;
BA_ "U_CX727_MY2021_Rx" SG_ 358 AutoStopPtDelta_I_Est 1;
BA_ "U_P702_MY2021_Rx" SG_ 358 AutoStopPtDelta_I_Est 1;
BA_ "U_T6_MCA_MY2020_Rx" SG_ 358 AutoStopPtDelta_I_Est 1;
BA_ "U_CD542_MY2021_Rx" SG_ 358 AutoStopPtDelta_I_Est 1;
BA_ "U_U55X_MY2022_Rx" SG_ 358 AutoStopPtDelta_I_Est 1;
BA_ "U_CD764_MY2022_Rx" SG_ 358 AutoStopPtDelta_I_Est 1;
BA_ "GenSigStartValueInteger" SG_ 1084 BattULoChrg_URate_RqMx 5;
BA_ "GenSigStartValue" SG_ 1084 BattULoChrg_URate_RqMx 5;
BA_ "U_CX727_MY2021_Tx" SG_ 1084 BattULoChrg_URate_RqMx 1;
BA_ "U_P702_MY2021_Tx" SG_ 1084 BattULoChrg_URate_RqMx 1;
BA_ "U_T6_MCA_MY2020_Tx" SG_ 1084 BattULoChrg_URate_RqMx 1;
BA_ "U_CD542_MY2021_Tx" SG_ 1084 BattULoChrg_URate_RqMx 1;
BA_ "U_U55X_MY2022_Tx" SG_ 1084 BattULoChrg_URate_RqMx 1;
BA_ "U_CD764_MY2022_Tx" SG_ 1084 BattULoChrg_URate_RqMx 1;
BA_ "GenSigStartValueInteger" SG_ 1084 BattULoChrg_U_RqMx 34;
BA_ "GenSigStartValue" SG_ 1084 BattULoChrg_U_RqMx 34;
BA_ "U_CX727_MY2021_Tx" SG_ 1084 BattULoChrg_U_RqMx 1;
BA_ "U_P702_MY2021_Tx" SG_ 1084 BattULoChrg_U_RqMx 1;
BA_ "U_T6_MCA_MY2020_Tx" SG_ 1084 BattULoChrg_U_RqMx 1;
BA_ "U_CD542_MY2021_Tx" SG_ 1084 BattULoChrg_U_RqMx 1;
BA_ "U_U55X_MY2022_Tx" SG_ 1084 BattULoChrg_U_RqMx 1;
BA_ "U_CD764_MY2022_Tx" SG_ 1084 BattULoChrg_U_RqMx 1;
BA_ "U_CX727_MY2021_Tx" SG_ 1084 BattULoChrg_U_RqMn 1;
BA_ "U_P702_MY2021_Tx" SG_ 1084 BattULoChrg_U_RqMn 1;
BA_ "U_T6_MCA_MY2020_Tx" SG_ 1084 BattULoChrg_U_RqMn 1;
BA_ "U_CD542_MY2021_Tx" SG_ 1084 BattULoChrg_U_RqMn 1;
BA_ "U_U55X_MY2022_Tx" SG_ 1084 BattULoChrg_U_RqMn 1;
BA_ "U_CD764_MY2022_Tx" SG_ 1084 BattULoChrg_U_RqMn 1;
BA_ "U_T6_MCA_MY2020_Rx" SG_ 1084 BattULoState_D_Qlty 1;
BA_ "ECGUsedRxSignal" SG_ 1084 BattULoState_D_Qlty 1;
BA_ "U_CD542_MY2021_Rx" SG_ 1084 BattULoState_D_Qlty 1;
BA_ "U_U55X_MY2022_Rx" SG_ 1084 BattULoState_D_Qlty 1;
BA_ "U_CD764_MY2022_Rx" SG_ 1084 BattULoState_D_Qlty 1;
BA_ "U_CX727_MY2021_Tx" SG_ 1084 BattULoState_D_Qlty 1;
BA_ "U_P702_MY2021_Tx" SG_ 1084 BattULoState_D_Qlty 1;
BA_ "U_T6_MCA_MY2020_Tx" SG_ 1084 BattULoState_D_Qlty 1;
BA_ "U_CD542_MY2021_Tx" SG_ 1084 BattULoState_D_Qlty 1;
BA_ "U_U55X_MY2022_Tx" SG_ 1084 BattULoState_D_Qlty 1;
BA_ "U_CD764_MY2022_Tx" SG_ 1084 BattULoState_D_Qlty 1;
BA_ "U_CX727_MY2021_Tx" SG_ 1084 BSFault 1;
BA_ "U_P702_MY2021_Tx" SG_ 1084 BSFault 1;
BA_ "U_T6_MCA_MY2020_Tx" SG_ 1084 BSFault 1;
BA_ "U_CD542_MY2021_Tx" SG_ 1084 BSFault 1;
BA_ "U_U55X_MY2022_Tx" SG_ 1084 BSFault 1;
BA_ "U_CD764_MY2022_Tx" SG_ 1084 BSFault 1;
BA_ "GenSigStartValueInteger" SG_ 1084 BattULo2_Te_Actl 127;
BA_ "GenSigStartValue" SG_ 1084 BattULo2_Te_Actl 127;
BA_ "U_T6_MCA_MY2020_Rx" SG_ 1084 BattULo2_Te_Actl 1;
BA_ "ECGUsedRxSignal" SG_ 1084 BattULo2_Te_Actl 1;
BA_ "U_CD542_MY2021_Rx" SG_ 1084 BattULo2_Te_Actl 1;
BA_ "U_U55X_MY2022_Rx" SG_ 1084 BattULo2_Te_Actl 1;
BA_ "U_CD764_MY2022_Rx" SG_ 1084 BattULo2_Te_Actl 1;
BA_ "U_CX727_MY2021_Tx" SG_ 1084 BattULo2_Te_Actl 1;
BA_ "U_P702_MY2021_Tx" SG_ 1084 BattULo2_Te_Actl 1;
BA_ "U_T6_MCA_MY2020_Tx" SG_ 1084 BattULo2_Te_Actl 1;
BA_ "U_CD542_MY2021_Tx" SG_ 1084 BattULo2_Te_Actl 1;
BA_ "U_U55X_MY2022_Tx" SG_ 1084 BattULo2_Te_Actl 1;
BA_ "U_CD764_MY2022_Tx" SG_ 1084 BattULo2_Te_Actl 1;
BA_ "U_T6_MCA_MY2020_Rx" SG_ 1084 BSBattSOC 1;
BA_ "ECGUsedRxSignal" SG_ 1084 BSBattSOC 1;
BA_ "U_CD542_MY2021_Rx" SG_ 1084 BSBattSOC 1;
BA_ "U_U55X_MY2022_Rx" SG_ 1084 BSBattSOC 1;
BA_ "U_CD764_MY2022_Rx" SG_ 1084 BSBattSOC 1;
BA_ "U_CX727_MY2021_Tx" SG_ 1084 BSBattSOC 1;
BA_ "U_P702_MY2021_Tx" SG_ 1084 BSBattSOC 1;
BA_ "U_T6_MCA_MY2020_Tx" SG_ 1084 BSBattSOC 1;
BA_ "U_CD542_MY2021_Tx" SG_ 1084 BSBattSOC 1;
BA_ "U_U55X_MY2022_Tx" SG_ 1084 BSBattSOC 1;
BA_ "U_CD764_MY2022_Tx" SG_ 1084 BSBattSOC 1;
BA_ "GenSigStartValueInteger" SG_ 1084 BSBattQDeltaRideAh 12800;
BA_ "U_CX727_MY2021_Tx" SG_ 1084 BSBattQDeltaRideAh 1;
BA_ "U_P702_MY2021_Tx" SG_ 1084 BSBattQDeltaRideAh 1;
BA_ "U_T6_MCA_MY2020_Tx" SG_ 1084 BSBattQDeltaRideAh 1;
BA_ "U_CD542_MY2021_Tx" SG_ 1084 BSBattQDeltaRideAh 1;
BA_ "U_U55X_MY2022_Tx" SG_ 1084 BSBattQDeltaRideAh 1;
BA_ "U_CD764_MY2022_Tx" SG_ 1084 BSBattQDeltaRideAh 1;
BA_ "U_T6_MCA_MY2020_Rx" SG_ 1084 BSBattQCapAh 1;
BA_ "ECGUsedRxSignal" SG_ 1084 BSBattQCapAh 1;
BA_ "U_CD542_MY2021_Rx" SG_ 1084 BSBattQCapAh 1;
BA_ "U_U55X_MY2022_Rx" SG_ 1084 BSBattQCapAh 1;
BA_ "U_CD764_MY2022_Rx" SG_ 1084 BSBattQCapAh 1;
BA_ "U_CX727_MY2021_Tx" SG_ 1084 BSBattQCapAh 1;
BA_ "U_P702_MY2021_Tx" SG_ 1084 BSBattQCapAh 1;
BA_ "U_T6_MCA_MY2020_Tx" SG_ 1084 BSBattQCapAh 1;
BA_ "U_CD542_MY2021_Tx" SG_ 1084 BSBattQCapAh 1;
BA_ "U_U55X_MY2022_Tx" SG_ 1084 BSBattQCapAh 1;
BA_ "U_CD764_MY2022_Tx" SG_ 1084 BSBattQCapAh 1;
BA_ "GenSigStartValueInteger" SG_ 1086 AwdPtu_Te_Actl 50;
BA_ "GenSigStartValueInteger" SG_ 1086 EngMnfld_P_Actl 2068;
BA_ "GenSigStartValueInteger" SG_ 1086 EngIpcDsplyCht_Te_Actl 75;
BA_ "GenSigStartValue" SG_ 1086 EngIpcDsplyCht_Te_Actl 75;
BA_ "U_CX727_MY2021_Rx" SG_ 1086 FuelPumpPwr_B_Rq 1;
BA_ "U_P702_MY2021_Rx" SG_ 1086 FuelPumpPwr_B_Rq 1;
BA_ "U_T6_MCA_MY2020_Rx" SG_ 1086 FuelPumpPwr_B_Rq 1;
BA_ "U_CD542_MY2021_Rx" SG_ 1086 FuelPumpPwr_B_Rq 1;
BA_ "U_U55X_MY2022_Rx" SG_ 1086 FuelPumpPwr_B_Rq 1;
BA_ "U_CD764_MY2022_Rx" SG_ 1086 FuelPumpPwr_B_Rq 1;
BA_ "U_CX727_MY2021_Rx" SG_ 1086 BattULoChrg_U_Cmd 1;
BA_ "U_P702_MY2021_Rx" SG_ 1086 BattULoChrg_U_Cmd 1;
BA_ "U_CD542_MY2021_Rx" SG_ 1086 BattULoChrg_U_Cmd 1;
BA_ "U_T6_MCA_MY2020_Rx" SG_ 1086 BattULoChrg_U_Cmd 1;
BA_ "U_U55X_MY2022_Rx" SG_ 1086 BattULoChrg_U_Cmd 1;
BA_ "U_CD764_MY2022_Rx" SG_ 1086 BattULoChrg_U_Cmd 1;
BA_ "ContentDependant" SG_ 1086 ElLoadCtl_D_Rq 1;
BA_ "U_CX727_MY2021_Rx" SG_ 1086 ElLoadCtl_D_Rq 1;
BA_ "U_P702_MY2021_Rx" SG_ 1086 ElLoadCtl_D_Rq 1;
BA_ "U_T6_MCA_MY2020_Rx" SG_ 1086 ElLoadCtl_D_Rq 1;
BA_ "U_CD542_MY2021_Rx" SG_ 1086 ElLoadCtl_D_Rq 1;
BA_ "U_U55X_MY2022_Rx" SG_ 1086 ElLoadCtl_D_Rq 1;
BA_ "U_CD764_MY2022_Rx" SG_ 1086 ElLoadCtl_D_Rq 1;
BA_ "U_CX727_MY2021_Rx" SG_ 1085 PwSrcULoOvrTe_B_Actl 1;
BA_ "U_P702_MY2021_Rx" SG_ 1085 PwSrcULoOvrTe_B_Actl 1;
BA_ "U_T6_MCA_MY2020_Rx" SG_ 1085 PwSrcULoOvrTe_B_Actl 1;
BA_ "U_U55X_MY2022_Rx" SG_ 1085 PwSrcULoOvrTe_B_Actl 1;
BA_ "U_CD764_MY2022_Rx" SG_ 1085 PwSrcULoOvrTe_B_Actl 1;
BA_ "ECGUsedRxSignal" SG_ 1085 PwSrcULoOvrTe_B_Actl 1;
BA_ "U_CX727_MY2021_Tx" SG_ 1085 PwSrcULoOvrTe_B_Actl 1;
BA_ "U_P702_MY2021_Tx" SG_ 1085 PwSrcULoOvrTe_B_Actl 1;
BA_ "U_CD542_MY2021_Tx" SG_ 1085 PwSrcULoOvrTe_B_Actl 1;
BA_ "U_CX727_MY2021_Rx" SG_ 1085 PwSrcULoOn_B_Actl 1;
BA_ "ECGUsedRxSignal" SG_ 1085 PwSrcULoOn_B_Actl 1;
BA_ "U_U55X_MY2022_Rx" SG_ 1085 PwSrcULoOn_B_Actl 1;
BA_ "U_CX727_MY2021_Tx" SG_ 1085 PwSrcULoOn_B_Actl 1;
BA_ "U_P702_MY2021_Tx" SG_ 1085 PwSrcULoOn_B_Actl 1;
BA_ "U_CD542_MY2021_Tx" SG_ 1085 PwSrcULoOn_B_Actl 1;
BA_ "U_CX727_MY2021_Rx" SG_ 1085 PwSrcULoFalt_D_Stat 1;
BA_ "U_P702_MY2021_Rx" SG_ 1085 PwSrcULoFalt_D_Stat 1;
BA_ "U_T6_MCA_MY2020_Rx" SG_ 1085 PwSrcULoFalt_D_Stat 1;
BA_ "U_U55X_MY2022_Rx" SG_ 1085 PwSrcULoFalt_D_Stat 1;
BA_ "U_CD764_MY2022_Rx" SG_ 1085 PwSrcULoFalt_D_Stat 1;
BA_ "ECGUsedRxSignal" SG_ 1085 PwSrcULoFalt_D_Stat 1;
BA_ "U_CX727_MY2021_Tx" SG_ 1085 PwSrcULoFalt_D_Stat 1;
BA_ "U_P702_MY2021_Tx" SG_ 1085 PwSrcULoFalt_D_Stat 1;
BA_ "U_CD542_MY2021_Tx" SG_ 1085 PwSrcULoFalt_D_Stat 1;
BA_ "U_CX727_MY2021_Rx" SG_ 1085 PwSrcULoDcnnt_B_Stat 1;
BA_ "U_P702_MY2021_Rx" SG_ 1085 PwSrcULoDcnnt_B_Stat 1;
BA_ "U_T6_MCA_MY2020_Rx" SG_ 1085 PwSrcULoDcnnt_B_Stat 1;
BA_ "U_CD542_MY2021_Rx" SG_ 1085 PwSrcULoDcnnt_B_Stat 1;
BA_ "U_U55X_MY2022_Rx" SG_ 1085 PwSrcULoDcnnt_B_Stat 1;
BA_ "U_CD764_MY2022_Rx" SG_ 1085 PwSrcULoDcnnt_B_Stat 1;
BA_ "U_CX727_MY2021_Tx" SG_ 1085 PwSrcULoDcnnt_B_Stat 1;
BA_ "U_P702_MY2021_Tx" SG_ 1085 PwSrcULoDcnnt_B_Stat 1;
BA_ "U_CD542_MY2021_Tx" SG_ 1085 PwSrcULoDcnnt_B_Stat 1;
BA_ "U_CX727_MY2021_Rx" SG_ 1085 PwSrcULo_Pc_Mx 1;
BA_ "U_P702_MY2021_Rx" SG_ 1085 PwSrcULo_Pc_Mx 1;
BA_ "U_T6_MCA_MY2020_Rx" SG_ 1085 PwSrcULo_Pc_Mx 1;
BA_ "U_CD542_MY2021_Rx" SG_ 1085 PwSrcULo_Pc_Mx 1;
BA_ "U_U55X_MY2022_Rx" SG_ 1085 PwSrcULo_Pc_Mx 1;
BA_ "U_CD764_MY2022_Rx" SG_ 1085 PwSrcULo_Pc_Mx 1;
BA_ "U_CX727_MY2021_Tx" SG_ 1085 PwSrcULo_Pc_Mx 1;
BA_ "U_P702_MY2021_Tx" SG_ 1085 PwSrcULo_Pc_Mx 1;
BA_ "U_CD542_MY2021_Tx" SG_ 1085 PwSrcULo_Pc_Mx 1;
BA_ "ContentDependant" SG_ 1085 DcdcULo_U_Actl 1;
BA_ "U_CX727_MY2021_Rx" SG_ 1085 DcdcULo_U_Actl 1;
BA_ "U_P702_MY2021_Rx" SG_ 1085 DcdcULo_U_Actl 1;
BA_ "U_CX727_MY2021_Tx" SG_ 1085 DcdcULo_U_Actl 1;
BA_ "U_P702_MY2021_Tx" SG_ 1085 DcdcULo_U_Actl 1;
BA_ "U_CD542_MY2021_Tx" SG_ 1085 DcdcULo_U_Actl 1;
BA_ "ContentDependant" SG_ 1085 DcdcUHi_I_Actl 1;
BA_ "U_CX727_MY2021_Rx" SG_ 1085 DcdcUHi_I_Actl 1;
BA_ "U_CD542_MY2021_Rx" SG_ 1085 DcdcUHi_I_Actl 1;
BA_ "U_U55X_MY2022_Rx" SG_ 1085 DcdcUHi_I_Actl 1;
BA_ "U_CX727_MY2021_Tx" SG_ 1085 DcdcUHi_I_Actl 1;
BA_ "U_P702_MY2021_Tx" SG_ 1085 DcdcUHi_I_Actl 1;
BA_ "U_CD542_MY2021_Tx" SG_ 1085 DcdcUHi_I_Actl 1;
BA_ "U_CX727_MY2021_Rx" SG_ 1085 PwSrcULo_I_Mx 1;
BA_ "U_P702_MY2021_Rx" SG_ 1085 PwSrcULo_I_Mx 1;
BA_ "U_T6_MCA_MY2020_Rx" SG_ 1085 PwSrcULo_I_Mx 1;
BA_ "U_CD542_MY2021_Rx" SG_ 1085 PwSrcULo_I_Mx 1;
BA_ "U_U55X_MY2022_Rx" SG_ 1085 PwSrcULo_I_Mx 1;
BA_ "U_CD764_MY2022_Rx" SG_ 1085 PwSrcULo_I_Mx 1;
BA_ "U_CX727_MY2021_Tx" SG_ 1085 PwSrcULo_I_Mx 1;
BA_ "U_P702_MY2021_Tx" SG_ 1085 PwSrcULo_I_Mx 1;
BA_ "U_CD542_MY2021_Tx" SG_ 1085 PwSrcULo_I_Mx 1;
BA_ "U_CX727_MY2021_Rx" SG_ 1085 PwSrcULo_I_Actl 1;
BA_ "U_P702_MY2021_Rx" SG_ 1085 PwSrcULo_I_Actl 1;
BA_ "U_T6_MCA_MY2020_Rx" SG_ 1085 PwSrcULo_I_Actl 1;
BA_ "U_CD542_MY2021_Rx" SG_ 1085 PwSrcULo_I_Actl 1;
BA_ "U_U55X_MY2022_Rx" SG_ 1085 PwSrcULo_I_Actl 1;
BA_ "U_CD764_MY2022_Rx" SG_ 1085 PwSrcULo_I_Actl 1;
BA_ "U_CX727_MY2021_Tx" SG_ 1085 PwSrcULo_I_Actl 1;
BA_ "U_P702_MY2021_Tx" SG_ 1085 PwSrcULo_I_Actl 1;
BA_ "U_CD542_MY2021_Tx" SG_ 1085 PwSrcULo_I_Actl 1;
BA_ "ContentDependant" SG_ 1085 DcdcUHi_U_Actl 1;
BA_ "U_CX727_MY2021_Rx" SG_ 1085 DcdcUHi_U_Actl 1;
BA_ "U_P702_MY2021_Rx" SG_ 1085 DcdcUHi_U_Actl 1;
BA_ "U_CD542_MY2021_Rx" SG_ 1085 DcdcUHi_U_Actl 1;
BA_ "U_U55X_MY2022_Rx" SG_ 1085 DcdcUHi_U_Actl 1;
BA_ "U_CX727_MY2021_Tx" SG_ 1085 DcdcUHi_U_Actl 1;
BA_ "U_P702_MY2021_Tx" SG_ 1085 DcdcUHi_U_Actl 1;
BA_ "U_CD542_MY2021_Tx" SG_ 1085 DcdcUHi_U_Actl 1;
BA_ "ContentDependant" SG_ 603 WhlDirAvgDrv_D_Actl 1;
BA_ "ContentDependant" SG_ 603 PrplTqMnRgen_B_Actl 1;
BA_ "U_CX727_MY2021_Rx" SG_ 603 PrplWhlTot_Tq_Cmd 1;
BA_ "GenSigStartValueInteger" SG_ 603 EDrvTqMntrRconfg_D_Cmd 7;
BA_ "GenSigStartValue" SG_ 603 EDrvTqMntrRconfg_D_Cmd 7;
BA_ "GenSigStartValueInteger" SG_ 603 BattTracCnnct_D_Rq 2;
BA_ "ContentDependant" SG_ 603 BattTracCnnct_D_Rq 1;
BA_ "GenSigStartValue" SG_ 603 BattTracCnnct_D_Rq 2;
BA_ "U_CX727_MY2021_Rx" SG_ 603 BattTracCnnct_D_Rq 1;
BA_ "U_P702_MY2021_Rx" SG_ 603 BattTracCnnct_D_Rq 1;
BA_ "U_CD542_MY2021_Rx" SG_ 603 BattTracCnnct_D_Rq 1;
BA_ "ECGUsedRxSignal" SG_ 602 HtrnWarnLamp_B_Dsply 1;
BA_ "U_CD542_MY2021_Rx" SG_ 602 HtrnWarnLamp_B_Dsply 1;
BA_ "GenSigStartValue" SG_ 602 BattTracRsrvSoc_Pc_Rq 16382;
BA_ "GenSigStartValueInteger" SG_ 587 BattTracClnt_Te_Actl 164;
BA_ "GenSigStartValue" SG_ 587 BattTracClnt_Te_Actl 254;
BA_ "U_CX727_MY2021_Tx" SG_ 587 BattTracClnt_Te_Actl 1;
BA_ "U_P702_MY2021_Tx" SG_ 587 BattTracClnt_Te_Actl 1;
BA_ "U_CD542_MY2021_Tx" SG_ 587 BattTracClnt_Te_Actl 1;
BA_ "ECGUsedRxSignal" SG_ 587 BattTracWarnLamp_B_Rq 1;
BA_ "U_CD542_MY2021_Rx" SG_ 587 BattTracWarnLamp_B_Rq 1;
BA_ "U_U55X_MY2022_Rx" SG_ 587 BattTracWarnLamp_B_Rq 1;
BA_ "U_CX727_MY2021_Tx" SG_ 587 BattTracWarnLamp_B_Rq 1;
BA_ "U_P702_MY2021_Tx" SG_ 587 BattTracWarnLamp_B_Rq 1;
BA_ "U_CD542_MY2021_Tx" SG_ 587 BattTracWarnLamp_B_Rq 1;
BA_ "ECGUsedRxSignal" SG_ 587 BattTracSrvcRqd_B_Rq 1;
BA_ "U_CD542_MY2021_Rx" SG_ 587 BattTracSrvcRqd_B_Rq 1;
BA_ "U_U55X_MY2022_Rx" SG_ 587 BattTracSrvcRqd_B_Rq 1;
BA_ "U_CX727_MY2021_Tx" SG_ 587 BattTracSrvcRqd_B_Rq 1;
BA_ "U_P702_MY2021_Tx" SG_ 587 BattTracSrvcRqd_B_Rq 1;
BA_ "U_CD542_MY2021_Tx" SG_ 587 BattTracSrvcRqd_B_Rq 1;
BA_ "GenSigStartValueInteger" SG_ 587 BattTracSoc_Pc_MxPrtct 700;
BA_ "GenSigStartValue" SG_ 587 BattTracSoc_Pc_MxPrtct 700;
BA_ "U_CX727_MY2021_Tx" SG_ 587 BattTracSoc_Pc_MxPrtct 1;
BA_ "U_P702_MY2021_Tx" SG_ 587 BattTracSoc_Pc_MxPrtct 1;
BA_ "U_CD542_MY2021_Tx" SG_ 587 BattTracSoc_Pc_MxPrtct 1;
BA_ "GenSigStartValueInteger" SG_ 587 BattTracSoc_Pc_MnPrtct 300;
BA_ "GenSigStartValue" SG_ 587 BattTracSoc_Pc_MnPrtct 30;
BA_ "U_CX727_MY2021_Tx" SG_ 587 BattTracSoc_Pc_MnPrtct 1;
BA_ "U_P702_MY2021_Tx" SG_ 587 BattTracSoc_Pc_MnPrtct 1;
BA_ "U_CD542_MY2021_Tx" SG_ 587 BattTracSoc_Pc_MnPrtct 1;
BA_ "GenSigStartValueInteger" SG_ 587 BattTracSoc_Pc_LimLo 400;
BA_ "GenSigStartValue" SG_ 587 BattTracSoc_Pc_LimLo 400;
BA_ "U_CX727_MY2021_Tx" SG_ 587 BattTracSoc_Pc_LimLo 1;
BA_ "U_P702_MY2021_Tx" SG_ 587 BattTracSoc_Pc_LimLo 1;
BA_ "U_CD542_MY2021_Tx" SG_ 587 BattTracSoc_Pc_LimLo 1;
BA_ "GenSigStartValueInteger" SG_ 587 BattTracSoc_Pc_LimHi 600;
BA_ "GenSigStartValue" SG_ 587 BattTracSoc_Pc_LimHi 600;
BA_ "U_CX727_MY2021_Tx" SG_ 587 BattTracSoc_Pc_LimHi 1;
BA_ "U_P702_MY2021_Tx" SG_ 587 BattTracSoc_Pc_LimHi 1;
BA_ "U_CD542_MY2021_Tx" SG_ 587 BattTracSoc_Pc_LimHi 1;
BA_ "GenSigStartValue" SG_ 1040 VehSimSnd_Pc_Rq 511;
BA_ "GenSigStartValueInteger" SG_ 1040 BattTrac_I2_EstVsc 15000;
BA_ "GenSigStartValue" SG_ 1040 BattTrac_I2_EstVsc 262142;
BA_ "U_CX727_MY2021_Rx" SG_ 1040 ElCmprEnbl_B_Rq 1;
BA_ "U_P702_MY2021_Rx" SG_ 1040 ElCmprEnbl_B_Rq 1;
BA_ "U_CD542_MY2021_Rx" SG_ 1040 ElCmprEnbl_B_Rq 1;
BA_ "U_CX727_MY2021_Rx" SG_ 1040 ElCmpr_N_Rq 1;
BA_ "U_P702_MY2021_Rx" SG_ 1040 ElCmpr_N_Rq 1;
BA_ "U_CD542_MY2021_Rx" SG_ 1040 ElCmpr_N_Rq 1;
BA_ "U_CX727_MY2021_Tx" SG_ 1041 ElCmprPerfErr_D_Falt 1;
BA_ "U_P702_MY2021_Tx" SG_ 1041 ElCmprPerfErr_D_Falt 1;
BA_ "U_CD542_MY2021_Tx" SG_ 1041 ElCmprPerfErr_D_Falt 1;
BA_ "U_CX727_MY2021_Tx" SG_ 1041 ElCmprInnrErr_D_Falt 1;
BA_ "U_P702_MY2021_Tx" SG_ 1041 ElCmprInnrErr_D_Falt 1;
BA_ "U_CD542_MY2021_Tx" SG_ 1041 ElCmprInnrErr_D_Falt 1;
BA_ "U_CX727_MY2021_Tx" SG_ 1041 ElCmprLostComm_D_Falt 1;
BA_ "U_P702_MY2021_Tx" SG_ 1041 ElCmprLostComm_D_Falt 1;
BA_ "U_CD542_MY2021_Tx" SG_ 1041 ElCmprLostComm_D_Falt 1;
BA_ "U_CX727_MY2021_Tx" SG_ 1041 ElCmprOverLoad_D_Falt 1;
BA_ "U_P702_MY2021_Tx" SG_ 1041 ElCmprOverLoad_D_Falt 1;
BA_ "U_CD542_MY2021_Tx" SG_ 1041 ElCmprOverLoad_D_Falt 1;
BA_ "U_CX727_MY2021_Tx" SG_ 1041 ElCmprOverTe_D_Falt 1;
BA_ "U_P702_MY2021_Tx" SG_ 1041 ElCmprOverTe_D_Falt 1;
BA_ "U_CD542_MY2021_Tx" SG_ 1041 ElCmprOverTe_D_Falt 1;
BA_ "U_CX727_MY2021_Tx" SG_ 1041 ElCmprBattURng_D_Falt 1;
BA_ "U_P702_MY2021_Tx" SG_ 1041 ElCmprBattURng_D_Falt 1;
BA_ "U_CD542_MY2021_Tx" SG_ 1041 ElCmprBattURng_D_Falt 1;
BA_ "U_CX727_MY2021_Tx" SG_ 1041 ElCmprBattSysU_D_Falt 1;
BA_ "U_P702_MY2021_Tx" SG_ 1041 ElCmprBattSysU_D_Falt 1;
BA_ "U_CD542_MY2021_Tx" SG_ 1041 ElCmprBattSysU_D_Falt 1;
BA_ "U_CX727_MY2021_Tx" SG_ 1041 ElCmprSysU_D_Falt 1;
BA_ "U_P702_MY2021_Tx" SG_ 1041 ElCmprSysU_D_Falt 1;
BA_ "U_CD542_MY2021_Tx" SG_ 1041 ElCmprSysU_D_Falt 1;
BA_ "U_CX727_MY2021_Tx" SG_ 1041 ElCmprUHi_U_Actl 1;
BA_ "U_P702_MY2021_Tx" SG_ 1041 ElCmprUHi_U_Actl 1;
BA_ "U_CD542_MY2021_Tx" SG_ 1041 ElCmprUHi_U_Actl 1;
BA_ "U_CX727_MY2021_Tx" SG_ 1041 ElCmprUHi_D_Stat 1;
BA_ "U_P702_MY2021_Tx" SG_ 1041 ElCmprUHi_D_Stat 1;
BA_ "U_CD542_MY2021_Tx" SG_ 1041 ElCmprUHi_D_Stat 1;
BA_ "U_CX727_MY2021_Tx" SG_ 1041 ElCmprOverTe_D_Stat 1;
BA_ "U_P702_MY2021_Tx" SG_ 1041 ElCmprOverTe_D_Stat 1;
BA_ "U_CD542_MY2021_Tx" SG_ 1041 ElCmprOverTe_D_Stat 1;
BA_ "U_CX727_MY2021_Tx" SG_ 1041 ElCmpr_N_Actl 1;
BA_ "U_P702_MY2021_Tx" SG_ 1041 ElCmpr_N_Actl 1;
BA_ "U_CD542_MY2021_Tx" SG_ 1041 ElCmpr_N_Actl 1;
BA_ "U_CX727_MY2021_Tx" SG_ 1041 ElCmpr_Pw_Actl 1;
BA_ "U_P702_MY2021_Tx" SG_ 1041 ElCmpr_Pw_Actl 1;
BA_ "U_CD542_MY2021_Tx" SG_ 1041 ElCmpr_Pw_Actl 1;
BA_ "U_CX727_MY2021_Tx" SG_ 1041 ElCmpr_D_Stat 1;
BA_ "U_P702_MY2021_Tx" SG_ 1041 ElCmpr_D_Stat 1;
BA_ "U_CD542_MY2021_Tx" SG_ 1041 ElCmpr_D_Stat 1;
BA_ "GenSigSendType" SG_ 1999 TesterPhysicalResACCM 3;
BA_ "U_CX727_MY2021_Tx" SG_ 1999 TesterPhysicalResACCM 1;
BA_ "U_P702_MY2021_Tx" SG_ 1999 TesterPhysicalResACCM 1;
BA_ "U_CD542_MY2021_Tx" SG_ 1999 TesterPhysicalResACCM 1;
BA_ "GenSigSendType" SG_ 1991 TesterPhysicalReqACCM 3;
BA_ "U_CX727_MY2021_Rx" SG_ 1991 TesterPhysicalReqACCM 1;
BA_ "U_P702_MY2021_Rx" SG_ 1991 TesterPhysicalReqACCM 1;
BA_ "U_CD542_MY2021_Rx" SG_ 1991 TesterPhysicalReqACCM 1;
BA_ "GenSigStartValue" SG_ 1088 TrlrRng_L_Dsply 8190;
BA_ "WakeupSignal" SG_ 1088 HvacPrecondMode2_D_Rq 1;
BA_ "ContentDependant" SG_ 1088 HvacPrecondMode2_D_Rq 1;
BA_ "WakeupSignal" SG_ 1088 HvacPrecondBlwr2_D_Rq 1;
BA_ "ContentDependant" SG_ 1088 HvacPrecondBlwr2_D_Rq 1;
BA_ "GenSigStartValueInteger" SG_ 1088 HvacPrecond_Te_Rq 2;
BA_ "GenSigStartValue" SG_ 1088 HvacPrecond_Te_Rq 2;
BA_ "GenSigStartValue" SG_ 1088 BattDcChrgRms_I_Lim 32766;
BA_ "U_CX727_MY2021_Rx" SG_ 1088 BattChrgInhbt_D_Rq 1;
BA_ "U_CD542_MY2021_Rx" SG_ 1088 BattChrgInhbt_D_Rq 1;
BA_ "WakeupSignal" SG_ 1088 ChrgStat_D2_Dsply 1;
BA_ "GenSigStartValueInteger" SG_ 869 EffWhlLvl2_Pc_Dsply 511;
BA_ "GenSigStartValue" SG_ 869 EffWhlLvl2_Pc_Dsply 511;
BA_ "GenSigStartValueInteger" SG_ 870 RngPerChrgInst_L_Dsply 4094;
BA_ "GenSigStartValue" SG_ 870 RngPerChrgInst_L_Dsply 4093;
BA_ "GenSigStartValue" SG_ 870 EffRgenThres_Pc_Dsply 1023;
BA_ "U_CX727_MY2021_Rx" SG_ 130 TrlrHitchLamp_D_Rqst 1;
BA_ "U_P702_MY2021_Rx" SG_ 130 TrlrHitchLamp_D_Rqst 1;
BA_ "U_T6_MCA_MY2020_Rx" SG_ 130 TrlrHitchLamp_D_Rqst 1;
BA_ "U_CD542_MY2021_Rx" SG_ 130 TrlrHitchLamp_D_Rqst 1;
BA_ "U_U55X_MY2022_Rx" SG_ 130 TrlrHitchLamp_D_Rqst 1;
BA_ "U_CD764_MY2022_Rx" SG_ 130 TrlrHitchLamp_D_Rqst 1;
BA_ "GenSigStartValueInteger" SG_ 130 Veh_V_RqMxTrlrAid 255;
BA_ "GenSigStartValue" SG_ 130 Veh_V_RqMxTrlrAid 255;
BA_ "GenSigStartValueInteger" SG_ 130 DrvSte_Tq_Actl 128;
BA_ "GenSigStartValueInteger" SG_ 130 SteMdule_U_Meas 255;
BA_ "GenSigStartValue" SG_ 130 SteMdule_U_Meas 255;
BA_ "U_CX727_MY2021_Rx" SG_ 130 SteMdule_U_Meas 1;
BA_ "U_P702_MY2021_Rx" SG_ 130 SteMdule_U_Meas 1;
BA_ "U_T6_MCA_MY2020_Rx" SG_ 130 SteMdule_U_Meas 1;
BA_ "U_CD542_MY2021_Rx" SG_ 130 SteMdule_U_Meas 1;
BA_ "U_U55X_MY2022_Rx" SG_ 130 SteMdule_U_Meas 1;
BA_ "U_CD764_MY2022_Rx" SG_ 130 SteMdule_U_Meas 1;
BA_ "GenSigStartValueInteger" SG_ 130 SteMdule_I_Est 4095;
BA_ "GenSigStartValue" SG_ 130 SteMdule_I_Est 4095;
BA_ "U_CX727_MY2021_Rx" SG_ 130 SteMdule_I_Est 1;
BA_ "U_P702_MY2021_Rx" SG_ 130 SteMdule_I_Est 1;
BA_ "U_T6_MCA_MY2020_Rx" SG_ 130 SteMdule_I_Est 1;
BA_ "U_CD542_MY2021_Rx" SG_ 130 SteMdule_I_Est 1;
BA_ "U_U55X_MY2022_Rx" SG_ 130 SteMdule_I_Est 1;
BA_ "U_CD764_MY2022_Rx" SG_ 130 SteMdule_I_Est 1;
BA_ "GenSigStartValueInteger" SG_ 130 SteeringColumnTorque 254;
BA_ "GenSigStartValue" SG_ 130 SteeringColumnTorque 254;
BA_ "GenSigStartValueInteger" SG_ 1076 CenterStackRing_D_Actl 2;
BA_ "GenSigStartValue" SG_ 1076 CenterStackRing_D_Actl 2;
BA_ "GenSigSendType" SG_ 1076 CenterStackRing_D_Actl 3;
BA_ "GenSigSendType" SG_ 1076 EngIdlShutDown_B_RqDrv 3;
BA_ "GenSigSendType" SG_ 1076 OdoTripRx_B_Actl 3;
BA_ "GenSigSendType" SG_ 1076 LscmbbEngTqMn_B_Rq 3;
BA_ "U_CX727_MY2021_Rx" SG_ 1076 TirePReset_B_Rq_UB 1;
BA_ "U_P702_MY2021_Rx" SG_ 1076 TirePReset_B_Rq_UB 1;
BA_ "U_T6_MCA_MY2020_Rx" SG_ 1076 TirePReset_B_Rq_UB 1;
BA_ "U_CD542_MY2021_Rx" SG_ 1076 TirePReset_B_Rq_UB 1;
BA_ "U_U55X_MY2022_Rx" SG_ 1076 TirePReset_B_Rq_UB 1;
BA_ "U_CD764_MY2022_Rx" SG_ 1076 TirePReset_B_Rq_UB 1;
BA_ "WakeupSignal" SG_ 1076 DrTGate_D_Rq 1;
BA_ "GenSigSendType" SG_ 1076 DrTGate_D_Rq 3;
BA_ "U_CX727_MY2021_Rx" SG_ 1076 DrTGate_D_Rq 1;
BA_ "U_P702_MY2021_Rx" SG_ 1076 DrTGate_D_Rq 1;
BA_ "U_T6_MCA_MY2020_Rx" SG_ 1076 DrTGate_D_Rq 1;
BA_ "U_CD542_MY2021_Rx" SG_ 1076 DrTGate_D_Rq 1;
BA_ "U_U55X_MY2022_Rx" SG_ 1076 DrTGate_D_Rq 1;
BA_ "U_CD764_MY2022_Rx" SG_ 1076 DrTGate_D_Rq 1;
BA_ "U_CX727_MY2021_Rx" SG_ 1076 DrTGate_D_Rq_UB 1;
BA_ "U_P702_MY2021_Rx" SG_ 1076 DrTGate_D_Rq_UB 1;
BA_ "U_T6_MCA_MY2020_Rx" SG_ 1076 DrTGate_D_Rq_UB 1;
BA_ "U_CD542_MY2021_Rx" SG_ 1076 DrTGate_D_Rq_UB 1;
BA_ "U_U55X_MY2022_Rx" SG_ 1076 DrTGate_D_Rq_UB 1;
BA_ "U_CD764_MY2022_Rx" SG_ 1076 DrTGate_D_Rq_UB 1;
BA_ "GenSigStartValueInteger" SG_ 1076 Veh_V_CompLimMx 4095;
BA_ "GenSigStartValue" SG_ 1076 Veh_V_CompLimMx 4093;
BA_ "GenSigSendType" SG_ 1076 FUEL_SENSOR_NUM 3;
BA_ "GenSigSendType" SG_ 1076 TirePReset_B_Rq 3;
BA_ "U_CX727_MY2021_Rx" SG_ 1076 TirePReset_B_Rq 1;
BA_ "U_P702_MY2021_Rx" SG_ 1076 TirePReset_B_Rq 1;
BA_ "U_T6_MCA_MY2020_Rx" SG_ 1076 TirePReset_B_Rq 1;
BA_ "U_CD542_MY2021_Rx" SG_ 1076 TirePReset_B_Rq 1;
BA_ "U_U55X_MY2022_Rx" SG_ 1076 TirePReset_B_Rq 1;
BA_ "U_CD764_MY2022_Rx" SG_ 1076 TirePReset_B_Rq 1;
BA_ "U_CX727_MY2021_Rx" SG_ 1072 ePRNDL_MODE_UB 1;
BA_ "U_P702_MY2021_Rx" SG_ 1072 ePRNDL_MODE_UB 1;
BA_ "U_T6_MCA_MY2020_Rx" SG_ 1072 ePRNDL_MODE_UB 1;
BA_ "U_CD542_MY2021_Rx" SG_ 1072 ePRNDL_MODE_UB 1;
BA_ "U_U55X_MY2022_Rx" SG_ 1072 ePRNDL_MODE_UB 1;
BA_ "U_CD764_MY2022_Rx" SG_ 1072 ePRNDL_MODE_UB 1;
BA_ "GenSigSendType" SG_ 1072 NtrlTowMdeEnbl_B_RqDrv 3;
BA_ "U_CX727_MY2021_Rx" SG_ 1072 Remote_Start_QuietMode_UB 1;
BA_ "U_P702_MY2021_Rx" SG_ 1072 Remote_Start_QuietMode_UB 1;
BA_ "U_T6_MCA_MY2020_Rx" SG_ 1072 Remote_Start_QuietMode_UB 1;
BA_ "U_CD542_MY2021_Rx" SG_ 1072 Remote_Start_QuietMode_UB 1;
BA_ "U_U55X_MY2022_Rx" SG_ 1072 Remote_Start_QuietMode_UB 1;
BA_ "U_CD764_MY2022_Rx" SG_ 1072 Remote_Start_QuietMode_UB 1;
BA_ "GenSigSendType" SG_ 1072 Remote_Start_QuietMode 3;
BA_ "U_CX727_MY2021_Rx" SG_ 1072 Remote_Start_QuietMode 1;
BA_ "U_P702_MY2021_Rx" SG_ 1072 Remote_Start_QuietMode 1;
BA_ "U_T6_MCA_MY2020_Rx" SG_ 1072 Remote_Start_QuietMode 1;
BA_ "U_CD542_MY2021_Rx" SG_ 1072 Remote_Start_QuietMode 1;
BA_ "U_U55X_MY2022_Rx" SG_ 1072 Remote_Start_QuietMode 1;
BA_ "U_CD764_MY2022_Rx" SG_ 1072 Remote_Start_QuietMode 1;
BA_ "U_CX727_MY2021_Rx" SG_ 1072 ParkDetect_Stat_UB 1;
BA_ "U_P702_MY2021_Rx" SG_ 1072 ParkDetect_Stat_UB 1;
BA_ "U_T6_MCA_MY2020_Rx" SG_ 1072 ParkDetect_Stat_UB 1;
BA_ "U_CD542_MY2021_Rx" SG_ 1072 ParkDetect_Stat_UB 1;
BA_ "U_U55X_MY2022_Rx" SG_ 1072 ParkDetect_Stat_UB 1;
BA_ "U_CD764_MY2022_Rx" SG_ 1072 ParkDetect_Stat_UB 1;
BA_ "GenSigSendType" SG_ 1072 ParkDetect_Stat 3;
BA_ "U_CX727_MY2021_Rx" SG_ 1072 ParkDetect_Stat 1;
BA_ "U_P702_MY2021_Rx" SG_ 1072 ParkDetect_Stat 1;
BA_ "U_T6_MCA_MY2020_Rx" SG_ 1072 ParkDetect_Stat 1;
BA_ "U_CD542_MY2021_Rx" SG_ 1072 ParkDetect_Stat 1;
BA_ "U_U55X_MY2022_Rx" SG_ 1072 ParkDetect_Stat 1;
BA_ "U_CD764_MY2022_Rx" SG_ 1072 ParkDetect_Stat 1;
BA_ "U_CX727_MY2021_Rx" SG_ 1072 TrlrLampCnnct_B_Actl_UB 1;
BA_ "U_P702_MY2021_Rx" SG_ 1072 TrlrLampCnnct_B_Actl_UB 1;
BA_ "U_T6_MCA_MY2020_Rx" SG_ 1072 TrlrLampCnnct_B_Actl_UB 1;
BA_ "U_CD542_MY2021_Rx" SG_ 1072 TrlrLampCnnct_B_Actl_UB 1;
BA_ "U_U55X_MY2022_Rx" SG_ 1072 TrlrLampCnnct_B_Actl_UB 1;
BA_ "U_CD764_MY2022_Rx" SG_ 1072 TrlrLampCnnct_B_Actl_UB 1;
BA_ "U_CX727_MY2021_Rx" SG_ 1072 StopLamp_B_RqTrlrBrk_UB 1;
BA_ "U_P702_MY2021_Rx" SG_ 1072 StopLamp_B_RqTrlrBrk_UB 1;
BA_ "U_T6_MCA_MY2020_Rx" SG_ 1072 StopLamp_B_RqTrlrBrk_UB 1;
BA_ "U_CD542_MY2021_Rx" SG_ 1072 StopLamp_B_RqTrlrBrk_UB 1;
BA_ "U_U55X_MY2022_Rx" SG_ 1072 StopLamp_B_RqTrlrBrk_UB 1;
BA_ "U_CD764_MY2022_Rx" SG_ 1072 StopLamp_B_RqTrlrBrk_UB 1;
BA_ "ContentDependant" SG_ 1072 StopLamp_B_RqTrlrBrk 1;
BA_ "GenSigSendType" SG_ 1072 StopLamp_B_RqTrlrBrk 3;
BA_ "U_CX727_MY2021_Rx" SG_ 1072 StopLamp_B_RqTrlrBrk 1;
BA_ "U_P702_MY2021_Rx" SG_ 1072 StopLamp_B_RqTrlrBrk 1;
BA_ "U_T6_MCA_MY2020_Rx" SG_ 1072 StopLamp_B_RqTrlrBrk 1;
BA_ "U_CD542_MY2021_Rx" SG_ 1072 StopLamp_B_RqTrlrBrk 1;
BA_ "U_U55X_MY2022_Rx" SG_ 1072 StopLamp_B_RqTrlrBrk 1;
BA_ "U_CD764_MY2022_Rx" SG_ 1072 StopLamp_B_RqTrlrBrk 1;
BA_ "U_CX727_MY2021_Rx" SG_ 1072 OdometerMasterValue_UB 1;
BA_ "U_P702_MY2021_Rx" SG_ 1072 OdometerMasterValue_UB 1;
BA_ "U_T6_MCA_MY2020_Rx" SG_ 1072 OdometerMasterValue_UB 1;
BA_ "U_CD542_MY2021_Rx" SG_ 1072 OdometerMasterValue_UB 1;
BA_ "U_U55X_MY2022_Rx" SG_ 1072 OdometerMasterValue_UB 1;
BA_ "U_CD764_MY2022_Rx" SG_ 1072 OdometerMasterValue_UB 1;
BA_ "GenSigSendType" SG_ 1072 OdometerMasterValue 3;
BA_ "U_CX727_MY2021_Rx" SG_ 1072 OdometerMasterValue 1;
BA_ "U_P702_MY2021_Rx" SG_ 1072 OdometerMasterValue 1;
BA_ "U_T6_MCA_MY2020_Rx" SG_ 1072 OdometerMasterValue 1;
BA_ "U_CD542_MY2021_Rx" SG_ 1072 OdometerMasterValue 1;
BA_ "U_U55X_MY2022_Rx" SG_ 1072 OdometerMasterValue 1;
BA_ "U_CD764_MY2022_Rx" SG_ 1072 OdometerMasterValue 1;
BA_ "GenSigSendType" SG_ 1072 FrostWarn_D_Stat 3;
BA_ "U_CX727_MY2021_Rx" SG_ 1072 ReducedGuard_D_Rq_UB 1;
BA_ "U_P702_MY2021_Rx" SG_ 1072 ReducedGuard_D_Rq_UB 1;
BA_ "U_T6_MCA_MY2020_Rx" SG_ 1072 ReducedGuard_D_Rq_UB 1;
BA_ "U_CD542_MY2021_Rx" SG_ 1072 ReducedGuard_D_Rq_UB 1;
BA_ "U_U55X_MY2022_Rx" SG_ 1072 ReducedGuard_D_Rq_UB 1;
BA_ "U_CD764_MY2022_Rx" SG_ 1072 ReducedGuard_D_Rq_UB 1;
BA_ "GenSigSendType" SG_ 1072 ReducedGuard_D_Rq 3;
BA_ "U_CX727_MY2021_Rx" SG_ 1072 ReducedGuard_D_Rq 1;
BA_ "U_P702_MY2021_Rx" SG_ 1072 ReducedGuard_D_Rq 1;
BA_ "U_T6_MCA_MY2020_Rx" SG_ 1072 ReducedGuard_D_Rq 1;
BA_ "U_CD542_MY2021_Rx" SG_ 1072 ReducedGuard_D_Rq 1;
BA_ "U_U55X_MY2022_Rx" SG_ 1072 ReducedGuard_D_Rq 1;
BA_ "U_CD764_MY2022_Rx" SG_ 1072 ReducedGuard_D_Rq 1;
BA_ "WakeupSignal" SG_ 1072 ePRNDL_MODE 1;
BA_ "GenSigSendType" SG_ 1072 ePRNDL_MODE 3;
BA_ "U_CX727_MY2021_Rx" SG_ 1072 ePRNDL_MODE 1;
BA_ "U_P702_MY2021_Rx" SG_ 1072 ePRNDL_MODE 1;
BA_ "U_T6_MCA_MY2020_Rx" SG_ 1072 ePRNDL_MODE 1;
BA_ "U_CD542_MY2021_Rx" SG_ 1072 ePRNDL_MODE 1;
BA_ "U_U55X_MY2022_Rx" SG_ 1072 ePRNDL_MODE 1;
BA_ "U_CD764_MY2022_Rx" SG_ 1072 ePRNDL_MODE 1;
BA_ "GenSigSendType" SG_ 1072 EngOilLife_B_RqReset 3;
BA_ "U_U55X_MY2022_Rx" SG_ 1072 Outside_Air_Temp_Stat_UB 1;
BA_ "GenSigStartValueInteger" SG_ 1072 Outside_Air_Temp_Stat 254;
BA_ "GenSigStartValue" SG_ 1072 Outside_Air_Temp_Stat 254;
BA_ "GenSigSendType" SG_ 1072 Outside_Air_Temp_Stat 3;
BA_ "U_U55X_MY2022_Rx" SG_ 1072 Outside_Air_Temp_Stat 1;
BA_ "U_CX727_MY2021_Rx" SG_ 1072 KeyTypeChngMykey_D_Rq_UB 1;
BA_ "U_P702_MY2021_Rx" SG_ 1072 KeyTypeChngMykey_D_Rq_UB 1;
BA_ "U_T6_MCA_MY2020_Rx" SG_ 1072 KeyTypeChngMykey_D_Rq_UB 1;
BA_ "U_CD542_MY2021_Rx" SG_ 1072 KeyTypeChngMykey_D_Rq_UB 1;
BA_ "U_U55X_MY2022_Rx" SG_ 1072 KeyTypeChngMykey_D_Rq_UB 1;
BA_ "U_CD764_MY2022_Rx" SG_ 1072 KeyTypeChngMykey_D_Rq_UB 1;
BA_ "GenSigSendType" SG_ 1072 KeyTypeChngMykey_D_Rq 3;
BA_ "U_CX727_MY2021_Rx" SG_ 1072 KeyTypeChngMykey_D_Rq 1;
BA_ "U_P702_MY2021_Rx" SG_ 1072 KeyTypeChngMykey_D_Rq 1;
BA_ "U_T6_MCA_MY2020_Rx" SG_ 1072 KeyTypeChngMykey_D_Rq 1;
BA_ "U_CD542_MY2021_Rx" SG_ 1072 KeyTypeChngMykey_D_Rq 1;
BA_ "U_U55X_MY2022_Rx" SG_ 1072 KeyTypeChngMykey_D_Rq 1;
BA_ "U_CD764_MY2022_Rx" SG_ 1072 KeyTypeChngMykey_D_Rq 1;
BA_ "GenSigSendType" SG_ 1072 TrlrLampCnnct_B_Actl 3;
BA_ "U_CX727_MY2021_Rx" SG_ 1072 TrlrLampCnnct_B_Actl 1;
BA_ "U_P702_MY2021_Rx" SG_ 1072 TrlrLampCnnct_B_Actl 1;
BA_ "U_T6_MCA_MY2020_Rx" SG_ 1072 TrlrLampCnnct_B_Actl 1;
BA_ "U_CD542_MY2021_Rx" SG_ 1072 TrlrLampCnnct_B_Actl 1;
BA_ "U_U55X_MY2022_Rx" SG_ 1072 TrlrLampCnnct_B_Actl 1;
BA_ "U_CD764_MY2022_Rx" SG_ 1072 TrlrLampCnnct_B_Actl 1;
BA_ "GenSigStartValueInteger" SG_ 1438 GWM_GWOnBoardTester 255;
BA_ "ContentDependant" SG_ 1438 GWM_GWOnBoardTester 1;
BA_ "GenSigStartValue" SG_ 1438 GWM_GWOnBoardTester 255;
BA_ "U_CX727_MY2021_Rx" SG_ 1438 GWM_GWOnBoardTester 1;
BA_ "U_P702_MY2021_Rx" SG_ 1438 GWM_GWOnBoardTester 1;
BA_ "U_T6_MCA_MY2020_Rx" SG_ 1438 GWM_GWOnBoardTester 1;
BA_ "U_CD542_MY2021_Rx" SG_ 1438 GWM_GWOnBoardTester 1;
BA_ "U_U55X_MY2022_Rx" SG_ 1438 GWM_GWOnBoardTester 1;
BA_ "U_CD764_MY2022_Rx" SG_ 1438 GWM_GWOnBoardTester 1;
BA_ "U_T6_MCA_MY2020_Tx" SG_ 1438 GWM_GWOnBoardTester 1;
BA_ "ECGUsedTxSignal" SG_ 1438 GWM_GWOnBoardTester 1;
BA_ "U_CD542_MY2021_Tx" SG_ 1438 GWM_GWOnBoardTester 1;
BA_ "U_U55X_MY2022_Tx" SG_ 1438 GWM_GWOnBoardTester 1;
BA_ "U_CD764_MY2022_Tx" SG_ 1438 GWM_GWOnBoardTester 1;
BA_ "GenSigStartValueInteger" SG_ 1438 GWM_GWNMProxy 255;
BA_ "ContentDependant" SG_ 1438 GWM_GWNMProxy 1;
BA_ "GenSigStartValue" SG_ 1438 GWM_GWNMProxy 255;
BA_ "U_CX727_MY2021_Rx" SG_ 1438 GWM_GWNMProxy 1;
BA_ "U_P702_MY2021_Rx" SG_ 1438 GWM_GWNMProxy 1;
BA_ "U_T6_MCA_MY2020_Rx" SG_ 1438 GWM_GWNMProxy 1;
BA_ "U_CD542_MY2021_Rx" SG_ 1438 GWM_GWNMProxy 1;
BA_ "U_U55X_MY2022_Rx" SG_ 1438 GWM_GWNMProxy 1;
BA_ "U_CD764_MY2022_Rx" SG_ 1438 GWM_GWNMProxy 1;
BA_ "U_T6_MCA_MY2020_Tx" SG_ 1438 GWM_GWNMProxy 1;
BA_ "ECGUsedTxSignal" SG_ 1438 GWM_GWNMProxy 1;
BA_ "U_CD542_MY2021_Tx" SG_ 1438 GWM_GWNMProxy 1;
BA_ "U_U55X_MY2022_Tx" SG_ 1438 GWM_GWNMProxy 1;
BA_ "U_CD764_MY2022_Tx" SG_ 1438 GWM_GWNMProxy 1;
BA_ "GenSigStartValueInteger" SG_ 1438 GWM_AutoSarNMReserved4 255;
BA_ "ContentDependant" SG_ 1438 GWM_AutoSarNMReserved4 1;
BA_ "GenSigStartValue" SG_ 1438 GWM_AutoSarNMReserved4 255;
BA_ "U_CX727_MY2021_Rx" SG_ 1438 GWM_AutoSarNMReserved4 1;
BA_ "U_P702_MY2021_Rx" SG_ 1438 GWM_AutoSarNMReserved4 1;
BA_ "U_T6_MCA_MY2020_Rx" SG_ 1438 GWM_AutoSarNMReserved4 1;
BA_ "U_CD542_MY2021_Rx" SG_ 1438 GWM_AutoSarNMReserved4 1;
BA_ "U_U55X_MY2022_Rx" SG_ 1438 GWM_AutoSarNMReserved4 1;
BA_ "U_CD764_MY2022_Rx" SG_ 1438 GWM_AutoSarNMReserved4 1;
BA_ "U_T6_MCA_MY2020_Tx" SG_ 1438 GWM_AutoSarNMReserved4 1;
BA_ "ECGUsedTxSignal" SG_ 1438 GWM_AutoSarNMReserved4 1;
BA_ "U_CD542_MY2021_Tx" SG_ 1438 GWM_AutoSarNMReserved4 1;
BA_ "U_U55X_MY2022_Tx" SG_ 1438 GWM_AutoSarNMReserved4 1;
BA_ "U_CD764_MY2022_Tx" SG_ 1438 GWM_AutoSarNMReserved4 1;
BA_ "GenSigStartValueInteger" SG_ 1438 GWM_AutoSarNMReserved3 255;
BA_ "ContentDependant" SG_ 1438 GWM_AutoSarNMReserved3 1;
BA_ "GenSigStartValue" SG_ 1438 GWM_AutoSarNMReserved3 255;
BA_ "U_CX727_MY2021_Rx" SG_ 1438 GWM_AutoSarNMReserved3 1;
BA_ "U_P702_MY2021_Rx" SG_ 1438 GWM_AutoSarNMReserved3 1;
BA_ "U_T6_MCA_MY2020_Rx" SG_ 1438 GWM_AutoSarNMReserved3 1;
BA_ "U_CD542_MY2021_Rx" SG_ 1438 GWM_AutoSarNMReserved3 1;
BA_ "U_U55X_MY2022_Rx" SG_ 1438 GWM_AutoSarNMReserved3 1;
BA_ "U_CD764_MY2022_Rx" SG_ 1438 GWM_AutoSarNMReserved3 1;
BA_ "U_T6_MCA_MY2020_Tx" SG_ 1438 GWM_AutoSarNMReserved3 1;
BA_ "ECGUsedTxSignal" SG_ 1438 GWM_AutoSarNMReserved3 1;
BA_ "U_CD542_MY2021_Tx" SG_ 1438 GWM_AutoSarNMReserved3 1;
BA_ "U_U55X_MY2022_Tx" SG_ 1438 GWM_AutoSarNMReserved3 1;
BA_ "U_CD764_MY2022_Tx" SG_ 1438 GWM_AutoSarNMReserved3 1;
BA_ "GenSigStartValueInteger" SG_ 1438 GWM_AutoSarNMReserved2 255;
BA_ "ContentDependant" SG_ 1438 GWM_AutoSarNMReserved2 1;
BA_ "GenSigStartValue" SG_ 1438 GWM_AutoSarNMReserved2 255;
BA_ "U_CX727_MY2021_Rx" SG_ 1438 GWM_AutoSarNMReserved2 1;
BA_ "U_P702_MY2021_Rx" SG_ 1438 GWM_AutoSarNMReserved2 1;
BA_ "U_T6_MCA_MY2020_Rx" SG_ 1438 GWM_AutoSarNMReserved2 1;
BA_ "U_CD542_MY2021_Rx" SG_ 1438 GWM_AutoSarNMReserved2 1;
BA_ "U_U55X_MY2022_Rx" SG_ 1438 GWM_AutoSarNMReserved2 1;
BA_ "U_CD764_MY2022_Rx" SG_ 1438 GWM_AutoSarNMReserved2 1;
BA_ "U_T6_MCA_MY2020_Tx" SG_ 1438 GWM_AutoSarNMReserved2 1;
BA_ "ECGUsedTxSignal" SG_ 1438 GWM_AutoSarNMReserved2 1;
BA_ "U_CD542_MY2021_Tx" SG_ 1438 GWM_AutoSarNMReserved2 1;
BA_ "U_U55X_MY2022_Tx" SG_ 1438 GWM_AutoSarNMReserved2 1;
BA_ "U_CD764_MY2022_Tx" SG_ 1438 GWM_AutoSarNMReserved2 1;
BA_ "GenSigStartValueInteger" SG_ 1438 GWM_AutoSarNMReserved1 255;
BA_ "ContentDependant" SG_ 1438 GWM_AutoSarNMReserved1 1;
BA_ "GenSigStartValue" SG_ 1438 GWM_AutoSarNMReserved1 255;
BA_ "U_CX727_MY2021_Rx" SG_ 1438 GWM_AutoSarNMReserved1 1;
BA_ "U_P702_MY2021_Rx" SG_ 1438 GWM_AutoSarNMReserved1 1;
BA_ "U_T6_MCA_MY2020_Rx" SG_ 1438 GWM_AutoSarNMReserved1 1;
BA_ "U_CD542_MY2021_Rx" SG_ 1438 GWM_AutoSarNMReserved1 1;
BA_ "U_U55X_MY2022_Rx" SG_ 1438 GWM_AutoSarNMReserved1 1;
BA_ "U_CD764_MY2022_Rx" SG_ 1438 GWM_AutoSarNMReserved1 1;
BA_ "U_T6_MCA_MY2020_Tx" SG_ 1438 GWM_AutoSarNMReserved1 1;
BA_ "ECGUsedTxSignal" SG_ 1438 GWM_AutoSarNMReserved1 1;
BA_ "U_CD542_MY2021_Tx" SG_ 1438 GWM_AutoSarNMReserved1 1;
BA_ "U_U55X_MY2022_Tx" SG_ 1438 GWM_AutoSarNMReserved1 1;
BA_ "U_CD764_MY2022_Tx" SG_ 1438 GWM_AutoSarNMReserved1 1;
BA_ "GenSigStartValueInteger" SG_ 1438 GWM_AutoSarNMNodeId 158;
BA_ "ContentDependant" SG_ 1438 GWM_AutoSarNMNodeId 1;
BA_ "GenSigStartValue" SG_ 1438 GWM_AutoSarNMNodeId 158;
BA_ "U_CX727_MY2021_Rx" SG_ 1438 GWM_AutoSarNMNodeId 1;
BA_ "U_P702_MY2021_Rx" SG_ 1438 GWM_AutoSarNMNodeId 1;
BA_ "U_T6_MCA_MY2020_Rx" SG_ 1438 GWM_AutoSarNMNodeId 1;
BA_ "U_CD542_MY2021_Rx" SG_ 1438 GWM_AutoSarNMNodeId 1;
BA_ "U_U55X_MY2022_Rx" SG_ 1438 GWM_AutoSarNMNodeId 1;
BA_ "U_CD764_MY2022_Rx" SG_ 1438 GWM_AutoSarNMNodeId 1;
BA_ "U_T6_MCA_MY2020_Tx" SG_ 1438 GWM_AutoSarNMNodeId 1;
BA_ "ECGUsedTxSignal" SG_ 1438 GWM_AutoSarNMNodeId 1;
BA_ "U_CD542_MY2021_Tx" SG_ 1438 GWM_AutoSarNMNodeId 1;
BA_ "U_U55X_MY2022_Tx" SG_ 1438 GWM_AutoSarNMNodeId 1;
BA_ "U_CD764_MY2022_Tx" SG_ 1438 GWM_AutoSarNMNodeId 1;
BA_ "ContentDependant" SG_ 1438 GWM_AutoSarNMControl 1;
BA_ "U_CX727_MY2021_Rx" SG_ 1438 GWM_AutoSarNMControl 1;
BA_ "U_P702_MY2021_Rx" SG_ 1438 GWM_AutoSarNMControl 1;
BA_ "U_T6_MCA_MY2020_Rx" SG_ 1438 GWM_AutoSarNMControl 1;
BA_ "U_CD542_MY2021_Rx" SG_ 1438 GWM_AutoSarNMControl 1;
BA_ "U_U55X_MY2022_Rx" SG_ 1438 GWM_AutoSarNMControl 1;
BA_ "U_CD764_MY2022_Rx" SG_ 1438 GWM_AutoSarNMControl 1;
BA_ "U_T6_MCA_MY2020_Tx" SG_ 1438 GWM_AutoSarNMControl 1;
BA_ "ECGUsedTxSignal" SG_ 1438 GWM_AutoSarNMControl 1;
BA_ "U_CD542_MY2021_Tx" SG_ 1438 GWM_AutoSarNMControl 1;
BA_ "U_U55X_MY2022_Tx" SG_ 1438 GWM_AutoSarNMControl 1;
BA_ "U_CD764_MY2022_Tx" SG_ 1438 GWM_AutoSarNMControl 1;
BA_ "GenSigStartValueInteger" SG_ 1067 BattULoAuxSoc_Pc_Actl 95;
BA_ "GenSigStartValue" SG_ 1067 BattULoAuxSoc_Pc_Actl 95;
BA_ "U_CX727_MY2021_Tx" SG_ 1067 BattULoAuxSoc_Pc_Actl 1;
BA_ "U_P702_MY2021_Tx" SG_ 1067 BattULoAuxSoc_Pc_Actl 1;
BA_ "U_T6_MCA_MY2020_Tx" SG_ 1067 BattULoAuxSoc_Pc_Actl 1;
BA_ "U_U55X_MY2022_Tx" SG_ 1067 BattULoAuxSoc_Pc_Actl 1;
BA_ "U_CD764_MY2022_Tx" SG_ 1067 BattULoAuxSoc_Pc_Actl 1;
BA_ "GenSigStartValueInteger" SG_ 1067 BattULoAux_I_Actl 2048;
BA_ "U_CX727_MY2021_Tx" SG_ 1067 BattULoAux_I_Actl 1;
BA_ "U_P702_MY2021_Tx" SG_ 1067 BattULoAux_I_Actl 1;
BA_ "U_T6_MCA_MY2020_Tx" SG_ 1067 BattULoAux_I_Actl 1;
BA_ "U_U55X_MY2022_Tx" SG_ 1067 BattULoAux_I_Actl 1;
BA_ "U_CD764_MY2022_Tx" SG_ 1067 BattULoAux_I_Actl 1;
BA_ "U_CX727_MY2021_Tx" SG_ 1067 BattULoAux_D_Qlty 1;
BA_ "U_P702_MY2021_Tx" SG_ 1067 BattULoAux_D_Qlty 1;
BA_ "U_T6_MCA_MY2020_Tx" SG_ 1067 BattULoAux_D_Qlty 1;
BA_ "U_U55X_MY2022_Tx" SG_ 1067 BattULoAux_D_Qlty 1;
BA_ "U_CD764_MY2022_Tx" SG_ 1067 BattULoAux_D_Qlty 1;
BA_ "U_CX727_MY2021_Tx" SG_ 1067 BattULoCrnkStrt_U_Pred 1;
BA_ "U_P702_MY2021_Tx" SG_ 1067 BattULoCrnkStrt_U_Pred 1;
BA_ "U_T6_MCA_MY2020_Tx" SG_ 1067 BattULoCrnkStrt_U_Pred 1;
BA_ "U_U55X_MY2022_Tx" SG_ 1067 BattULoCrnkStrt_U_Pred 1;
BA_ "U_CD764_MY2022_Tx" SG_ 1067 BattULoCrnkStrt_U_Pred 1;
BA_ "U_CX727_MY2021_Tx" SG_ 1067 BattULoCrnkBelt_U_Pred 1;
BA_ "U_P702_MY2021_Tx" SG_ 1067 BattULoCrnkBelt_U_Pred 1;
BA_ "U_T6_MCA_MY2020_Tx" SG_ 1067 BattULoCrnkBelt_U_Pred 1;
BA_ "U_U55X_MY2022_Tx" SG_ 1067 BattULoCrnkBelt_U_Pred 1;
BA_ "U_CD764_MY2022_Tx" SG_ 1067 BattULoCrnkBelt_U_Pred 1;
BA_ "GenSigStartValueInteger" SG_ 1067 BattULoAux_U_Actl 203;
BA_ "GenSigStartValue" SG_ 1067 BattULoAux_U_Actl 203;
BA_ "U_CX727_MY2021_Tx" SG_ 1067 BattULoAux_U_Actl 1;
BA_ "U_P702_MY2021_Tx" SG_ 1067 BattULoAux_U_Actl 1;
BA_ "U_T6_MCA_MY2020_Tx" SG_ 1067 BattULoAux_U_Actl 1;
BA_ "U_U55X_MY2022_Tx" SG_ 1067 BattULoAux_U_Actl 1;
BA_ "U_CD764_MY2022_Tx" SG_ 1067 BattULoAux_U_Actl 1;
BA_ "U_CX727_MY2021_Tx" SG_ 1067 BattULoAux_B_Falt 1;
BA_ "U_P702_MY2021_Tx" SG_ 1067 BattULoAux_B_Falt 1;
BA_ "U_T6_MCA_MY2020_Tx" SG_ 1067 BattULoAux_B_Falt 1;
BA_ "U_U55X_MY2022_Tx" SG_ 1067 BattULoAux_B_Falt 1;
BA_ "U_CD764_MY2022_Tx" SG_ 1067 BattULoAux_B_Falt 1;
BA_ "GenSigStartValueInteger" SG_ 588 BattTracSoc_Pc_Dsply 254;
BA_ "GenSigStartValue" SG_ 588 BattTracSoc_Pc_Dsply 254;
BA_ "U_CX727_MY2021_Rx" SG_ 588 BattTracSoc_Pc_Dsply 1;
BA_ "U_CD542_MY2021_Rx" SG_ 588 BattTracSoc_Pc_Dsply 1;
BA_ "ECGUsedRxSignal" SG_ 588 BattTracSoc_Pc_Dsply 1;
BA_ "U_U55X_MY2022_Rx" SG_ 588 BattTracSoc_Pc_Dsply 1;
BA_ "U_CX727_MY2021_Tx" SG_ 588 BattTracSoc_Pc_Dsply 1;
BA_ "U_CD542_MY2021_Tx" SG_ 588 BattTracSoc_Pc_Dsply 1;
BA_ "U_CX727_MY2021_Rx" SG_ 588 BattChrgRdyStat_D_Actl 1;
BA_ "U_CD542_MY2021_Rx" SG_ 588 BattChrgRdyStat_D_Actl 1;
BA_ "U_CX727_MY2021_Tx" SG_ 588 BattChrgRdyStat_D_Actl 1;
BA_ "U_CD542_MY2021_Tx" SG_ 588 BattChrgRdyStat_D_Actl 1;
BA_ "GenSigStartValueInteger" SG_ 588 BattTracSoc2_Pc_Actl 16382;
BA_ "GenSigStartValue" SG_ 588 BattTracSoc2_Pc_Actl 16382;
BA_ "ECGUsedRxSignal" SG_ 588 BattTracSoc2_Pc_Actl 1;
BA_ "U_CD542_MY2021_Rx" SG_ 588 BattTracSoc2_Pc_Actl 1;
BA_ "U_U55X_MY2022_Rx" SG_ 588 BattTracSoc2_Pc_Actl 1;
BA_ "U_CX727_MY2021_Tx" SG_ 588 BattTracSoc2_Pc_Actl 1;
BA_ "U_P702_MY2021_Tx" SG_ 588 BattTracSoc2_Pc_Actl 1;
BA_ "U_CD542_MY2021_Tx" SG_ 588 BattTracSoc2_Pc_Actl 1;
BA_ "GenSigStartValueInteger" SG_ 588 BattTrac_Te_Actl 150;
BA_ "GenSigStartValue" SG_ 588 BattTrac_Te_Actl 150;
BA_ "ECGUsedRxSignal" SG_ 588 BattTrac_Te_Actl 1;
BA_ "U_CD542_MY2021_Rx" SG_ 588 BattTrac_Te_Actl 1;
BA_ "U_U55X_MY2022_Rx" SG_ 588 BattTrac_Te_Actl 1;
BA_ "U_CX727_MY2021_Tx" SG_ 588 BattTrac_Te_Actl 1;
BA_ "U_P702_MY2021_Tx" SG_ 588 BattTrac_Te_Actl 1;
BA_ "U_CD542_MY2021_Tx" SG_ 588 BattTrac_Te_Actl 1;
BA_ "GenSigStartValueInteger" SG_ 122 BattTrac_U_LimLo 88;
BA_ "GenSigStartValue" SG_ 122 BattTrac_U_LimLo 88;
BA_ "U_CX727_MY2021_Rx" SG_ 122 BattTrac_U_LimLo 1;
BA_ "U_CX727_MY2021_Tx" SG_ 122 BattTrac_U_LimLo 1;
BA_ "U_P702_MY2021_Tx" SG_ 122 BattTrac_U_LimLo 1;
BA_ "U_CD542_MY2021_Tx" SG_ 122 BattTrac_U_LimLo 1;
BA_ "GenSigStartValueInteger" SG_ 122 BattTrac_U_LimHi 163;
BA_ "GenSigStartValue" SG_ 122 BattTrac_U_LimHi 163;
BA_ "U_CX727_MY2021_Rx" SG_ 122 BattTrac_U_LimHi 1;
BA_ "U_CX727_MY2021_Tx" SG_ 122 BattTrac_U_LimHi 1;
BA_ "U_P702_MY2021_Tx" SG_ 122 BattTrac_U_LimHi 1;
BA_ "U_CD542_MY2021_Tx" SG_ 122 BattTrac_U_LimHi 1;
BA_ "U_CX727_MY2021_Tx" SG_ 122 VehStrtInhbt_B_RqBatt 1;
BA_ "U_P702_MY2021_Tx" SG_ 122 VehStrtInhbt_B_RqBatt 1;
BA_ "U_CD542_MY2021_Tx" SG_ 122 VehStrtInhbt_B_RqBatt 1;
BA_ "U_CX727_MY2021_Rx" SG_ 122 BattTracOffFst_D_Actl 1;
BA_ "U_P702_MY2021_Rx" SG_ 122 BattTracOffFst_D_Actl 1;
BA_ "U_CD542_MY2021_Rx" SG_ 122 BattTracOffFst_D_Actl 1;
BA_ "U_CX727_MY2021_Tx" SG_ 122 BattTracOffFst_D_Actl 1;
BA_ "U_P702_MY2021_Tx" SG_ 122 BattTracOffFst_D_Actl 1;
BA_ "U_CD542_MY2021_Tx" SG_ 122 BattTracOffFst_D_Actl 1;
BA_ "U_CX727_MY2021_Rx" SG_ 122 BattTracOff_B_Actl 1;
BA_ "U_CD542_MY2021_Rx" SG_ 122 BattTracOff_B_Actl 1;
BA_ "ECGUsedRxSignal" SG_ 122 BattTracOff_B_Actl 1;
BA_ "U_U55X_MY2022_Rx" SG_ 122 BattTracOff_B_Actl 1;
BA_ "U_CX727_MY2021_Tx" SG_ 122 BattTracOff_B_Actl 1;
BA_ "U_P702_MY2021_Tx" SG_ 122 BattTracOff_B_Actl 1;
BA_ "U_CD542_MY2021_Tx" SG_ 122 BattTracOff_B_Actl 1;
BA_ "ECGUsedRxSignal" SG_ 122 BattTracMil_D_Rq 1;
BA_ "U_CD542_MY2021_Rx" SG_ 122 BattTracMil_D_Rq 1;
BA_ "U_U55X_MY2022_Rx" SG_ 122 BattTracMil_D_Rq 1;
BA_ "U_CX727_MY2021_Tx" SG_ 122 BattTracMil_D_Rq 1;
BA_ "U_P702_MY2021_Tx" SG_ 122 BattTracMil_D_Rq 1;
BA_ "U_CD542_MY2021_Tx" SG_ 122 BattTracMil_D_Rq 1;
BA_ "GenSigStartValueInteger" SG_ 122 BattTrac_U_Actl 1022;
BA_ "GenSigStartValue" SG_ 122 BattTrac_U_Actl 1022;
BA_ "U_CX727_MY2021_Rx" SG_ 122 BattTrac_U_Actl 1;
BA_ "U_P702_MY2021_Rx" SG_ 122 BattTrac_U_Actl 1;
BA_ "U_CD542_MY2021_Rx" SG_ 122 BattTrac_U_Actl 1;
BA_ "ECGUsedRxSignal" SG_ 122 BattTrac_U_Actl 1;
BA_ "U_U55X_MY2022_Rx" SG_ 122 BattTrac_U_Actl 1;
BA_ "U_CX727_MY2021_Tx" SG_ 122 BattTrac_U_Actl 1;
BA_ "U_P702_MY2021_Tx" SG_ 122 BattTrac_U_Actl 1;
BA_ "U_CD542_MY2021_Tx" SG_ 122 BattTrac_U_Actl 1;
BA_ "GenSigStartValueInteger" SG_ 122 BattTrac_I_Actl 15000;
BA_ "U_CX727_MY2021_Rx" SG_ 122 BattTrac_I_Actl 1;
BA_ "U_CD542_MY2021_Rx" SG_ 122 BattTrac_I_Actl 1;
BA_ "ECGUsedRxSignal" SG_ 122 BattTrac_I_Actl 1;
BA_ "U_U55X_MY2022_Rx" SG_ 122 BattTrac_I_Actl 1;
BA_ "U_CX727_MY2021_Tx" SG_ 122 BattTrac_I_Actl 1;
BA_ "U_P702_MY2021_Tx" SG_ 122 BattTrac_I_Actl 1;
BA_ "U_CD542_MY2021_Tx" SG_ 122 BattTrac_I_Actl 1;
BA_ "GenSigSendType" SG_ 1814 TesterPhysicalReqGWM_H1 3;
BA_ "U_T6_MCA_MY2020_Rx" SG_ 1814 TesterPhysicalReqGWM_H1 1;
BA_ "ECGUsedRxSignal" SG_ 1814 TesterPhysicalReqGWM_H1 1;
BA_ "U_CD542_MY2021_Rx" SG_ 1814 TesterPhysicalReqGWM_H1 1;
BA_ "U_U55X_MY2022_Rx" SG_ 1814 TesterPhysicalReqGWM_H1 1;
BA_ "U_CD764_MY2022_Rx" SG_ 1814 TesterPhysicalReqGWM_H1 1;
BA_ "GenSigSendType" SG_ 1822 TesterPhysicalResGWM_H1 3;
BA_ "U_T6_MCA_MY2020_Tx" SG_ 1822 TesterPhysicalResGWM_H1 1;
BA_ "ECGUsedTxSignal" SG_ 1822 TesterPhysicalResGWM_H1 1;
BA_ "U_CD542_MY2021_Tx" SG_ 1822 TesterPhysicalResGWM_H1 1;
BA_ "U_U55X_MY2022_Tx" SG_ 1822 TesterPhysicalResGWM_H1 1;
BA_ "U_CD764_MY2022_Tx" SG_ 1822 TesterPhysicalResGWM_H1 1;
BA_ "U_CX727_MY2021_Rx" SG_ 806 SnowPlowMde_B_Enbl 1;
BA_ "U_P702_MY2021_Rx" SG_ 806 SnowPlowMde_B_Enbl 1;
BA_ "U_T6_MCA_MY2020_Rx" SG_ 806 SnowPlowMde_B_Enbl 1;
BA_ "U_CD542_MY2021_Rx" SG_ 806 SnowPlowMde_B_Enbl 1;
BA_ "U_U55X_MY2022_Rx" SG_ 806 SnowPlowMde_B_Enbl 1;
BA_ "U_CD764_MY2022_Rx" SG_ 806 SnowPlowMde_B_Enbl 1;
BA_ "GenSigStartValueInteger" SG_ 806 HvacEvap_Te_Rq 400;
BA_ "GenSigStartValueInteger" SG_ 806 HvacEvap_Te_Actl 400;
BA_ "GenSigStartValueInteger" SG_ 806 HvacEvap_Te_Offst 400;
BA_ "GenSigStartValueInteger" SG_ 806 ClimtDeltaLoad_Pw_Actl 32;
BA_ "U_CX727_MY2021_Tx" SG_ 578 PtLatchActv_B_RqBcm 1;
BA_ "U_P702_MY2021_Tx" SG_ 578 PtLatchActv_B_RqBcm 1;
BA_ "U_T6_MCA_MY2020_Tx" SG_ 578 PtLatchActv_B_RqBcm 1;
BA_ "U_CD542_MY2021_Tx" SG_ 578 PtLatchActv_B_RqBcm 1;
BA_ "U_U55X_MY2022_Tx" SG_ 578 PtLatchActv_B_RqBcm 1;
BA_ "U_CD764_MY2022_Tx" SG_ 578 PtLatchActv_B_RqBcm 1;
BA_ "U_CX727_MY2021_Rx" SG_ 578 immoSecureIdleMode 1;
BA_ "U_CX727_MY2021_Tx" SG_ 578 immoSecureIdleMode 1;
BA_ "U_P702_MY2021_Tx" SG_ 578 immoSecureIdleMode 1;
BA_ "U_T6_MCA_MY2020_Tx" SG_ 578 immoSecureIdleMode 1;
BA_ "U_CD542_MY2021_Tx" SG_ 578 immoSecureIdleMode 1;
BA_ "U_U55X_MY2022_Tx" SG_ 578 immoSecureIdleMode 1;
BA_ "U_CD764_MY2022_Tx" SG_ 578 immoSecureIdleMode 1;
BA_ "WakeupSignal" SG_ 578 ReFuelSwtchStat_D_Actl 1;
BA_ "U_CX727_MY2021_Tx" SG_ 578 ReFuelSwtchStat_D_Actl 1;
BA_ "U_P702_MY2021_Tx" SG_ 578 ReFuelSwtchStat_D_Actl 1;
BA_ "U_T6_MCA_MY2020_Tx" SG_ 578 ReFuelSwtchStat_D_Actl 1;
BA_ "U_CD542_MY2021_Tx" SG_ 578 ReFuelSwtchStat_D_Actl 1;
BA_ "U_U55X_MY2022_Tx" SG_ 578 ReFuelSwtchStat_D_Actl 1;
BA_ "U_CD764_MY2022_Tx" SG_ 578 ReFuelSwtchStat_D_Actl 1;
BA_ "U_CX727_MY2021_Tx" SG_ 578 FuelPumpPwr_D_Stat 1;
BA_ "U_P702_MY2021_Tx" SG_ 578 FuelPumpPwr_D_Stat 1;
BA_ "U_T6_MCA_MY2020_Tx" SG_ 578 FuelPumpPwr_D_Stat 1;
BA_ "U_CD542_MY2021_Tx" SG_ 578 FuelPumpPwr_D_Stat 1;
BA_ "U_U55X_MY2022_Tx" SG_ 578 FuelPumpPwr_D_Stat 1;
BA_ "U_CD764_MY2022_Tx" SG_ 578 FuelPumpPwr_D_Stat 1;
BA_ "GenSigStartValueInteger" SG_ 578 BattULo_U_Actl 255;
BA_ "GenSigStartValue" SG_ 578 BattULo_U_Actl 255;
BA_ "U_CX727_MY2021_Rx" SG_ 578 BattULo_U_Actl 1;
BA_ "U_P702_MY2021_Rx" SG_ 578 BattULo_U_Actl 1;
BA_ "U_CD542_MY2021_Rx" SG_ 578 BattULo_U_Actl 1;
BA_ "U_T6_MCA_MY2020_Rx" SG_ 578 BattULo_U_Actl 1;
BA_ "ECGUsedRxSignal" SG_ 578 BattULo_U_Actl 1;
BA_ "U_U55X_MY2022_Rx" SG_ 578 BattULo_U_Actl 1;
BA_ "U_CX727_MY2021_Tx" SG_ 578 BattULo_U_Actl 1;
BA_ "U_P702_MY2021_Tx" SG_ 578 BattULo_U_Actl 1;
BA_ "U_T6_MCA_MY2020_Tx" SG_ 578 BattULo_U_Actl 1;
BA_ "U_CD542_MY2021_Tx" SG_ 578 BattULo_U_Actl 1;
BA_ "U_U55X_MY2022_Tx" SG_ 578 BattULo_U_Actl 1;
BA_ "U_CD764_MY2022_Tx" SG_ 578 BattULo_U_Actl 1;
BA_ "U_CX727_MY2021_Tx" SG_ 578 PrkLckCtl_B_Enbl 1;
BA_ "U_P702_MY2021_Tx" SG_ 578 PrkLckCtl_B_Enbl 1;
BA_ "U_T6_MCA_MY2020_Tx" SG_ 578 PrkLckCtl_B_Enbl 1;
BA_ "U_CD542_MY2021_Tx" SG_ 578 PrkLckCtl_B_Enbl 1;
BA_ "U_U55X_MY2022_Tx" SG_ 578 PrkLckCtl_B_Enbl 1;
BA_ "U_CD764_MY2022_Tx" SG_ 578 PrkLckCtl_B_Enbl 1;
BA_ "WakeupSignal" SG_ 578 PrkLckCtlMsgTxt_D_Rq 1;
BA_ "U_CX727_MY2021_Tx" SG_ 578 PrkLckCtlMsgTxt_D_Rq 1;
BA_ "U_P702_MY2021_Tx" SG_ 578 PrkLckCtlMsgTxt_D_Rq 1;
BA_ "U_T6_MCA_MY2020_Tx" SG_ 578 PrkLckCtlMsgTxt_D_Rq 1;
BA_ "U_CD542_MY2021_Tx" SG_ 578 PrkLckCtlMsgTxt_D_Rq 1;
BA_ "U_U55X_MY2022_Tx" SG_ 578 PrkLckCtlMsgTxt_D_Rq 1;
BA_ "U_CD764_MY2022_Tx" SG_ 578 PrkLckCtlMsgTxt_D_Rq 1;
BA_ "WakeupSignal" SG_ 578 PrkLckCtlAvail_T_Stat 1;
BA_ "U_CX727_MY2021_Tx" SG_ 578 PrkLckCtlAvail_T_Stat 1;
BA_ "U_P702_MY2021_Tx" SG_ 578 PrkLckCtlAvail_T_Stat 1;
BA_ "U_T6_MCA_MY2020_Tx" SG_ 578 PrkLckCtlAvail_T_Stat 1;
BA_ "U_CD542_MY2021_Tx" SG_ 578 PrkLckCtlAvail_T_Stat 1;
BA_ "U_U55X_MY2022_Tx" SG_ 578 PrkLckCtlAvail_T_Stat 1;
BA_ "U_CD764_MY2022_Tx" SG_ 578 PrkLckCtlAvail_T_Stat 1;
BA_ "U_CX727_MY2021_Tx" SG_ 578 BrkTrnShifLck_B_Stat 1;
BA_ "U_P702_MY2021_Tx" SG_ 578 BrkTrnShifLck_B_Stat 1;
BA_ "U_T6_MCA_MY2020_Tx" SG_ 578 BrkTrnShifLck_B_Stat 1;
BA_ "U_CD542_MY2021_Tx" SG_ 578 BrkTrnShifLck_B_Stat 1;
BA_ "U_U55X_MY2022_Tx" SG_ 578 BrkTrnShifLck_B_Stat 1;
BA_ "U_CD764_MY2022_Tx" SG_ 578 BrkTrnShifLck_B_Stat 1;
BA_ "U_CX727_MY2021_Tx" SG_ 578 PrkLckCtlUnlck_D_Stat 1;
BA_ "U_P702_MY2021_Tx" SG_ 578 PrkLckCtlUnlck_D_Stat 1;
BA_ "U_T6_MCA_MY2020_Tx" SG_ 578 PrkLckCtlUnlck_D_Stat 1;
BA_ "U_CD542_MY2021_Tx" SG_ 578 PrkLckCtlUnlck_D_Stat 1;
BA_ "U_U55X_MY2022_Tx" SG_ 578 PrkLckCtlUnlck_D_Stat 1;
BA_ "U_CD764_MY2022_Tx" SG_ 578 PrkLckCtlUnlck_D_Stat 1;
BA_ "U_CX727_MY2021_Tx" SG_ 578 PrkLckCtlTow_B_Enbl 1;
BA_ "U_P702_MY2021_Tx" SG_ 578 PrkLckCtlTow_B_Enbl 1;
BA_ "U_T6_MCA_MY2020_Tx" SG_ 578 PrkLckCtlTow_B_Enbl 1;
BA_ "U_CD542_MY2021_Tx" SG_ 578 PrkLckCtlTow_B_Enbl 1;
BA_ "U_U55X_MY2022_Tx" SG_ 578 PrkLckCtlTow_B_Enbl 1;
BA_ "U_CD764_MY2022_Tx" SG_ 578 PrkLckCtlTow_B_Enbl 1;
BA_ "U_CX727_MY2021_Tx" SG_ 578 DriverCrankingReq 1;
BA_ "U_P702_MY2021_Tx" SG_ 578 DriverCrankingReq 1;
BA_ "U_T6_MCA_MY2020_Tx" SG_ 578 DriverCrankingReq 1;
BA_ "U_CD542_MY2021_Tx" SG_ 578 DriverCrankingReq 1;
BA_ "U_U55X_MY2022_Tx" SG_ 578 DriverCrankingReq 1;
BA_ "U_CD764_MY2022_Tx" SG_ 578 DriverCrankingReq 1;
BA_ "U_U55X_MY2022_Rx" SG_ 578 EngOff_T_Actl 1;
BA_ "U_CX727_MY2021_Tx" SG_ 578 EngOff_T_Actl 1;
BA_ "U_P702_MY2021_Tx" SG_ 578 EngOff_T_Actl 1;
BA_ "U_T6_MCA_MY2020_Tx" SG_ 578 EngOff_T_Actl 1;
BA_ "U_CD542_MY2021_Tx" SG_ 578 EngOff_T_Actl 1;
BA_ "U_U55X_MY2022_Tx" SG_ 578 EngOff_T_Actl 1;
BA_ "U_CD764_MY2022_Tx" SG_ 578 EngOff_T_Actl 1;
BA_ "U_CX727_MY2021_Tx" SG_ 578 DcacElPw_D_Rq 1;
BA_ "U_P702_MY2021_Tx" SG_ 578 DcacElPw_D_Rq 1;
BA_ "U_T6_MCA_MY2020_Tx" SG_ 578 DcacElPw_D_Rq 1;
BA_ "U_CD542_MY2021_Tx" SG_ 578 DcacElPw_D_Rq 1;
BA_ "U_U55X_MY2022_Tx" SG_ 578 DcacElPw_D_Rq 1;
BA_ "U_CD764_MY2022_Tx" SG_ 578 DcacElPw_D_Rq 1;
BA_ "GenSigStartValueInteger" SG_ 578 BattULo_I_Actl 16383;
BA_ "GenSigStartValue" SG_ 578 BattULo_I_Actl 16383;
BA_ "U_CX727_MY2021_Tx" SG_ 578 BattULo_I_Actl 1;
BA_ "U_P702_MY2021_Tx" SG_ 578 BattULo_I_Actl 1;
BA_ "U_T6_MCA_MY2020_Tx" SG_ 578 BattULo_I_Actl 1;
BA_ "U_CD542_MY2021_Tx" SG_ 578 BattULo_I_Actl 1;
BA_ "U_U55X_MY2022_Tx" SG_ 578 BattULo_I_Actl 1;
BA_ "U_CD764_MY2022_Tx" SG_ 578 BattULo_I_Actl 1;
BA_ "U_T6_MCA_MY2020_Rx" SG_ 514 StrtrMtrCtlMsgTxt_D2_Rq 1;
BA_ "U_CD542_MY2021_Rx" SG_ 514 StrtrMtrCtlMsgTxt_D2_Rq 1;
BA_ "U_U55X_MY2022_Rx" SG_ 514 StrtrMtrCtlMsgTxt_D2_Rq 1;
BA_ "U_CD764_MY2022_Rx" SG_ 514 StrtrMtrCtlMsgTxt_D2_Rq 1;
BA_ "U_CX727_MY2021_Rx" SG_ 514 StrtrMtrDlyStrt_B_Stat 1;
BA_ "U_P702_MY2021_Rx" SG_ 514 StrtrMtrDlyStrt_B_Stat 1;
BA_ "U_T6_MCA_MY2020_Rx" SG_ 514 StrtrMtrDlyStrt_B_Stat 1;
BA_ "U_CD542_MY2021_Rx" SG_ 514 StrtrMtrDlyStrt_B_Stat 1;
BA_ "U_U55X_MY2022_Rx" SG_ 514 StrtrMtrDlyStrt_B_Stat 1;
BA_ "U_CD764_MY2022_Rx" SG_ 514 StrtrMtrDlyStrt_B_Stat 1;
BA_ "MetaData" SG_ 514 VehVActlEng_No_Cs 1;
BA_ "MetaData" SG_ 514 VehVActlEng_No_Cnt 1;
BA_ "MetaData" SG_ 514 VehVActlEng_D_Qf 1;
BA_ "U_CX727_MY2021_Rx" SG_ 514 VehVActlEng_D_Qf 1;
BA_ "U_P702_MY2021_Rx" SG_ 514 VehVActlEng_D_Qf 1;
BA_ "U_T6_MCA_MY2020_Rx" SG_ 514 VehVActlEng_D_Qf 1;
BA_ "U_CD542_MY2021_Rx" SG_ 514 VehVActlEng_D_Qf 1;
BA_ "U_U55X_MY2022_Rx" SG_ 514 VehVActlEng_D_Qf 1;
BA_ "U_CD764_MY2022_Rx" SG_ 514 VehVActlEng_D_Qf 1;
BA_ "U_CX727_MY2021_Rx" SG_ 514 Veh_V_ActlEng 1;
BA_ "U_P702_MY2021_Rx" SG_ 514 Veh_V_ActlEng 1;
BA_ "U_T6_MCA_MY2020_Rx" SG_ 514 Veh_V_ActlEng 1;
BA_ "U_CD542_MY2021_Rx" SG_ 514 Veh_V_ActlEng 1;
BA_ "U_U55X_MY2022_Rx" SG_ 514 Veh_V_ActlEng 1;
BA_ "U_CD764_MY2022_Rx" SG_ 514 Veh_V_ActlEng 1;
BA_ "ContentDependant" SG_ 514 EngAout_Tq_VacLimSpcN 1;
BA_ "ContentDependant" SG_ 514 EngCylSync_No_Ctr 1;
BA_ "GenSigStartValueInteger" SG_ 514 GearRvrse_D_Actl 7;
BA_ "GenSigStartValue" SG_ 514 GearRvrse_D_Actl 7;
BA_ "U_CX727_MY2021_Rx" SG_ 514 GearRvrse_D_Actl 1;
BA_ "U_P702_MY2021_Rx" SG_ 514 GearRvrse_D_Actl 1;
BA_ "U_T6_MCA_MY2020_Rx" SG_ 514 GearRvrse_D_Actl 1;
BA_ "U_CD542_MY2021_Rx" SG_ 514 GearRvrse_D_Actl 1;
BA_ "U_U55X_MY2022_Rx" SG_ 514 GearRvrse_D_Actl 1;
BA_ "U_CD764_MY2022_Rx" SG_ 514 GearRvrse_D_Actl 1;
BA_ "GenSigStartValueInteger" SG_ 1057 FohEng_D_Rq 2;
BA_ "ContentDependant" SG_ 1057 FohEng_D_Rq 1;
BA_ "GenSigStartValue" SG_ 1057 FohEng_D_Rq 2;
BA_ "ContentDependant" SG_ 1057 EngIdlShutDown_D_Stat 1;
BA_ "U_CX727_MY2021_Rx" SG_ 1057 EngIdlShutDown_D_Stat 1;
BA_ "U_P702_MY2021_Rx" SG_ 1057 EngIdlShutDown_D_Stat 1;
BA_ "U_T6_MCA_MY2020_Rx" SG_ 1057 EngIdlShutDown_D_Stat 1;
BA_ "U_CD542_MY2021_Rx" SG_ 1057 EngIdlShutDown_D_Stat 1;
BA_ "U_U55X_MY2022_Rx" SG_ 1057 EngIdlShutDown_D_Stat 1;
BA_ "U_CD764_MY2022_Rx" SG_ 1057 EngIdlShutDown_D_Stat 1;
BA_ "GenSigStartValueInteger" SG_ 1057 FUEL_ALCOHOL_PERCNT 255;
BA_ "ContentDependant" SG_ 1057 FUEL_ALCOHOL_PERCNT 1;
BA_ "GenSigStartValue" SG_ 1057 FUEL_ALCOHOL_PERCNT 255;
BA_ "ContentDependant" SG_ 1057 TrnTotTq_Rt_Est 1;
BA_ "ContentDependant" SG_ 1057 TrnTotLss_Tq_Est 1;
BA_ "ContentDependant" SG_ 1057 VehVLimStat_D_Actl 1;
BA_ "ContentDependant" SG_ 1057 VehVLimActv_B_Actl 1;
BA_ "U_CX727_MY2021_Rx" SG_ 1057 CoolantFanStepAct 1;
BA_ "U_P702_MY2021_Rx" SG_ 1057 CoolantFanStepAct 1;
BA_ "U_T6_MCA_MY2020_Rx" SG_ 1057 CoolantFanStepAct 1;
BA_ "U_CD542_MY2021_Rx" SG_ 1057 CoolantFanStepAct 1;
BA_ "U_U55X_MY2022_Rx" SG_ 1057 CoolantFanStepAct 1;
BA_ "U_CD764_MY2022_Rx" SG_ 1057 CoolantFanStepAct 1;
VAL_ 753 EdmSailMde_B_RqDrv_UB 1 "Fresh_data" 0 "Unchanged_data" ;
VAL_ 753 TurnLampRrOut_B_Stat_UB 1 "Fresh_data" 0 "Unchanged_data" ;
VAL_ 753 TurnLampRrOut_B_Stat 1 "Out" 0 "Null" ;
VAL_ 753 TurnLampRlOut_B_Stat_UB 1 "Fresh_data" 0 "Unchanged_data" ;
VAL_ 753 TurnLampRlOut_B_Stat 1 "Out" 0 "Null" ;
VAL_ 753 CnvtTopPos_Up_Stat_UB 1 "Fresh_data" 0 "Unchanged_data" ;
VAL_ 753 GlvBoxRleas_No_Actl_UB 1 "Fresh_data" 0 "Unchanged_data" ;
VAL_ 753 ValetMode_D_Stat_UB 1 "Fresh_data" 0 "Unchanged_data" ;
VAL_ 753 RollCodeValet_UB 1 "Fresh_data" 0 "Unchanged_data" ;
VAL_ 753 ApaMdeStat_D_RqDrv_UB 1 "Fresh_data" 0 "Unchanged_data" ;
VAL_ 753 EdmSailMde_B_RqDrv 1 "On" 0 "Off" ;
VAL_ 753 LpdbPtc3_B_Rq 1 "On" 0 "Off" ;
VAL_ 753 LpdbPtc2_B_Rq 1 "On" 0 "Off" ;
VAL_ 753 LpdbPtc1_B_Rq 1 "On" 0 "Off" ;
VAL_ 753 Em_D_Stat_UB 1 "Fresh_data" 0 "Unchanged_data" ;
VAL_ 753 LpdbHeatWiprPrk_B_Rq 1 "On" 0 "Off" ;
VAL_ 753 LpdbDfrstRearOn_B_Rq_UB 1 "Fresh_data" 0 "Unchanged_data" ;
VAL_ 753 LpdbDfrstRearOn_B_Rq 1 "On" 0 "Off" ;
VAL_ 753 LpdbDfrstFrOn_B_Rq 1 "On" 0 "Off" ;
VAL_ 753 LpdbDfrstFlOn_B_Rq 1 "On" 0 "Off" ;
VAL_ 753 LpdbAuxBlwr_B_Rq 1 "On" 0 "Off" ;
VAL_ 753 ApaMdeStat_D_RqDrv 7 "Faulty" 6 "Off" 5 "NotUsed2" 4 "NotUsed1" 3 "POA" 2 "PPA" 1 "SAPP" 0 "Inactive" ;
VAL_ 753 Em_D_Stat 3 "NotSupported" 2 "ProfilesOff" 1 "ProfilesOn" 0 "Null" ;
VAL_ 753 PrkAidSwtch_D_RqDrv 1 "Pressed" 0 "Not_Pressed" ;
VAL_ 753 PrkAidSwtch_D_RqDrv_UB 1 "Fresh_data" 0 "Unchanged_data" ;
VAL_ 753 ValetMode_D_Stat 3 "NotUsed" 2 "On" 1 "Off" 0 "Null" ;
VAL_ 753 CnvtTopPos_Up_Stat 1 "Up" 0 "Not_Up" ;
VAL_ 753 CnvtTopPos_Dn_Stat_UB 1 "Fresh_data" 0 "Unchanged_data" ;
VAL_ 753 CnvtTopPos_Dn_Stat 1 "Down" 0 "Not_Down" ;
VAL_ 818 WndwUpDrvRear_D_Falt 3 "NotUsed" 2 "Fault" 1 "NoFault" 0 "Null" ;
VAL_ 818 WndwUpDrvFront_D_Falt 3 "NotUsed" 2 "Fault" 1 "NoFault" 0 "Null" ;
VAL_ 818 DrvSpotLight_B_Stat 1 "Active" 0 "Inactive" ;
VAL_ 818 DrPrsntDrv_D_Stat 3 "Faulty" 2 "Present" 1 "NotPresent" 0 "NotDetermined" ;
VAL_ 818 DrPrsntRearDrv_D_Stat 3 "Faulty" 2 "Present" 1 "NotPresent" 0 "NotDetermined" ;
VAL_ 818 DrDrvMsgTxt_B_Rq 1 "Yes" 0 "No" ;
VAL_ 818 WndwDrvSide_D_Stat 3 "BothWindow_Operating" 2 "RearWindow_Operating" 1 "FrontWindow_Operating" 0 "NoWindows_Operating" ;
VAL_ 818 RvrseMirrorChime_B_Rq 1 "Yes" 0 "No" ;
VAL_ 818 BLISLEDStatDriverSide 3 "Fault" 2 "Unused" 1 "On" 0 "Off" ;
VAL_ 818 KeyCylSwDrvDr_D_Stat 3 "NotUsed" 2 "Unlock" 1 "Lock" 0 "Null" ;
VAL_ 818 Driver_Lock_Sw_Stat 3 "Invalid" 2 "Unlock" 1 "Lock" 0 "Null" ;
VAL_ 818 ChildLckPw_D_Rq 1 "Active" 0 "Null" ;
VAL_ 818 ChildLckFdbckRd_B_Stat 1 "Locked" 0 "Unlock" ;
VAL_ 817 ChildLckMde_B_Stat 1 "Enable" 0 "Disable" ;
VAL_ 817 VehLckInd_D_Rq 3 "NotUsed" 2 "On_Day" 1 "On_Night" 0 "Off" ;
VAL_ 817 DrTgateOpen_B_Rq 1 "Open" 0 "Null" ;
VAL_ 817 DrTgateExtSwMde_B_Stat 1 "Enable" 0 "Disable" ;
VAL_ 817 Remote_Device_Feedback 7 "Unused3" 6 "Unused2" 5 "Unused1" 4 "Shutdown" 3 "Running" 2 "Starting" 1 "Acknowledge" 0 "Null" ;
VAL_ 817 Veh_Lock_Requestor 31 "Walk_Away_Locking" 30 "Remote_Park_Assist" 29 "DoorsOffToOn_Smart_Unlock" 28 "Rgtm_Shutlock_Switch" 27 "Boundary_Alert" 26 "Transit_Vehicle_Relock" 25 "Transit_Cargo_Relock" 24 "Transit_Ajar_Lock" 23 "Diagnostics" 22 "Console_Lock" 21 "Child_Lock" 20 "Double_Lock" 19 "Passive_Pasenger" 18 "Passive_Driver" 17 "Slam_Lock_Protect" 16 "SYNC" 15 "Passport" 14 "Passive_Smart_Unlock" 13 "Autorelock" 12 "RemoteStart" 0 "Null" 1 "Autolock" 11 "Smart_Unlock" 10 "Sliding_Door" 9 "Passive" 8 "Remote" 7 "Programming" 6 "Powerslide" 5 "Keypad" 4 "Key_Cylinder" 3 "Interior" 2 "Auto_Unlock" ;
VAL_ 817 R_Pwr_Sliding_Dr_Rqst 1 "Active" 0 "Null" ;
VAL_ 817 Power_Liftgate_Rqst 1 "Active" 0 "Null" ;
VAL_ 817 Power_Decklid_Rqst 1 "Active" 0 "Null" ;
VAL_ 817 L_Pwr_Sliding_Dr_Rqst 1 "Active" 0 "Null" ;
VAL_ 817 Veh_Lock_Sub_Id 15 "Unused7" 14 "Unused6" 13 "Unused5" 12 "Unused4" 11 "Unused3" 10 "Unused2" 9 "Unused1" 8 "Customer_8" 7 "Customer_7" 6 "Customer_6" 5 "Customer_5" 4 "Customer_4" 3 "Customer_3" 2 "Customer_2" 1 "Customer_1" 0 "Null" ;
VAL_ 817 Veh_Lock_Status 3 "UNLOCK_DRV" 2 "UNLOCK_ALL" 1 "LOCK_ALL" 0 "LOCK_DBL" ;
VAL_ 817 ChildLck_D_Dsply 3 "NOT_SUPPORTED" 2 "ERROR" 1 "CHILD_UNLOCK" 0 "CHILD_LOCK" ;
VAL_ 817 WindowLockout_B_Stat 1 "Locked" 0 "Unlock" ;
VAL_ 817 Lockmsgtxt_D_Rq 7 "MSG7" 6 "MSG6" 5 "MSG5" 4 "MSG4" 3 "MSG3" 2 "MSG2" 1 "MSG1" 0 "NO_WARNING" ;
VAL_ 817 FobComm_D_Stat 3 "NotUsed" 2 "RemEngStartOK" 1 "RemEngStartFail" 0 "Null" ;
VAL_ 817 LockInhibit 1 "Inhibit" 0 "No_Inhibit" ;
VAL_ 1002 CntrStk_D_RqRecall 7 "Unused_2" 6 "Unused_1" 5 "Vehicle" 4 "PERS_4" 3 "PERS_3" 2 "PERS_2" 1 "PERS_1" 0 "Null" ;
VAL_ 1002 CntrStk_D_RqAssoc 7 "Unused_2" 6 "Cancel" 5 "Set_Keycode" 4 "RKE" 3 "Null" 2 "Key" 1 "Erase_KeyCode" 0 "Check_KeyCode" ;
VAL_ 1002 PersIndexApim_D_Actl 7 "Unused_3" 6 "Unused_2" 5 "Unused_1" 4 "Vehicle" 3 "PERS_4" 2 "PERS_3" 1 "PERS_2" 0 "PERS_1" ;
VAL_ 1046 PrkBrkDynmc_D_Allw 3 "NotUsed" 2 "EPB_ECD_NotPossible" 1 "EPB_ECD_Possible" 0 "Used_at_Start_Up" ;
VAL_ 1046 BrkPrkBrkDynmc_B_Actl 1 "Active" 0 "Inactive" ;
VAL_ 1046 TRLR_SWAY_EVNT_IN_PROG 1 "Yes" 0 "No" ;
VAL_ 1046 TRLR_SWAY_CONFIG_STAT 1 "On" 0 "Off" ;
VAL_ 1046 HsaMde_D_Mem 3 "Undefined" 2 "Manual" 1 "Automatic" 0 "Off" ;
VAL_ 1046 BrkBstrVac_B_Rq 1 "Yes" 0 "No" ;
VAL_ 1046 DrvSlipCtlMde_D_Ind 3 "App_Specific_Off_Mode_3" 2 "App_Specific_Off_Mode_2" 1 "App_Specific_Off_Mode_1" 0 "Default_Mode" ;
VAL_ 1046 DrvAntiLckLamp_D_Rq 3 "Fast_Flash" 2 "Slow_Flash" 1 "On" 0 "Off" ;
VAL_ 1046 StabCtlBrk_B_Avail 1 "Yes" 0 "No" ;
VAL_ 1046 DrvHdcWarnInfo_D_Rq 3 "Undefined" 2 "Lamp_On_Continuously" 1 "Lamp_Flashing" 0 "Lamp_Off_Continuously" ;
VAL_ 1046 DrvHdcMsg_D_Rq 7 "Undefined" 6 "Speed_too_High" 5 "Temporarily_Unavailable" 4 "System_Fault" 3 "Select_Gear" 2 "Off" 1 "On" 0 "No_Message" ;
VAL_ 1046 DrvHdcLampInfo_D_Rq 3 "Fast_Flash" 2 "Slow_Flash" 1 "On" 0 "Off" ;
VAL_ 1046 ChimeBrk_B_Rq 1 "Yes" 0 "No" ;
VAL_ 1046 BrkLamp_B_Rq 1 "Yes" 0 "No" ;
VAL_ 1046 HILL_DESC_MC 7 "Fault_Detected" 6 "Cooling_Down" 5 "Abort_Apply_Brakes" 4 "Active" 3 "Disabled" 2 "Enabled" 1 "Off_Road" 0 "Normal" ;
VAL_ 1046 RearDiffLck_Tq2_RqMx 4095 "Faulty" ;
VAL_ 1046 HdcMde_D_Actl 7 "Fault" 6 "Temporarily_Unavailable" 5 "NotEnabled_WrongGearSel" 4 "NotEnabled_SpdLimitExceed" 3 "Active_Braking" 2 "Not_Active_Braking" 1 "Off" 0 "Undefined" ;
VAL_ 1046 TCMode 1 "Active" 0 "Inactive" ;
VAL_ 1046 DrvSlipCtlLamp_D_Rq 3 "Fast_Flash" 2 "Slow_Flash" 1 "On" 0 "Off" ;
VAL_ 1046 Abs_B_Falt 1 "Yes" 0 "No" ;
VAL_ 1046 RearDiffElckrOpen_B_Rq 1 "Yes" 0 "No" ;
VAL_ 1046 BpedMove_D_Actl 3 "Unknown" 2 "DriverApplyingBrakePedal" 1 "NoAutonomousBrkPdlMovement" 0 "AutonomousBrkPedalMove" ;
VAL_ 125 VehRolComp_W_Actl 4094 "NoDataExists" 4095 "Fault" ;
VAL_ 125 VehVertComp_A_Actl 1022 "NoDataExists" 1023 "Fault" ;
VAL_ 125 BrkTot_Tq_RqArb 8191 "Fault" 8190 "Unknown" ;
VAL_ 125 BrkTot_Tq_Actl 8191 "Fault" 8190 "Unknown" ;
VAL_ 125 HsaStat_D_Actl 7 "Faulty" 6 "FaultyWithDriverIndication" 5 "SlowRelease" 4 "FastRelease" 3 "ActiveBrakePedalReleased" 2 "ActiveBrakePedalPressed" 1 "FindingGradient" 0 "Inactive" ;
VAL_ 119 VehLongComp_A_Actl 1023 "Fault" 1022 "NoDataExists" ;
VAL_ 119 VehLatComp_A_Actl 1023 "Fault" 1022 "NoDataExists" ;
VAL_ 119 VehYawComp_W_Actl 4095 "Fault" 4094 "NoDataExists" ;
VAL_ 119 VehOverGnd_V_Est 65535 "Invalid" 65534 "Unknown" ;
VAL_ 1045 VehStab_D_Stat 15 "Faulty" 14 "No_Data_Exists" 13 "NotUsed6" 12 "NotUsed5" 11 "NotUsed4" 10 "NotUsed3" 9 "NotUsed2" 8 "Combined_OS_and_US" 7 "High_SSRA_no_OS" 6 "Straight" 5 "Post_Oversteer" 4 "Post_Transition" 3 "Countersteer" 2 "Understeer" 1 "Oversteer" 0 "Linear" ;
VAL_ 1045 BrkFluidLvl_D_Stat 3 "Invalid" 2 "Unknown" 1 "Low" 0 "OK" ;
VAL_ 1045 LsmcBrkDecel_D_Stat 7 "NotUsed_3" 6 "NotUsed_2" 5 "NotUsed_1" 4 "Denied" 3 "FaultDegraded" 2 "FaultExt" 1 "On" 0 "Off" ;
VAL_ 1045 VehYawNonLin_W_Rq 4095 "Fault" 4094 "Unknown" ;
VAL_ 1045 VehYawLin_W_Rq 4095 "Fault" 4094 "Unknown" ;
VAL_ 1045 VehVActlBrk_D_Qf 3 "OK" 2 "Not_Within_Specifications" 1 "No_Data_Exists" 0 "Faulty" ;
VAL_ 534 WhlDirRr_D_Actl 3 "Faulty" 2 "NoDataExists" 1 "Backward" 0 "Forward" ;
VAL_ 534 WhlDirRl_D_Actl 3 "Faulty" 2 "NoDataExists" 1 "Backward" 0 "Forward" ;
VAL_ 534 WhlDirFr_D_Actl 3 "Faulty" 2 "NoDataExists" 1 "Backward" 0 "Forward" ;
VAL_ 534 WhlDirFl_D_Actl 3 "Faulty" 2 "NoDataExists" 1 "Backward" 0 "Forward" ;
VAL_ 531 VehStop_D_Stat 3 "Faulty" 2 "NoDataExists" 1 "Yes" 0 "No" ;
VAL_ 531 TracCtlPtActv_B_Actl 1 "Active" 0 "Inactive" ;
VAL_ 531 LscmbbMntr_B_Err 1 "DisplayMessage" 0 "NoMessage" ;
VAL_ 531 LscmbbBrkDis_B_Actl 1 "Yes" 0 "No" ;
VAL_ 531 StabCtlBrkActv_B_Actl 1 "Yes" 0 "No" ;
VAL_ 531 CmbbBrkPrchg_B_Actl 1 "Yes" 0 "No" ;
VAL_ 531 CmbbBrkDecel_B_Actl 1 "Yes" 0 "No" ;
VAL_ 531 CmbbBaSensInc_B_Actl 1 "Yes" 0 "No" ;
VAL_ 531 AccBrkWarm_B_Actl 1 "Yes" 0 "No" ;
VAL_ 531 AccBrkTotTqMn_B_Actl 1 "Yes" 0 "No" ;
VAL_ 531 AccBrkPrchgActv_B_Actl 1 "Yes" 0 "No" ;
VAL_ 531 AccBrkDis_B_Actl 1 "Yes" 0 "No" ;
VAL_ 531 AccBrkDeny_B_Actl 1 "Yes" 0 "No" ;
VAL_ 531 AccBrkActv_B_Actl 1 "Yes" 0 "No" ;
VAL_ 531 PrplDrgCtlActv_B_Actl 1 "Active" 0 "Inactive" ;
VAL_ 531 AbsActv_B_Actl 1 "Yes" 0 "No" ;
VAL_ 531 CmbbBrkDis_B_Actl 1 "Yes" 0 "No" ;
VAL_ 531 CmbbDeny_B_ActlBrk 1 "Yes" 0 "No" ;
VAL_ 531 CcDis_B_Cmd 1 "Yes" 0 "No" ;
VAL_ 531 VehLongOvrGnd_A_Est 1023 "Fault" 1022 "Unknown" ;
VAL_ 531 AccStopActv_B_ActlBrk 1 "Yes" 0 "No" ;
VAL_ 531 AccDis_B_ActlEpb 1 "Yes" 0 "No" ;
VAL_ 531 PrkBrkYwLamp_D_Rq 3 "Fast_Flash" 2 "Slow_Flash" 1 "On" 0 "Off" ;
VAL_ 531 PrkBrkRedLamp_D_Rq 3 "Fast_Flash" 2 "Slow_Flash" 1 "On" 0 "Off" ;
VAL_ 531 PrkBrkMsgTxt_D_Rq 15 "Message15" 14 "Message14" 13 "Message13" 12 "Message12" 11 "Message11" 10 "Message10" 9 "Message9" 8 "Message8" 7 "Message7" 6 "Message6" 5 "Message5" 4 "Message4" 3 "Message3" 2 "Message2" 1 "Message1" 0 "No_Message" ;
VAL_ 531 PrkBrkStatus 7 "GeneralFault_MaintenceMode" 6 "ECD_by_Brake_ECU_Active" 5 "EPB_Limphome_Active" 4 "Rear_Caliper_Open" 3 "RWU_By_EPB_Active" 2 "Rear_Caliper_Transition" 1 "Rear_Caliper_Closed" 0 "Not_Supported" ;
VAL_ 531 VehicleStationary 1 "Yes" 0 "No" ;
VAL_ 531 LscmbbDeny_B_ActlBrk 1 "Yes" 0 "No" ;
VAL_ 531 LscmbbBrkDecel_B_Actl 1 "Yes" 0 "No" ;
VAL_ 531 LscmbbBaSensInc_B_Actl 1 "Yes" 0 "No" ;
VAL_ 531 LscmbBrkPrchg_B_Actl 1 "Active" 0 "Inactive" ;
VAL_ 535 WhlRr_W_Meas 32767 "Fault" 32766 "Unknown" ;
VAL_ 535 WhlRl_W_Meas 32767 "Fault" 32766 "Unknown" ;
VAL_ 535 WhlFr_W_Meas 32767 "Fault" 32766 "Unknown" ;
VAL_ 535 WhlFl_W_Meas 32767 "Fault" 32766 "Unknown" ;
VAL_ 611 AwdTerrMdeChng_D_Rdy 7 "Fault" 6 "Undefined_2" 5 "Undefined_1" 4 "ModeUnavailDrInputRqd" 3 "SpOpModes_NotSupported" 2 "ModeUnavailDynamicCond" 1 "Module_In_Initialization" 0 "Mode_Change_Available" ;
VAL_ 611 AwdTerrMde_D_Actl 7 "Fail_Safe_Default" 6 "Dynamic_Mode" 5 "Rock_Crawl_Mode" 4 "Mud_Ruts_Mode" 3 "Sand_Mode" 2 "Undefined" 1 "Low_Mu_Mode" 0 "Special_Operating_Mode_Off" ;
VAL_ 611 AwdSys_D_Stat 3 "Faulty" 2 "NotUsed" 1 "_4x4_L_H_Active" 0 "_4x4_L_H_Inactive" ;
VAL_ 611 SelDrvMdeAwd_D_Stat 0 "NotAvailable" 1 "Available" 2 "TemporarilyNotAvailable" 3 "Faulty" ;
VAL_ 611 AwdStat_D_RqDsply 31 "Rear_Diff_Lock_Not_Avail" 30 "_4wd_Lock_Required" 29 "Cfg_Perf_Redc_See_Manual" 28 "To_Engage_4x4_Release_Aped" 27 "To_Engage_4x4_Slow_To_3MPH" 26 "Shift_To_Neutral" 25 "Lkr_Mode_Unavail_TMS" 24 " _4x4_Mode_Unavail_TMS" 23 "Out_of_4Low_Crawl" 22 "AWD_PTU_Oil_Changed" 21 "Change_AWD_PTU_Oil" 20 "Neutral_Tow_Disabled" 19 "Neutral_Tow_Enabled" 18 "AWD_OFF" 17 "_4x4_Off_Road_Speed" 16 "_4x4_Extreme_Off_Road_Mode" 15 "_4x4_Exiting_Off_Road" 14 "_4x4_Off_Road_Mode" 10 "_4x4_Locked_Temporarily" 9 "Shift_In_Progress" 13 "Blocked_Shift_Assist" 12 "_4x4_Auto_Restored" 11 "_4x4_Disabled_Temporarily" 7 "Out_of_4Low__Neutral" 6 "Out_of_4Low__Brake" 5 "Out_of_4Low__Speed" 4 "Into_4Low__Clutch" 3 "Into_4Low__Neutral" 2 "Into_4Low__Brake" 1 "Into_4Low__Speed" 0 "Normal__No_Message" 8 "Out_of_4Low__Clutch" ;
VAL_ 611 AwdLck_D_Stat 9 "Undefined" 8 "Under_External_Torque_Ctrl" 7 "Torque_Limited_by_Cmd" 6 "Fully_Locked_by_Cmd" 5 "Disabled" 4 "Warning" 3 "Fault" 2 "Inactive" 1 "Completely_Opened_by_Cmd" 0 "OK" ;
VAL_ 611 AwdSrvcRqd_B_Rq 1 "On" 0 "Off" ;
VAL_ 611 AwdDrvMde_D_Stat 7 "Faulty" 6 "NotAvailable" 5 "RockCrawl" 4 "Baja" 3 "MudAndSand" 2 "Weather" 1 "Sport" 0 "Normal" ;
VAL_ 611 NtrlTowAvail_B_Stat 1 "Available" 0 "NotAvailable" ;
VAL_ 611 AwdLck_Tq_Rq 4095 "Fault" 4094 "Unknown" ;
VAL_ 611 AwdOffRoadMode_D_Stats 3 "Invalid" 2 "Extreme_Off_Road" 1 "Off_Road" 0 "Normal_Mode" ;
VAL_ 611 AwdLoLamp_D_RqDsply 3 "Not_Used" 2 "Flash" 1 "On" 0 "Off" ;
VAL_ 611 AwdHiLamp_D_RqDsply 3 "Not_Used" 2 "Flash" 1 "On" 0 "Off" ;
VAL_ 611 AwdAutoLamp_D_RqDsply 3 "Not_Used" 2 "Flash" 1 "On" 0 "Off" ;
VAL_ 611 Awd2wdLamp_D_RqDsply 3 "Not_Used" 2 "Flash" 1 "On" 0 "Off" ;
VAL_ 611 AwdRnge_D_Actl 7 "Unknown" 6 "High_Range_2wd" 5 "High_Range_Auto" 4 "High_Range_Locked" 3 "Neutral" 2 "Low_Range_2wd" 1 "Low_Range_Auto" 0 "Low_Range_Locked" ;
VAL_ 90 TrnGsmNtmState_D_Actl 3 "Faulty" 2 "Neutral_Tow_Mode" 1 "Car_Wash_Mode" 0 "None" ;
VAL_ 90 DrQltyDrv_D_StatGsm 7 "Faulty" 6 "NoDataExists" 5 "NotUsed2" 4 "NotUsed1" 3 "ClosedDegraded" 2 "OpenDegraded" 1 "ClosedOkay" 0 "OpenOkay" ;
VAL_ 90 TrnBtsiOvrrd_B_Stat 1 "Override" 0 "Null" ;
VAL_ 90 GsmGearMsgTxt_D_Rq 3 "Message3" 2 "Message2" 1 "Message1" 0 "NoMessage" ;
VAL_ 90 TrnRng_D_RqGsm 15 "Fault" 14 "UnknownPosition" 13 "Undefined_2" 12 "Undefined_1" 11 "_6" 10 "_5" 9 "_4" 8 "_3" 7 "_2" 6 "_1" 5 "Low" 4 "Sport_DriveSport" 3 "Drive" 2 "Neutral" 1 "Reverse" 0 "Park" ;
VAL_ 90 PrkBrkActv_D_RqGsmGear 3 "NotUsed" 2 "RequestParkBrakeEngage" 1 "NoRequest" 0 "Null" ;
VAL_ 90 TrnValidGearRq_D_Stat 3 "Valid_Request" 2 "Valid_Degraded_Request" 1 "Invalid_Request" 0 "No_Request" ;
VAL_ 90 TrnGearButtn_U_Actl 255 "Fault" ;
VAL_ 90 TrnGearButtn_B_ActlR2 1 "Yes" 0 "No" ;
VAL_ 90 TrnGearButtn_B_ActlR1 1 "Yes" 0 "No" ;
VAL_ 90 TrnGearButtn_B_ActlR0 1 "Yes" 0 "No" ;
VAL_ 90 TrnGearButtn_B_ActlP2 1 "Yes" 0 "No" ;
VAL_ 90 TrnGearButtn_B_ActlP1 1 "Yes" 0 "No" ;
VAL_ 90 TrnGearButtn_B_ActlP0 1 "Yes" 0 "No" ;
VAL_ 90 TrnGearButtn_B_ActlN2 1 "Yes" 0 "No" ;
VAL_ 90 TrnGearButtn_B_ActlN1 1 "Yes" 0 "No" ;
VAL_ 90 TrnGearButtn_B_ActlN0 1 "Yes" 0 "No" ;
VAL_ 90 TrnGearButtn_B_ActlM2 1 "Yes" 0 "No" ;
VAL_ 90 TrnGearButtn_B_ActlM1 1 "Yes" 0 "No" ;
VAL_ 90 TrnGearButtn_B_ActlM0 1 "Yes" 0 "No" ;
VAL_ 90 TrnGearButtn_B_ActlD2 1 "Yes" 0 "No" ;
VAL_ 90 TrnGearButtn_B_ActlD1 1 "Yes" 0 "No" ;
VAL_ 90 TrnGearButtn_B_ActlD0 1 "Yes" 0 "No" ;
VAL_ 90 TrnGear_D_RqDrv 31 "Fault" 30 "NotUsed_25" 29 "NotUsed_24" 28 "NotUsed_23" 27 "NotUsed_22" 26 "NotUsed_21" 25 "NotUsed_20" 24 "NotUsed_19" 23 "NotUsed_18" 22 "NotUsed_17" 21 "Return_To_Park" 20 "NotUsed_15" 19 "NotUsed_14" 18 "NotUsed_13" 17 "NotUsed_12" 16 "Manual" 15 "Not_Used11" 14 "Not_Used10" 13 "NotUsed_9" 12 "NotUsed_8" 11 "NotUsed_7" 10 "NotUsed_6" 9 "NotUsed_5" 8 "Drive" 7 "NotUsed_4" 6 "NotUsed_3" 5 "NotUsed_2" 4 "Neutral" 3 "NotUsed_1" 2 "Reverse" 1 "Park" 0 "No_Gear" ;
VAL_ 90 BrkSwtchPos_B_ActlGsm 1 "Yes" 0 "No" ;
VAL_ 1109 eCallConfirmation 7 "Unused_2" 6 "CallComplete_DTMF_Timeout" 5 "eCall_Configured_Off" 4 "Call_Unsuccessful" 3 "Call_Cancelled" 2 "Call_Completed" 1 "Call_In_Progress" 0 "Normal" ;
VAL_ 92 TrnGearMsgTxt2_D_Rq 31 "Message31" 30 "Message30" 29 "Message29" 28 "Message28" 27 "Message27" 26 "Message26" 25 "Message25" 24 "Message24" 23 "Message23" 22 "Message22" 21 "Message21" 20 "Message20" 19 "Message19" 18 "Message18" 17 "Message17" 16 "Message16" 15 "Message15" 14 "Message14" 13 "Message13" 12 "Message12" 11 "Message11" 10 "Message10" 9 "Message9" 8 "Message8" 7 "Message7" 6 "Message6" 5 "Message5" 4 "Message4" 3 "Message3" 2 "Message2" 1 "Message1" 0 "NoMessage" ;
VAL_ 92 RaceTrakMde_D_Stat 3 "NotUsed" 2 "Available" 1 "NotAvailable" 0 "Null" ;
VAL_ 92 TrnLvrV_D_Rq 3 "Full_Speed" 2 "Aggressive" 1 "Normal" 0 "Quiet" ;
VAL_ 92 TrnSbwSysHlth_D_Actl 3 "OK" 2 "Degraded" 1 "No_Data_Exists" 0 "Faulty" ;
VAL_ 92 TrnGearNtmAllow_B_Stat 1 "Yes" 0 "No" ;
VAL_ 92 TrnDtpCmd_D_Actl 7 "NotUsed4" 6 "NotUsed3" 5 "NotUsed2" 4 "Relatch" 3 "Deploy" 2 "Self_Test" 1 "No_Command" 0 "NotUsed1" ;
VAL_ 92 GearSelLck_D_Rq 3 "PreventionBlocker" 2 "Unlock" 1 "Lock" 0 "Null" ;
VAL_ 92 TrnValidGear_D_Cnfm 3 "Accept" 2 "Reject" 1 "Internal_Request" 0 "No_Command" ;
VAL_ 92 TrnNtrlTowCmd_D_Actl 3 "NotUsed" 2 "Neutral_Tow_Entry" 1 "Car_Wash_Mode" 0 "Normal_Mode" ;
VAL_ 92 TrnGearCmd_Pc_ActlPt 1023 "Fault" ;
VAL_ 92 TrnGear_D_RqPt 7 "Fault" 6 "NotUsed" 5 "Manual" 4 "Drive" 3 "Neutral" 2 "Reverse" 1 "Park" 0 "No_Gear" ;
VAL_ 92 TrnCmdState_B_Actl 1 "Yes" 0 "No" ;
VAL_ 92 PrkBrkActv_D_RqTrnGear 3 "NotUsed2" 2 "RequestParkBrakeEngage" 1 "NoRequest" 0 "NotUsed1" ;
VAL_ 92 TrnGearMsgTxt_D_Rq 15 "Message_15" 14 "Message_14" 13 "Message_13" 12 "Message_12" 11 "Message_11" 10 "Message_10" 9 "Message_9" 8 "Message_8" 7 "Message_7" 6 "Message_6" 5 "Message_5" 4 "Message_4" 3 "Message_3" 2 "Message_2" 1 "Message_1" 0 "NoMessage" ;
VAL_ 359 PrplWhlRgenMn_Tq_Actl 8191 "Faulty" ;
VAL_ 359 ElPw_D_StatStrtStop 15 "NotUsed6" 14 "NotUsed5" 13 "NotUsed4" 12 "NotUsed3" 11 "NotUsed2" 10 "NotUsed1" 9 "Supported_Level_4" 8 "Supported_Level_3" 7 "Supported_Level_2" 6 "Supported_Level_1" 5 "Limited_Support" 4 "Fault_Limited" 3 "LV_Event_in_Progress" 2 "Not_Supported_Imminent" 1 "Supported_All" 0 "Not_Supported" ;
VAL_ 359 PrplWhlTot2_Tq_Actl 65535 "Fault" 65534 "NoDataExists" ;
VAL_ 359 LscmbbDeny_B_ActlPrpl 1 "Denied" 0 "Allowed" ;
VAL_ 359 LscmbbEngTqMn_B_Actl 1 "Engine_Braking_Activated" 0 "Engine_Braking_Off" ;
VAL_ 359 PwPckTq_D_Stat 3 "PwPckOn_TqAvailable" 2 "StartInPrgrss_TqNotAvail" 1 "PwPckOn_TqNotAvailable" 0 "PwPckOff_TqNotAvailable" ;
VAL_ 359 Eng_D_Stat 3 "NotUsed" 2 "EngAutoStopped" 1 "EngOn" 0 "EngOff" ;
VAL_ 359 PlgActvArb_B_Actl 1 "On" 0 "Off" ;
VAL_ 359 ElPw_D_Stat 7 "NotUsed_3" 6 "NotUsed_2" 5 "NotUsed_1" 4 "Fault_Limited" 3 "LV_Event_In_Progress" 2 "Not_Supported_Imminent" 1 "Supported" 0 "Not_Supported" ;
VAL_ 359 TrnAinTq_D_Qf 3 "OK" 2 "Not_Within_Specifications" 1 "No_Data_Exists" 0 "Faulty" ;
VAL_ 358 StopStrtStdby_D_Indic 6 "Telltale_On_Grey" 5 "Telltale_Struck_Out" 4 "Telltale_Flashing_Amber" 3 "Telltale_On_Amber" 2 "Telltale_Flashing_Green" 1 "Telltale_On_Green" 0 "Telltale_Off" 7 "NotUsed3" ;
VAL_ 358 StopStrtIODTxt_D_Rq 31 "Message31" 30 "Message30" 29 "Message29" 28 "Message28" 27 "Message27" 26 "Message26" 25 "Message25" 24 "Message24" 23 "Message23" 22 "Message22" 21 "Message21" 20 "Message20" 19 "Message19" 18 "Message18" 17 "Message17" 16 "Message16" 15 "Message15" 14 "Message14" 13 "Message13" 12 "Message12" 11 "Message11" 10 "Message10" 9 "Message9" 8 "Message8" 7 "Message7" 6 "Message6" 5 "Message5" 4 "Message4" 3 "Message3" 2 "Message2" 1 "Message1" 0 "NoMessage" ;
VAL_ 358 StopStrtDrvMde_D_Indic 3 "NotUsed" 2 "StartStop_IndirectDeselect" 1 "StopStart_Deselected" 0 "StopStart_Selected" ;
VAL_ 358 StopStrtMsgTxt_D_Rq 15 "Message_15" 14 "Message_14" 13 "Message_13" 12 "Message_12" 11 "Message_11" 10 "Message_10" 9 "Message_9" 8 "Message_8" 7 "Message_7" 6 "Message_6" 5 "Message_5" 4 "Message_4" 3 "Message_3" 2 "Message_2" 1 "Message_1" 0 "NoMessage" ;
VAL_ 358 OdoTripVerify_L_Actl 16777215 "Fault" ;
VAL_ 358 HiElPwInhbt_B_Stat 1 "Inhibit" 0 "No_Inibit" ;
VAL_ 358 AutoStopPtDelta_I_Est 255 "Fault" ;
VAL_ 1084 BattULoState_D_Qlty 3 "OK" 2 "Not_Within_Specifications" 1 "Eval_In_Progress" 0 "Fault" ;
VAL_ 1084 BSFault 1 "Fault" 0 "No_Fault" ;
VAL_ 1084 BattULo2_Te_Actl 127 "Fault" ;
VAL_ 1086 AwdPtu_Te_Actl 255 "Faulty" ;
VAL_ 1086 FuelPumpPwr_B_Rq 1 "On" 0 "Off" ;
VAL_ 1086 ElLoadCtl_D_Rq 7 "Unused3" 6 "Unused2" 5 "Unused1" 4 "HoldAllDrvrInvisibleLoads" 3 "StdDriverInvisibleLoadsOn" 2 "AllDriverInvisibleLoadsOn" 1 "All_Possible_Loads_Off" 0 "No_Request" ;
VAL_ 1085 PwSrcULoOvrTe_B_Actl 1 "Yes" 0 "No" ;
VAL_ 1085 PwSrcULoOn_B_Actl 1 "Operating" 0 "Not_Operating" ;
VAL_ 1085 PwSrcULoFalt_D_Stat 3 "Fault_No_Output" 2 "Fault_Reduced_Output" 1 "Fault_NonSpecific" 0 "No_Fault" ;
VAL_ 1085 PwSrcULoDcnnt_B_Stat 1 "Loose_or_Disconnected" 0 "Connected" ;
VAL_ 1085 PwSrcULo_Pc_Mx 255 "Fault" ;
VAL_ 1085 DcdcULo_U_Actl 255 "Fault" ;
VAL_ 1085 DcdcUHi_I_Actl 255 "Fault" ;
VAL_ 1085 PwSrcULo_I_Mx 255 "Fault" ;
VAL_ 1085 PwSrcULo_I_Actl 255 "Fault" ;
VAL_ 1085 DcdcUHi_U_Actl 1023 "Fault" 1022 "NoDataExists" ;
VAL_ 891 CabnSndAmb2_Db_Actl_UB 1 "Fresh_data" 0 "Unchanged_data" ;
VAL_ 891 CabnSndAmb2_Db_Actl 255 "Fault" ;
VAL_ 603 FuelCtlOpenLp_B_Inhbt 1 " Inhibit_FullPedal_Actions" 0 "Normal_Operation" ;
VAL_ 603 EngDiag_D_RqHtrn 7 "NotUsed4" 6 "NotUsed3" 5 "NotUsed2" 4 "NoUsed1" 3 "Eng_Diag_Cstdn" 2 "Eng_Diag_Run" 1 "Eng_Diag_Crank" 0 "Eng_Diag_Normal" ;
VAL_ 603 WhlDirAvgDrv_D_Actl 3 "Faulty" 2 "NoDataExists" 1 "Backward" 0 "Forward" ;
VAL_ 603 PrplTqMnRgen_B_Actl 1 "Yes" 0 "No" ;
VAL_ 603 EDrvTqMntrRconfg_D_Cmd 7 "OK" 6 "Disable_Cruise" 5 "NotUsed4" 4 "Supercreep" 3 "NotUsed3" 2 "NotUsed2" 1 "Engine_shutdown" 0 "NotUsed" ;
VAL_ 603 BattTracCnnct_D_Rq 3 "Undefined" 2 "Retain" 1 "Close" 0 "Open" ;
VAL_ 602 HtrnWarnLamp_B_Dsply 1 "On" 0 "Off" ;
VAL_ 602 HybPwLimOn_B_Stat 1 "Yes" 0 "No" ;
VAL_ 602 PwSrcULoMde_D_Rq 3 "BuckSpecial" 2 "ReverseBoost" 1 "ForwardBuck" 0 "Standby" ;
VAL_ 602 PtcHtrRun_B_Rq 1 "On" 0 "Off" ;
VAL_ 602 PwPckTqRdy_B_Dsply 1 "On" 0 "Off" ;
VAL_ 602 ObdEngStdy_B_Stat 1 "Yes" 0 "No" ;
VAL_ 602 BattTracRsrvSoc_Pc_Rq 16383 "Faulty" 16382 "NoDataExists" ;
VAL_ 602 EngStrtSrvc_B_Allw 1 "Yes" 0 "No" ;
VAL_ 587 BattTracClnt_Te_Actl 255 "Faulty" 254 "NoDataExists" ;
VAL_ 587 BattTracWarnLamp_B_Rq 1 "On" 0 "Off" ;
VAL_ 587 BattTracSrvcRqd_B_Rq 1 "On" 0 "Off" ;
VAL_ 1040 ElCmpr2Enbl_B_Rq 1 "Enable" 0 "Disable" ;
VAL_ 1040 BattTrac_I2_EstVsc 262143 "Faulty" 262142 "NoDataExists" ;
VAL_ 1040 ElCmprEnbl_B_Rq 1 "Enable" 0 "Disable" ;
VAL_ 1041 ElCmprPerfErr_D_Falt 3 "NotUsed" 2 "Pass" 1 "Fail" 0 "Not_Diagnose_Yet" ;
VAL_ 1041 ElCmprInnrErr_D_Falt 3 "NotUsed" 2 "Pass" 1 "Fail" 0 "Not_Diagnose_Yet" ;
VAL_ 1041 ElCmprLostComm_D_Falt 3 "NotUsed" 2 "Pass" 1 "Fail" 0 "Not_Diagnose_Yet" ;
VAL_ 1041 ElCmprOverLoad_D_Falt 3 "NotUsed" 2 "Pass" 1 "Fail" 0 "Not_Diagnose_Yet" ;
VAL_ 1041 ElCmprOverTe_D_Falt 3 "NotUsed" 2 "Pass" 1 "Fail" 0 "Not_Diagnose_Yet" ;
VAL_ 1041 ElCmprBattURng_D_Falt 3 "NotUsed" 2 "Pass" 1 "Fail" 0 "Not_Diagnose_Yet" ;
VAL_ 1041 ElCmprBattSysU_D_Falt 3 "NotUsed" 2 "Pass" 1 "Fail" 0 "Not_Diagnose_Yet" ;
VAL_ 1041 ElCmprSysU_D_Falt 3 "NotUsed" 2 "Pass" 1 "Fail" 0 "Not_Diagnose_Yet" ;
VAL_ 1041 ElCmprUHi_D_Stat 3 "Overvoltage" 2 "Undervoltage" 1 "InRange" 0 "Undetermined" ;
VAL_ 1041 ElCmprOverTe_D_Stat 3 "OverTempStop" 2 "OverTempWarning" 1 "Normal" 0 "Undefined" ;
VAL_ 1041 ElCmpr_N_Actl 255 "Invalid" ;
VAL_ 1041 ElCmpr_Pw_Actl 255 "Invalid" ;
VAL_ 1041 ElCmpr_D_Stat 7 "Signal_Invalid" 6 "Comp_Off_ActlSpd_Abnormal" 5 "Comp_Off_TrgtSpd_OutRange" 4 "Comp_Shutdown" 3 "Comp_Stopped_Self_Protect" 2 "Comp_Degraded" 1 "Comp_On" 0 "Comp_Off" ;
VAL_ 1088 TrlrRng_L_Dsply 8191 "Faulty" 8190 "NoDataExists" ;
VAL_ 1088 HvacPrecondRecirc_D_Rq 3 "Last_User_Setting" 2 "Auto" 1 "Recirc" 0 "Outside" ;
VAL_ 1088 HvacPrecondMode2_D_Rq 15 "NotUsed4" 14 "NotUsed3" 13 "NotUsed2" 12 "NotUsed1" 11 "Last_User_Settings" 10 "Auto" 9 "Max_Defrost" 8 "Windshield_Panel_Floor" 7 "Windshield_Panel" 6 "Windshield" 5 "Windshield_Floor" 4 "Floor" 3 "Panel_Floor" 2 "Panel" 1 "MAX_AC" 0 "Off" ;
VAL_ 1088 HvacPrecondBlwr2_D_Rq 15 "NotUsed6" 14 "NotUsed5" 13 "NotUsed4" 12 "NotUsed3" 11 "NotUsed2" 10 "NotUsed1" 9 "Last_User_Setting" 8 "Auto" 7 "Speed7" 6 "Speed6" 5 "Speed5" 4 "Speed4" 3 "Speed3" 2 "Speed2" 1 "Speed1" 0 "Off" ;
VAL_ 1088 HvacPrecondAC_D_Rq 3 "Last_User_Setting" 2 "Auto" 1 "On" 0 "Off" ;
VAL_ 1088 BattDcChrgRms_I_Lim 32767 "Faulty" 32766 "NoDataExists" ;
VAL_ 1088 BattChrgInhbt_D_Rq 3 "MaintainTargetSoc" 2 "NotUsed" 1 "InhibitChargingThermal" 0 "Enable_Charging" ;
VAL_ 1088 ChrgStat_D2_Dsply 15 "ChargeStopCommanded" 14 "ChargeStartCommanded" 13 "ChargeTargetReached" 12 "DriveConditioning" 11 "CabinPreconditioning" 10 "ChargingSystemMaintain" 9 "ChargingInductive" 8 "ChargingDCFastCharge" 7 "ChargingAC" 6 "ChargeScheduled" 5 "EvsePaused" 4 "EvseNotDetected" 3 "EvseNotCompatible" 2 "FaultOutsideCar" 1 "FaultInsideCar" 0 "NotReady" ;
VAL_ 1088 ChrgTMatch_B_Stat 1 "True" 0 "False" ;
VAL_ 871 BattElecPerf_D_Actl 7 "NotUsed" 6 "Hot_Batt_Severe_Lim_Perf" 5 "Hot_Batt_Reduced_Perf" 4 "Hot_Batt_Close_to_lim_Per" 3 "Cold_Batt_Severe_Lim_Perf" 2 "Cold_Batt_Reduced_Perf" 1 "Cold_Batt_Close_to_lim_Pe" 0 "Ok_no_message_displayed" ;
VAL_ 871 BattChrgTrgtLPt_T_Est 2047 "Faulty" 2046 "NoDataExists" ;
VAL_ 871 BattChrgTrgSocPt_T_Est 2047 "Faulty" 2046 "NoDataExists" ;
VAL_ 871 BattChrgCmpltPt_T_Est 2047 "Faulty" 2046 "NoDataExists" ;
VAL_ 871 DrvEffLvlIncDec_D_Cmd 3 "NotUsed" 2 "Decrease_Level_by_1" 1 "Increase_Level_by_1" 0 "Null_State" ;
VAL_ 869 PwrFlowTxt_D_Dsply 15 "NotUsed7" 14 "NotUsed6" 13 "NotUsed5" 12 "NotUsed4" 11 "Disply_Rgen_Chrg_Txt" 10 "Disp_Fast_Charge_Txt" 9 "Disp_Fast_Charge_Cmplt_Txt" 8 "Disp_Charge_Cmplt_Txt" 7 "Disp_Remote_Start_Txt" 6 "Disp_Eng_Drv_Txt" 5 "Disp_Elec_Drv_Txt" 4 "Disp_Idle_with_Chrg_Txt" 3 "Disp_Idle_Txt" 2 "Disp_Charg_HV_Batt_Txt" 1 "Disp_Hyb_Drive_Txt" 0 "No_Text" ;
VAL_ 869 EngOnMsg2_D_Dsply 14 "_0xE_to_1F_NotUsed" 12 "Battery_Temperature" 11 "Hill_Decent_Control" 10 "Fuel_Maintenance" 9 "Oil_Maintenance" 8 "Normal_Operation" 7 "Low_Gear" 6 "Batt_Charging" 5 "Engine_Cold" 4 "Neutral_Gear" 3 "Heater_Setting" 2 "High_Speed" 1 "Acceleration" 0 "No_Display" 13 "Drive_Mode_Selection" ;
VAL_ 869 EngOnMsg1_D_Dsply 14 "_0xE_to_1F_NotUsed" 12 "Battery_Temperature" 11 "Hill_Decent_Control" 10 "Fuel_Maintenance" 9 "Oil_Maintenance" 8 "Normal_Operation" 7 "Low_Gear" 6 "Batt_Charging" 5 "Engine_Cold" 4 "Neutral_Gear" 3 "Heater_Setting" 2 "High_Speed" 1 "Acceleration" 0 "No_Display" 13 "Drive_Mode_Selection" ;
VAL_ 869 FuelMaintMde_D_Dsply 3 "Feature_Not_Present" 2 "In_Fuel_Maint_Mode" 1 "Close_to_Fuel_Maint" 0 "OK" ;
VAL_ 869 RgenActv_B_Dsply 1 "On" 0 "Off" ;
VAL_ 869 EngOffTe_B_Dsply 1 "Eng_warm_engh_for_pd" 0 "Eng_not_warm_engh_for_pd" ;
VAL_ 869 EngActv_B_Dsply 1 "On" 0 "Off" ;
VAL_ 869 EffWhlThresOn_B_Dsply 1 "On" 0 "Off" ;
VAL_ 869 DchrgActv_B_Dsply 1 "On" 0 "Off" ;
VAL_ 869 ChrgActv_B_Dsply 1 "On" 0 "Off" ;
VAL_ 870 PolicePurstMde_B_Stat 1 "On" 0 "Off" ;
VAL_ 870 RngPerChrgInst_L_Dsply 4095 "Faulty" 4094 "NoDataExists" ;
VAL_ 870 ChkPlgtoStrt_D_Dsply 3 "NotUsed" 2 "Is_VehicleUnplugged_Prompt" 1 "Check_Plug_to_Start" 0 "No_Message_Display" ;
VAL_ 870 HybMdeLimMsgTxt_D_Rq 3 "Limited_Req_Full_Defrost" 2 "Limited_Climate_Defrost" 1 "Limited_System_Performance" 0 "Null" ;
VAL_ 870 HybMdeMsgTxt_D2_Rq 15 "NotUsed_4" 14 "NotUsed_3" 13 "NotUsed_2" 12 "NotUsed_1" 11 "EvOverride_Avail" 10 "EvLaterActv_EvAuto_NowAvai" 9 "EvNowActv_EvAuto_LaterAvai" 8 "EvAutoActv_EvNow_LaterAvai" 7 "EvAutoActv_NoOtherMdeAvail" 6 "EvChrgActv_EvAutoMdeAvail" 5 "EvAutoActv_EvChrgMdeAvail" 4 "EvChrgActv_AllPhevMdeAvail" 3 "EvLaterActv_AllPhevMdeAvai" 2 "EvNowActv_AllPhevMdeAvail" 1 "EvAutoActv_AllPhevMdeAvail" 0 "Null" ;
VAL_ 870 EngMdeMsgTxt_D_Rq 7 "NotUsed_3" 6 "NotUsed_2" 5 "NotUsed_1" 4 "Charge" 3 "GlowingCharge" 2 "Hybrid" 1 "Ev" 0 "NoMessage" ;
VAL_ 870 ShifOutNtrlMsgTxt_D_Rq 7 "Message7" 6 "Message6" 5 "Message5" 4 "Message4" 3 "Message3" 2 "Message2" 1 "Message1" 0 "NoMessage" ;
VAL_ 130 TrlrHitchLamp_D_Rqst 1 "On" 0 "Off" ;
VAL_ 130 SteEffort_D_Stat 7 "NotUsed_3" 6 "NotUsed_2" 5 "NotUsed_1" 4 "SpecialMode_2" 3 "SpecialMode_1" 2 "Comfort" 1 "Sport" 0 "Normal" ;
VAL_ 130 SteMdule_D_Stat 7 "NotUsed" 6 "EPAS_Failure3" 5 "EPAS_Failure2" 4 "System_Failure" 3 "EPAS_Shutdown" 2 "Normal_Op_Full_Assist" 1 "Normal_Op_Limited_Assist" 0 "EPAS_Initialization" ;
VAL_ 130 DrvSteActv_B_Stat 1 "Active" 0 "Inactive" ;
VAL_ 130 DrvSte_Tq_Actl 255 "Invalid" 254 "Unknown" ;
VAL_ 130 VehVTrlrAid_B_Rq 1 "Request" 0 "NoRequest" ;
VAL_ 130 SteMdule_U_Meas 255 "Invalid" ;
VAL_ 130 SteMdule_I_Est 4095 "Invalid" ;
VAL_ 130 EPAS_Failure 3 "SERVICE_POWER_STEERING_NOW" 2 "SERVICE_POWER_STEERING" 1 "POWER_STRG_ASSIST_FAULT" 0 "EPAS_OK_NO_MESSAGE" ;
VAL_ 130 SteeringColumnTorque 255 "Invalid" 254 "Unknown" ;
VAL_ 130 SAPPAngleControlStat6 1 "RequestedAngleNotReached" 0 "RequestedAngleCanBeReached" ;
VAL_ 130 SAPPAngleControlStat5 1 "StrgColTorqueExceed_EAROn" 0 "ExternalSigContentOKforEAC" ;
VAL_ 130 SAPPAngleControlStat4 1 "SpeedLimitExceededEAROn" 0 "ExternalSigContentOKforEAC" ;
VAL_ 130 SAPPAngleControlStat3 1 "EARactiveNoReverseEngage" 0 "ExternalSigContentOKforEAC" ;
VAL_ 130 SAPPAngleControlStat2 1 "Rel_ExtSteeringAngleReqx" 0 "NoRel_ExtSteeringAngleReqx" ;
VAL_ 130 SAPPAngleControlStat1 3 "Fault" 2 "Active" 1 "Open" 0 "Closed" ;
VAL_ 1076 CenterStackRing_D_Actl 3 "LimitedOn" 2 "On" 1 "Off" 0 "Null" ;
VAL_ 1076 CenterStackRing_D_Actl_UB 1 "Fresh_data" 0 "Unchanged_data" ;
VAL_ 1076 EngIdlShutDown_B_RqDrv_UB 1 "Fresh_data" 0 "Unchanged_data" ;
VAL_ 1076 EngIdlShutDown_B_RqDrv 1 "Inhibit" 0 "No_Inibit" ;
VAL_ 1076 OdoTripRx_B_Actl 1 "Yes" 0 "No" ;
VAL_ 1076 LscmbbEngTqMn_B_Rq_UB 1 "Fresh_data" 0 "Unchanged_data" ;
VAL_ 1076 LscmbbEngTqMn_B_Rq 1 "Engine_Braking" 0 "No_Engine_Braking" ;
VAL_ 1076 TirePReset_B_Rq_UB 1 "Fresh_data" 0 "Unchanged_data" ;
VAL_ 1076 DrTGate_D_Rq 3 "NotUsed" 2 "Closing" 1 "Opening" 0 "Not_Moving" ;
VAL_ 1076 DrTGate_D_Rq_UB 1 "Fresh_data" 0 "Unchanged_data" ;
VAL_ 1076 FUEL_SENSOR_NUM 1 "Dual_Sensors" 0 "Single_Sensor" ;
VAL_ 1076 TirePReset_B_Rq 1 "Reset" 0 "Null" ;
VAL_ 1072 ePRNDL_MODE_UB 1 "Fresh_data" 0 "Unchanged_data" ;
VAL_ 1072 NtrlTowMdeEnbl_B_RqDrv 1 "Yes" 0 "No" ;
VAL_ 1072 NtrlTowMdeEnbl_B_RqDrv_UB 1 "Fresh_data" 0 "Unchanged_data" ;
VAL_ 1072 Remote_Start_QuietMode_UB 1 "Fresh_data" 0 "Unchanged_data" ;
VAL_ 1072 Remote_Start_QuietMode 1 "Quiet" 0 "Not_Quiet" ;
VAL_ 1072 ParkDetect_Stat_UB 1 "Fresh_data" 0 "Unchanged_data" ;
VAL_ 1072 ParkDetect_Stat 1 "Park" 0 "Not_Park" ;
VAL_ 1072 TrlrLampCnnct_B_Actl_UB 1 "Fresh_data" 0 "Unchanged_data" ;
VAL_ 1072 StopLamp_B_RqTrlrBrk_UB 1 "Fresh_data" 0 "Unchanged_data" ;
VAL_ 1072 StopLamp_B_RqTrlrBrk 1 "Yes" 0 "No" ;
VAL_ 1072 OdometerMasterValue_UB 1 "Fresh_data" 0 "Unchanged_data" ;
VAL_ 1072 OdometerMasterValue 16777215 "Invalid" ;
VAL_ 1072 FrostWarn_D_Stat 3 "NotUsed" 2 "On_Amber" 1 "On_Red" 0 "Off" ;
VAL_ 1072 ReducedGuard_D_Rq_UB 1 "Fresh_data" 0 "Unchanged_data" ;
VAL_ 1072 ReducedGuard_D_Rq 3 "NotUsed" 2 "On" 1 "Off" 0 "Null" ;
VAL_ 1072 ePRNDL_MODE 1 "On" 0 "Off" ;
VAL_ 1072 EngOilLife_B_RqReset 1 "Yes" 0 "No" ;
VAL_ 1072 Outside_Air_Temp_Stat_UB 1 "Fresh_data" 0 "Unchanged_data" ;
VAL_ 1072 Outside_Air_Temp_Stat 255 "Invalid" 254 "Unknown" ;
VAL_ 1072 KeyTypeChngMykey_D_Rq_UB 1 "Fresh_data" 0 "Unchanged_data" ;
VAL_ 1072 KeyTypeChngMykey_D_Rq 3 "Search_PE_BackupSlot" 2 "Clear_All_MyKeys" 1 "Request_New_MyKey" 0 "None" ;
VAL_ 1072 TrlrLampCnnct_B_Actl 1 "Yes" 0 "No" ;
VAL_ 1067 BattULoAux_I_Actl 4095 "Faulty" ;
VAL_ 1067 BattULoAux_D_Qlty 3 "OK" 2 "Not_Within_Specifications" 1 "Eval_In_Progress" 0 "Faulty" ;
VAL_ 1067 BattULoAux_U_Actl 255 "Faulty" ;
VAL_ 1067 BattULoAux_B_Falt 1 "Fault" 0 "No_Fault" ;
VAL_ 588 BattTracSoc_Pc_Dsply 255 "Faulty" 254 "NoDataExists" ;
VAL_ 588 BattChrgRdyStat_D_Actl 7 "NotUsed2" 6 "NotUsed1" 5 "Faulted" 4 "ChargeComplete" 3 "Charging" 2 "BatteryChargeReady" 1 "ChargeWait" 0 "NotReady" ;
VAL_ 588 BattTracSoc2_Pc_Actl 16383 "Faulty" 16382 "NoDataExists" ;
VAL_ 588 BattTrac_Te_Actl 1023 "Fault" 1022 "Unknown" ;
VAL_ 122 VehStrtInhbt_B_RqBatt 1 "Yes" 0 "No" ;
VAL_ 122 BattTracOffFst_D_Actl 3 "Unexpected_Contactor_Open" 2 "Restraints_Impact_Event" 1 "Interlock_Open" 0 "Normal" ;
VAL_ 122 BattTracOff_B_Actl 1 "Yes" 0 "No" ;
VAL_ 122 BattTracMil_D_Rq 3 "Not_Used" 2 "Flash" 1 "On" 0 "Off" ;
VAL_ 122 BattTrac_U_Actl 1023 "Fault" 1022 "Unknown" ;
VAL_ 122 BattTrac_I_Actl 32767 "Fault" 32766 "Unknown" ;
VAL_ 806 ClimtCoolRear_B_Rq 1 "On" 0 "Off" ;
VAL_ 806 ClimtHeatRear_D_Rq 7 "NotUsed4" 6 "NotUsed3" 5 "HtrCoreClntFlwOnly" 4 "PtcHtrTestMde" 3 "Defrost_Defog" 2 "FastTempPullDownHeatingReq" 1 "OpportunisticHeatingReq" 0 "NoHeatingRequest" ;
VAL_ 806 SnowPlowMde_B_Enbl 1 "Enable" 0 "Disable" ;
VAL_ 806 WndwFrontHeat_B_Stat 1 "On" 0 "Off" ;
VAL_ 806 StopStrtDrvMde_B_RqBtn 1 "Pressed" 0 "Not_Pressed" ;
VAL_ 806 HtrCorePump_B_Rq 1 "On" 0 "Off" ;
VAL_ 806 ClimtHeat_D_Rq 7 "NotUsed4" 6 "NotUsed3" 5 "HtrCoreClntFlwOnly" 4 "PtcHtrTestMde" 3 "Defrost_Defog" 2 "FastTempPullDownHeatingReq" 1 "OpportunisticHeatingReq" 0 "NoHeatingRequest" ;
VAL_ 806 ClimtCool_D_Rq 7 "NotUsed4" 6 "NotUsed3" 5 "NotUsed2" 4 "ElACTestMde" 3 "Defrost_Defog" 2 "FastTempPullDownCoolReq" 1 "OpportunisticCoolingReq" 0 "NoCoolingRequest" ;
VAL_ 806 HvacEvap_Te_Actl 1023 "Fault" ;
VAL_ 806 HvacAirCond_B_Rq 1 "Yes" 0 "No" ;
VAL_ 806 ClimtDeltaLoad_Pw_Actl 63 "Faulty" 62 "NoDataExists" ;
VAL_ 806 ClimtPw_B_Rq 1 "Yes" 0 "No" ;
VAL_ 578 PtLatchActv_B_RqBcm 1 "On" 0 "Off" ;
VAL_ 578 immoSecureIdleMode 3 "NotUsed2" 2 "NotUsed1" 1 "Active" 0 "Inactive" ;
VAL_ 578 ReFuelSwtchStat_D_Actl 3 "NotUsed2" 2 "NotUsed1" 1 "On" 0 "Off" ;
VAL_ 578 FuelPumpPwr_D_Stat 7 "NotUsed3" 6 "NotUsed2" 5 "NotUsed1" 4 "Power_Off_Default" 3 "Power_Off_Command" 2 "Power_Off_Service" 1 "Power_Off_Impact" 0 "Power_On" ;
VAL_ 578 BattULo_U_Actl 255 "Fault" ;
VAL_ 578 PrkLckCtl_B_Enbl 1 "Enable" 0 "Disable" ;
VAL_ 578 PrkLckCtlMsgTxt_D_Rq 3 "BTSI_DI_3" 2 "BTSI_DI_2" 1 "BTSI_DI_1" 0 "Null_BTSI_DI" ;
VAL_ 578 BrkTrnShifLck_B_Stat 1 "Shift" 0 "NoShift" ;
VAL_ 578 PrkLckCtlUnlck_D_Stat 3 "Trans_And_Steer_Unlckd" 2 "Steering_Unlckd" 1 "Transmission_Unlckd" 0 "Null" ;
VAL_ 578 PrkLckCtlTow_B_Enbl 1 "Enable" 0 "Disable" ;
VAL_ 578 DriverCrankingReq 1 "Crank_Request" 0 "No_Crank_Request" ;
VAL_ 578 EngOff_T_Actl 65535 "Invalid" ;
VAL_ 578 DcacElPw_D_Rq 3 "NotUsed" 2 "AC_HighPower_Requested" 1 "AC_LowPower_Requested" 0 "AC_Power_NotRequested" ;
VAL_ 578 BattULo_I_Actl 16383 "Fault" ;
VAL_ 514 StrtrMtrCtlMsgTxt_D2_Rq 3 "NoRequestPcmStartingMsgCtl" 2 "ShiftToNeutralToStart" 1 "ShiftToParkToStart" 0 "NoRequestBcmStartingMsgCtl" ;
VAL_ 514 StrtrMtrDlyStrt_B_Stat 1 "Yes" 0 "No" ;
VAL_ 514 VehVTrlrAid_B_Avail 1 "Yes" 0 "No" ;
VAL_ 514 StrtrMtrCtlMsgTxt_D_Rq 7 "Start_In_Gear_Allowed" 6 "Pending_Start_Cancelled" 5 "Start_Pending_Please_Wait" 4 "Cranking_Limit_Exceeded" 3 "Press_Brk_and_Shift_to_P_N" 2 "Press_Clutch_and_Brake" 1 "Press_Clutch_To_Start" 0 "No_Display" ;
VAL_ 514 VehVActlEng_D_Qf 3 "OK" 2 "Not_Within_Specifications" 1 "No_Data_Exists" 0 "Faulty" ;
VAL_ 514 GearRvrse_D_Actl 7 "Fault" 6 "NotUsed_3" 5 "NotUsed_2" 4 "NotUsed_1" 3 "Active_confirmed" 2 "Active_not_confirmed" 1 "Inactive_confirmed" 0 "Inactive_not_confirmed" ;
VAL_ 1057 FohEng_D_Rq 3 "AutoEnable_ParkEnable" 2 "AutoDisable_ParkEnable" 1 "AutoEnable_ParkDisable" 0 "Disable_Stop" ;
VAL_ 1057 EngIdlShutDwnTxt_D_Rq 3 "NotUsed" 2 "EngineShutdownOnPrevDrive" 1 "FeatureDisabledDueToFault" 0 "NoMessage" ;
VAL_ 1057 EngIdlShutDown_D_Stat 3 "Not_used" 2 "Engine_Shutdown" 1 "Initiated_Countdown" 0 "Normal_Operation" ;
VAL_ 1057 FUEL_ALCOHOL_PERCNT 255 "Invalid" ;
VAL_ 1057 TrnTotTq_Rt_Est 65535 "Fault" 65534 "Unknown" ;
VAL_ 1057 TrnTotLss_Tq_Est 255 "Fault" 254 "Unknown" ;
VAL_ 1057 ECMMILRequest 3 "Not_Used" 2 "Flash" 1 "On" 0 "Off" ;
VAL_ 1057 AirCondFluidHi_P_Actl 255 "Fault" 254 "Unknown" ;
VAL_ 1057 OilPressureWarning 1 "Low_Pressure_Lamp_On" 0 "Normal_Pressure_Lamp_Off" ;
VAL_ 1057 VehVLimStat_D_Actl 7 "Undefined_3" 6 "Undefined_2" 5 "Undefined_1" 4 "ASL_Fault_Condition" 3 "Active_and_Limiting" 2 "Active_but_Not_Limiting" 1 "Standby" 0 "Off" ;
VAL_ 1057 VehVLimActv_B_Actl 1 "Active" 0 "Inactive" ;
VAL_ 1057 CoolantFanStepAct 31 "Unused7" 30 "Unused6" 29 "Unused5" 28 "Unused4" 27 "Unused3" 26 "Unused2" 25 "Unused1" 23 "Step23" 22 "Step22" 21 "Step21" 20 "Step20" 19 "Step19" 18 "Step18" 17 "Step17" 16 "Step16" 15 "Step15" 14 "Step14" 13 "Step13" 12 "Step12" 11 "Step11" 10 "Step10" 9 "Step9" 8 "Step8" 7 "Step7" 6 "Step6" 5 "Step5" 4 "Step4" 3 "Step3" 2 "Step2" 1 "Step1" 24 "Max_Fan_Speed_Req" 0 "Fan_Cmd_Off" ;
